[part 3 of 11: package /CANAnalyzer/CommunicationClusters]
AUTOSAR XML (schema 00051)
package /CANAnalyzer/CommunicationClusters  (continued)
  can cluster CAN_FD_IPB_41  (continued)
    can physical channel Channel  (continued)
      frame SeamlessBLEStatusFBD_HM: id 0x10F, frame-length=20, can-addressing-mode=STANDARD, can-frame-rx-behavior=CAN-FD, can-frame-tx-behavior=CAN-FD
        pdu SeamlessBLEStatusFBD_HM: length=20, unused-bit-pattern=0
          signal SeamlessBLEStatusFBD_HM_NumberActiveConnections: start 0, 8 bit, little-endian, data-type-policy=OVERRIDE, base-type=uint8, compu {phys=raw}, range phys 0..252
          signal SeamlessBLEStatusFBD_HM_ConnectionID1: start 8, 8 bit, little-endian, data-type-policy=OVERRIDE, base-type=uint8, compu {phys=raw}, range phys 0..252
          signal SeamlessBLEStatusFBD_HM_ConnectionRSSI1: start 16, 8 bit, little-endian, data-type-policy=OVERRIDE, base-type=uint8, compu {phys=raw*0.5-127; unit dB}, range phys -127..-1
          signal SeamlessBLEStatusFBD_HM_ConnectionID2: start 24, 8 bit, little-endian, data-type-policy=OVERRIDE, base-type=uint8, compu {phys=raw}, range phys 0..252
          signal SeamlessBLEStatusFBD_HM_ConnectionRSSI2: start 32, 8 bit, little-endian, data-type-policy=OVERRIDE, base-type=uint8, compu {phys=raw*0.5-127; unit dB}, range phys -127..-1
          signal SeamlessBLEStatusFBD_HM_ConnectionID3: start 40, 8 bit, little-endian, data-type-policy=OVERRIDE, base-type=uint8, compu {phys=raw}, range phys 0..252
          signal SeamlessBLEStatusFBD_HM_ConnectionRSSI3: start 48, 8 bit, little-endian, data-type-policy=OVERRIDE, base-type=uint8, compu {phys=raw*0.5-127; unit dB}, range phys -127..-1
          signal SeamlessBLEStatusFBD_HM_ConnectionID4: start 56, 8 bit, little-endian, data-type-policy=OVERRIDE, base-type=uint8, compu {phys=raw}, range phys 0..252
          signal SeamlessBLEStatusFBD_HM_ConnectionRSSI4: start 64, 8 bit, little-endian, data-type-policy=OVERRIDE, base-type=uint8, compu {phys=raw*0.5-127; unit dB}, range phys -127..-1
          signal SeamlessBLEStatusFBD_HM_ConnectionID5: start 72, 8 bit, little-endian, data-type-policy=OVERRIDE, base-type=uint8, compu {phys=raw}, range phys 0..252
          signal SeamlessBLEStatusFBD_HM_ConnectionRSSI5: start 80, 8 bit, little-endian, data-type-policy=OVERRIDE, base-type=uint8, compu {phys=raw*0.5-127; unit dB}, range phys -127..-1
          signal SeamlessBLEStatusFBD_HM_ConnectionID6: start 88, 8 bit, little-endian, data-type-policy=OVERRIDE, base-type=uint8, compu {phys=raw}, range phys 0..252
          signal SeamlessBLEStatusFBD_HM_ConnectionRSSI6: start 96, 8 bit, little-endian, data-type-policy=OVERRIDE, base-type=uint8, compu {phys=raw*0.5-127; unit dB}, range phys -127..-1
          signal SeamlessBLEStatusFBD_HM_ConnectionID7: start 104, 8 bit, little-endian, data-type-policy=OVERRIDE, base-type=uint8, compu {phys=raw}, range phys 0..252
          signal SeamlessBLEStatusFBD_HM_ConnectionRSSI7: start 112, 8 bit, little-endian, data-type-policy=OVERRIDE, base-type=uint8, compu {phys=raw*0.5-127; unit dB}, range phys -127..-1
          signal SeamlessBLEStatusFBD_HM_ConnectionID8: start 120, 8 bit, little-endian, data-type-policy=OVERRIDE, base-type=uint8, compu {phys=raw}, range phys 0..252
          signal SeamlessBLEStatusFBD_HM_ConnectionRSSI8: start 128, 8 bit, little-endian, data-type-policy=OVERRIDE, base-type=uint8, compu {phys=raw*0.5-127; unit dB}, range phys -127..-1
      frame SeamlessBLEStatusFBD_HR: id 0x115, frame-length=20, can-addressing-mode=STANDARD, can-frame-rx-behavior=CAN-FD, can-frame-tx-behavior=CAN-FD
        pdu SeamlessBLEStatusFBD_HR: length=20, unused-bit-pattern=0
          signal SeamlessBLEStatusFBD_HR_NumberActiveConnections: start 0, 8 bit, little-endian, data-type-policy=OVERRIDE, base-type=uint8, compu {phys=raw}, range phys 0..252
          signal SeamlessBLEStatusFBD_HR_ConnectionID1: start 8, 8 bit, little-endian, data-type-policy=OVERRIDE, base-type=uint8, compu {phys=raw}, range phys 0..252
          signal SeamlessBLEStatusFBD_HR_ConnectionRSSI1: start 16, 8 bit, little-endian, data-type-policy=OVERRIDE, base-type=uint8, compu {phys=raw*0.5-127; unit dB}, range phys -127..-1
          signal SeamlessBLEStatusFBD_HR_ConnectionID2: start 24, 8 bit, little-endian, data-type-policy=OVERRIDE, base-type=uint8, compu {phys=raw}, range phys 0..252
          signal SeamlessBLEStatusFBD_HR_ConnectionRSSI2: start 32, 8 bit, little-endian, data-type-policy=OVERRIDE, base-type=uint8, compu {phys=raw*0.5-127; unit dB}, range phys -127..-1
          signal SeamlessBLEStatusFBD_HR_ConnectionID3: start 40, 8 bit, little-endian, data-type-policy=OVERRIDE, base-type=uint8, compu {phys=raw}, range phys 0..252
          signal SeamlessBLEStatusFBD_HR_ConnectionRSSI3: start 48, 8 bit, little-endian, data-type-policy=OVERRIDE, base-type=uint8, compu {phys=raw*0.5-127; unit dB}, range phys -127..-1
          signal SeamlessBLEStatusFBD_HR_ConnectionID4: start 56, 8 bit, little-endian, data-type-policy=OVERRIDE, base-type=uint8, compu {phys=raw}, range phys 0..252
          signal SeamlessBLEStatusFBD_HR_ConnectionRSSI4: start 64, 8 bit, little-endian, data-type-policy=OVERRIDE, base-type=uint8, compu {phys=raw*0.5-127; unit dB}, range phys -127..-1
          signal SeamlessBLEStatusFBD_HR_ConnectionID5: start 72, 8 bit, little-endian, data-type-policy=OVERRIDE, base-type=uint8, compu {phys=raw}, range phys 0..252
          signal SeamlessBLEStatusFBD_HR_ConnectionRSSI5: start 80, 8 bit, little-endian, data-type-policy=OVERRIDE, base-type=uint8, compu {phys=raw*0.5-127; unit dB}, range phys -127..-1
          signal SeamlessBLEStatusFBD_HR_ConnectionID6: start 88, 8 bit, little-endian, data-type-policy=OVERRIDE, base-type=uint8, compu {phys=raw}, range phys 0..252
          signal SeamlessBLEStatusFBD_HR_ConnectionRSSI6: start 96, 8 bit, little-endian, data-type-policy=OVERRIDE, base-type=uint8, compu {phys=raw*0.5-127; unit dB}, range phys -127..-1
          signal SeamlessBLEStatusFBD_HR_ConnectionID7: start 104, 8 bit, little-endian, data-type-policy=OVERRIDE, base-type=uint8, compu {phys=raw}, range phys 0..252
          signal SeamlessBLEStatusFBD_HR_ConnectionRSSI7: start 112, 8 bit, little-endian, data-type-policy=OVERRIDE, base-type=uint8, compu {phys=raw*0.5-127; unit dB}, range phys -127..-1
          signal SeamlessBLEStatusFBD_HR_ConnectionID8: start 120, 8 bit, little-endian, data-type-policy=OVERRIDE, base-type=uint8, compu {phys=raw}, range phys 0..252
          signal SeamlessBLEStatusFBD_HR_ConnectionRSSI8: start 128, 8 bit, little-endian, data-type-policy=OVERRIDE, base-type=uint8, compu {phys=raw*0.5-127; unit dB}, range phys -127..-1
      frame SeamlessBLEStatusFBD_Miko: id 0x110, frame-length=20, can-addressing-mode=STANDARD, can-frame-rx-behavior=CAN-FD, can-frame-tx-behavior=CAN-FD
        pdu SeamlessBLEStatusFBD_Miko: length=20, unused-bit-pattern=0
          signal SeamlessBLEStatusFBD_Miko_NumberActiveConnections: start 0, 8 bit, little-endian, data-type-policy=OVERRIDE, base-type=uint8, compu {phys=raw}, range phys 0..252
          signal SeamlessBLEStatusFBD_Miko_ConnectionID1: start 8, 8 bit, little-endian, data-type-policy=OVERRIDE, base-type=uint8, compu {phys=raw}, range phys 0..252
          signal SeamlessBLEStatusFBD_Miko_ConnectionRSSI1: start 16, 8 bit, little-endian, data-type-policy=OVERRIDE, base-type=uint8, compu {phys=raw*0.5-127; unit dB}, range phys -127..-1
          signal SeamlessBLEStatusFBD_Miko_ConnectionID2: start 24, 8 bit, little-endian, data-type-policy=OVERRIDE, base-type=uint8, compu {phys=raw}, range phys 0..252
          signal SeamlessBLEStatusFBD_Miko_ConnectionRSSI2: start 32, 8 bit, little-endian, data-type-policy=OVERRIDE, base-type=uint8, compu {phys=raw*0.5-127; unit dB}, range phys -127..-1
          signal SeamlessBLEStatusFBD_Miko_ConnectionID3: start 40, 8 bit, little-endian, data-type-policy=OVERRIDE, base-type=uint8, compu {phys=raw}, range phys 0..252
          signal SeamlessBLEStatusFBD_Miko_ConnectionRSSI3: start 48, 8 bit, little-endian, data-type-policy=OVERRIDE, base-type=uint8, compu {phys=raw*0.5-127; unit dB}, range phys -127..-1
          signal SeamlessBLEStatusFBD_Miko_ConnectionID4: start 56, 8 bit, little-endian, data-type-policy=OVERRIDE, base-type=uint8, compu {phys=raw}, range phys 0..252
          signal SeamlessBLEStatusFBD_Miko_ConnectionRSSI4: start 64, 8 bit, little-endian, data-type-policy=OVERRIDE, base-type=uint8, compu {phys=raw*0.5-127; unit dB}, range phys -127..-1
          signal SeamlessBLEStatusFBD_Miko_ConnectionID5: start 72, 8 bit, little-endian, data-type-policy=OVERRIDE, base-type=uint8, compu {phys=raw}, range phys 0..252
          signal SeamlessBLEStatusFBD_Miko_ConnectionRSSI5: start 80, 8 bit, little-endian, data-type-policy=OVERRIDE, base-type=uint8, compu {phys=raw*0.5-127; unit dB}, range phys -127..-1
          signal SeamlessBLEStatusFBD_Miko_ConnectionID6: start 88, 8 bit, little-endian, data-type-policy=OVERRIDE, base-type=uint8, compu {phys=raw}, range phys 0..252
          signal SeamlessBLEStatusFBD_Miko_ConnectionRSSI6: start 96, 8 bit, little-endian, data-type-policy=OVERRIDE, base-type=uint8, compu {phys=raw*0.5-127; unit dB}, range phys -127..-1
          signal SeamlessBLEStatusFBD_Miko_ConnectionID7: start 104, 8 bit, little-endian, data-type-policy=OVERRIDE, base-type=uint8, compu {phys=raw}, range phys 0..252
          signal SeamlessBLEStatusFBD_Miko_ConnectionRSSI7: start 112, 8 bit, little-endian, data-type-policy=OVERRIDE, base-type=uint8, compu {phys=raw*0.5-127; unit dB}, range phys -127..-1
          signal SeamlessBLEStatusFBD_Miko_ConnectionID8: start 120, 8 bit, little-endian, data-type-policy=OVERRIDE, base-type=uint8, compu {phys=raw}, range phys 0..252
          signal SeamlessBLEStatusFBD_Miko_ConnectionRSSI8: start 128, 8 bit, little-endian, data-type-policy=OVERRIDE, base-type=uint8, compu {phys=raw*0.5-127; unit dB}, range phys -127..-1
      frame SeamlessBLEStatusFBD_MM: id 0x336, frame-length=20, can-addressing-mode=STANDARD, can-frame-rx-behavior=CAN-FD, can-frame-tx-behavior=CAN-FD
        pdu SeamlessBLEStatusFBD_MM: length=20, unused-bit-pattern=0
          signal SeamlessBLEStatusFBD_MM_NumberActiveConnections: start 0, 8 bit, little-endian, data-type-policy=OVERRIDE, base-type=uint8, compu {phys=raw}, range phys 0..252
          signal SeamlessBLEStatusFBD_MM_ConnectionID1: start 8, 8 bit, little-endian, data-type-policy=OVERRIDE, base-type=uint8, compu {phys=raw}, range phys 0..252
          signal SeamlessBLEStatusFBD_MM_ConnectionRSSI1: start 16, 8 bit, little-endian, data-type-policy=OVERRIDE, base-type=uint8, compu {phys=raw*0.5-127; unit dB}, range phys -127..-1
          signal SeamlessBLEStatusFBD_MM_ConnectionID2: start 24, 8 bit, little-endian, data-type-policy=OVERRIDE, base-type=uint8, compu {phys=raw}, range phys 0..252
          signal SeamlessBLEStatusFBD_MM_ConnectionRSSI2: start 32, 8 bit, little-endian, data-type-policy=OVERRIDE, base-type=uint8, compu {phys=raw*0.5-127; unit dB}, range phys -127..-1
          signal SeamlessBLEStatusFBD_MM_ConnectionID3: start 40, 8 bit, little-endian, data-type-policy=OVERRIDE, base-type=uint8, compu {phys=raw}, range phys 0..252
          signal SeamlessBLEStatusFBD_MM_ConnectionRSSI3: start 48, 8 bit, little-endian, data-type-policy=OVERRIDE, base-type=uint8, compu {phys=raw*0.5-127; unit dB}, range phys -127..-1
          signal SeamlessBLEStatusFBD_MM_ConnectionID4: start 56, 8 bit, little-endian, data-type-policy=OVERRIDE, base-type=uint8, compu {phys=raw}, range phys 0..252
          signal SeamlessBLEStatusFBD_MM_ConnectionRSSI4: start 64, 8 bit, little-endian, data-type-policy=OVERRIDE, base-type=uint8, compu {phys=raw*0.5-127; unit dB}, range phys -127..-1
          signal SeamlessBLEStatusFBD_MM_ConnectionID5: start 72, 8 bit, little-endian, data-type-policy=OVERRIDE, base-type=uint8, compu {phys=raw}, range phys 0..252
          signal SeamlessBLEStatusFBD_MM_ConnectionRSSI5: start 80, 8 bit, little-endian, data-type-policy=OVERRIDE, base-type=uint8, compu {phys=raw*0.5-127; unit dB}, range phys -127..-1
          signal SeamlessBLEStatusFBD_MM_ConnectionID6: start 88, 8 bit, little-endian, data-type-policy=OVERRIDE, base-type=uint8, compu {phys=raw}, range phys 0..252
          signal SeamlessBLEStatusFBD_MM_ConnectionRSSI6: start 96, 8 bit, little-endian, data-type-policy=OVERRIDE, base-type=uint8, compu {phys=raw*0.5-127; unit dB}, range phys -127..-1
          signal SeamlessBLEStatusFBD_MM_ConnectionID7: start 104, 8 bit, little-endian, data-type-policy=OVERRIDE, base-type=uint8, compu {phys=raw}, range phys 0..252
          signal SeamlessBLEStatusFBD_MM_ConnectionRSSI7: start 112, 8 bit, little-endian, data-type-policy=OVERRIDE, base-type=uint8, compu {phys=raw*0.5-127; unit dB}, range phys -127..-1
          signal SeamlessBLEStatusFBD_MM_ConnectionID8: start 120, 8 bit, little-endian, data-type-policy=OVERRIDE, base-type=uint8, compu {phys=raw}, range phys 0..252
          signal SeamlessBLEStatusFBD_MM_ConnectionRSSI8: start 128, 8 bit, little-endian, data-type-policy=OVERRIDE, base-type=uint8, compu {phys=raw*0.5-127; unit dB}, range phys -127..-1
      frame SeamlessBLEStatusFBD_Trunk: id 0x111, frame-length=20, can-addressing-mode=STANDARD, can-frame-rx-behavior=CAN-FD, can-frame-tx-behavior=CAN-FD
        pdu SeamlessBLEStatusFBD_Trunk: length=20, unused-bit-pattern=0
          signal SeamlessBLEStatusFBD_Trunk_NumberActiveConnections: start 0, 8 bit, little-endian, data-type-policy=OVERRIDE, base-type=uint8, compu {phys=raw}, range phys 0..252
          signal SeamlessBLEStatusFBD_Trunk_ConnectionID1: start 8, 8 bit, little-endian, data-type-policy=OVERRIDE, base-type=uint8, compu {phys=raw}, range phys 0..252
          signal SeamlessBLEStatusFBD_Trunk_ConnectionRSSI1: start 16, 8 bit, little-endian, data-type-policy=OVERRIDE, base-type=uint8, compu {phys=raw*0.5-127; unit dB}, range phys -127..-1
          signal SeamlessBLEStatusFBD_Trunk_ConnectionID2: start 24, 8 bit, little-endian, data-type-policy=OVERRIDE, base-type=uint8, compu {phys=raw}, range phys 0..252
          signal SeamlessBLEStatusFBD_Trunk_ConnectionRSSI2: start 32, 8 bit, little-endian, data-type-policy=OVERRIDE, base-type=uint8, compu {phys=raw*0.5-127; unit dB}, range phys -127..-1
          signal SeamlessBLEStatusFBD_Trunk_ConnectionID3: start 40, 8 bit, little-endian, data-type-policy=OVERRIDE, base-type=uint8, compu {phys=raw}, range phys 0..252
          signal SeamlessBLEStatusFBD_Trunk_ConnectionRSSI3: start 48, 8 bit, little-endian, data-type-policy=OVERRIDE, base-type=uint8, compu {phys=raw*0.5-127; unit dB}, range phys -127..-1
          signal SeamlessBLEStatusFBD_Trunk_ConnectionID4: start 56, 8 bit, little-endian, data-type-policy=OVERRIDE, base-type=uint8, compu {phys=raw}, range phys 0..252
          signal SeamlessBLEStatusFBD_Trunk_ConnectionRSSI4: start 64, 8 bit, little-endian, data-type-policy=OVERRIDE, base-type=uint8, compu {phys=raw*0.5-127; unit dB}, range phys -127..-1
          signal SeamlessBLEStatusFBD_Trunk_ConnectionID5: start 72, 8 bit, little-endian, data-type-policy=OVERRIDE, base-type=uint8, compu {phys=raw}, range phys 0..252
          signal SeamlessBLEStatusFBD_Trunk_ConnectionRSSI5: start 80, 8 bit, little-endian, data-type-policy=OVERRIDE, base-type=uint8, compu {phys=raw*0.5-127; unit dB}, range phys -127..-1
          signal SeamlessBLEStatusFBD_Trunk_ConnectionID6: start 88, 8 bit, little-endian, data-type-policy=OVERRIDE, base-type=uint8, compu {phys=raw}, range phys 0..252
          signal SeamlessBLEStatusFBD_Trunk_ConnectionRSSI6: start 96, 8 bit, little-endian, data-type-policy=OVERRIDE, base-type=uint8, compu {phys=raw*0.5-127; unit dB}, range phys -127..-1
          signal SeamlessBLEStatusFBD_Trunk_ConnectionID7: start 104, 8 bit, little-endian, data-type-policy=OVERRIDE, base-type=uint8, compu {phys=raw}, range phys 0..252
          signal SeamlessBLEStatusFBD_Trunk_ConnectionRSSI7: start 112, 8 bit, little-endian, data-type-policy=OVERRIDE, base-type=uint8, compu {phys=raw*0.5-127; unit dB}, range phys -127..-1
          signal SeamlessBLEStatusFBD_Trunk_ConnectionID8: start 120, 8 bit, little-endian, data-type-policy=OVERRIDE, base-type=uint8, compu {phys=raw}, range phys 0..252
          signal SeamlessBLEStatusFBD_Trunk_ConnectionRSSI8: start 128, 8 bit, little-endian, data-type-policy=OVERRIDE, base-type=uint8, compu {phys=raw*0.5-127; unit dB}, range phys -127..-1
      frame SeamlessBLEStatusFBD_VL: id 0x112, frame-length=20, can-addressing-mode=STANDARD, can-frame-rx-behavior=CAN-FD, can-frame-tx-behavior=CAN-FD
        pdu SeamlessBLEStatusFBD_VL: length=20, unused-bit-pattern=0
          signal SeamlessBLEStatusFBD_VL_NumberActiveConnections: start 0, 8 bit, little-endian, data-type-policy=OVERRIDE, base-type=uint8, compu {phys=raw}, range phys 0..252
          signal SeamlessBLEStatusFBD_VL_ConnectionID1: start 8, 8 bit, little-endian, data-type-policy=OVERRIDE, base-type=uint8, compu {phys=raw}, range phys 0..252
          signal SeamlessBLEStatusFBD_VL_ConnectionRSSI1: start 16, 8 bit, little-endian, data-type-policy=OVERRIDE, base-type=uint8, compu {phys=raw*0.5-127; unit dB}, range phys -127..-1
          signal SeamlessBLEStatusFBD_VL_ConnectionID2: start 24, 8 bit, little-endian, data-type-policy=OVERRIDE, base-type=uint8, compu {phys=raw}, range phys 0..252
          signal SeamlessBLEStatusFBD_VL_ConnectionRSSI2: start 32, 8 bit, little-endian, data-type-policy=OVERRIDE, base-type=uint8, compu {phys=raw*0.5-127; unit dB}, range phys -127..-1
          signal SeamlessBLEStatusFBD_VL_ConnectionID3: start 40, 8 bit, little-endian, data-type-policy=OVERRIDE, base-type=uint8, compu {phys=raw}, range phys 0..252
          signal SeamlessBLEStatusFBD_VL_ConnectionRSSI3: start 48, 8 bit, little-endian, data-type-policy=OVERRIDE, base-type=uint8, compu {phys=raw*0.5-127; unit dB}, range phys -127..-1
          signal SeamlessBLEStatusFBD_VL_ConnectionID4: start 56, 8 bit, little-endian, data-type-policy=OVERRIDE, base-type=uint8, compu {phys=raw}, range phys 0..252
          signal SeamlessBLEStatusFBD_VL_ConnectionRSSI4: start 64, 8 bit, little-endian, data-type-policy=OVERRIDE, base-type=uint8, compu {phys=raw*0.5-127; unit dB}, range phys -127..-1
          signal SeamlessBLEStatusFBD_VL_ConnectionID5: start 72, 8 bit, little-endian, data-type-policy=OVERRIDE, base-type=uint8, compu {phys=raw}, range phys 0..252
          signal SeamlessBLEStatusFBD_VL_ConnectionRSSI5: start 80, 8 bit, little-endian, data-type-policy=OVERRIDE, base-type=uint8, compu {phys=raw*0.5-127; unit dB}, range phys -127..-1
          signal SeamlessBLEStatusFBD_VL_ConnectionID6: start 88, 8 bit, little-endian, data-type-policy=OVERRIDE, base-type=uint8, compu {phys=raw}, range phys 0..252
          signal SeamlessBLEStatusFBD_VL_ConnectionRSSI6: start 96, 8 bit, little-endian, data-type-policy=OVERRIDE, base-type=uint8, compu {phys=raw*0.5-127; unit dB}, range phys -127..-1
          signal SeamlessBLEStatusFBD_VL_ConnectionID7: start 104, 8 bit, little-endian, data-type-policy=OVERRIDE, base-type=uint8, compu {phys=raw}, range phys 0..252
          signal SeamlessBLEStatusFBD_VL_ConnectionRSSI7: start 112, 8 bit, little-endian, data-type-policy=OVERRIDE, base-type=uint8, compu {phys=raw*0.5-127; unit dB}, range phys -127..-1
          signal SeamlessBLEStatusFBD_VL_ConnectionID8: start 120, 8 bit, little-endian, data-type-policy=OVERRIDE, base-type=uint8, compu {phys=raw}, range phys 0..252
          signal SeamlessBLEStatusFBD_VL_ConnectionRSSI8: start 128, 8 bit, little-endian, data-type-policy=OVERRIDE, base-type=uint8, compu {phys=raw*0.5-127; unit dB}, range phys -127..-1
      frame SeamlessBLEStatusFBD_VM: id 0x10E, frame-length=20, can-addressing-mode=STANDARD, can-frame-rx-behavior=CAN-FD, can-frame-tx-behavior=CAN-FD
        pdu SeamlessBLEStatusFBD_VM: length=20, unused-bit-pattern=0
          signal SeamlessBLEStatusFBD_VM_NumberActiveConnections: start 0, 8 bit, little-endian, data-type-policy=OVERRIDE, base-type=uint8, compu {phys=raw}, range phys 0..252
          signal SeamlessBLEStatusFBD_VM_ConnectionID1: start 8, 8 bit, little-endian, data-type-policy=OVERRIDE, base-type=uint8, compu {phys=raw}, range phys 0..252
          signal SeamlessBLEStatusFBD_VM_ConnectionRSSI1: start 16, 8 bit, little-endian, data-type-policy=OVERRIDE, base-type=uint8, compu {phys=raw*0.5-127; unit dB}, range phys -127..-1
          signal SeamlessBLEStatusFBD_VM_ConnectionID2: start 24, 8 bit, little-endian, data-type-policy=OVERRIDE, base-type=uint8, compu {phys=raw}, range phys 0..252
          signal SeamlessBLEStatusFBD_VM_ConnectionRSSI2: start 32, 8 bit, little-endian, data-type-policy=OVERRIDE, base-type=uint8, compu {phys=raw*0.5-127; unit dB}, range phys -127..-1
          signal SeamlessBLEStatusFBD_VM_ConnectionID3: start 40, 8 bit, little-endian, data-type-policy=OVERRIDE, base-type=uint8, compu {phys=raw}, range phys 0..252
          signal SeamlessBLEStatusFBD_VM_ConnectionRSSI3: start 48, 8 bit, little-endian, data-type-policy=OVERRIDE, base-type=uint8, compu {phys=raw*0.5-127; unit dB}, range phys -127..-1
          signal SeamlessBLEStatusFBD_VM_ConnectionID4: start 56, 8 bit, little-endian, data-type-policy=OVERRIDE, base-type=uint8, compu {phys=raw}, range phys 0..252
          signal SeamlessBLEStatusFBD_VM_ConnectionRSSI4: start 64, 8 bit, little-endian, data-type-policy=OVERRIDE, base-type=uint8, compu {phys=raw*0.5-127; unit dB}, range phys -127..-1
          signal SeamlessBLEStatusFBD_VM_ConnectionID5: start 72, 8 bit, little-endian, data-type-policy=OVERRIDE, base-type=uint8, compu {phys=raw}, range phys 0..252
          signal SeamlessBLEStatusFBD_VM_ConnectionRSSI5: start 80, 8 bit, little-endian, data-type-policy=OVERRIDE, base-type=uint8, compu {phys=raw*0.5-127; unit dB}, range phys -127..-1
          signal SeamlessBLEStatusFBD_VM_ConnectionID6: start 88, 8 bit, little-endian, data-type-policy=OVERRIDE, base-type=uint8, compu {phys=raw}, range phys 0..252
          signal SeamlessBLEStatusFBD_VM_ConnectionRSSI6: start 96, 8 bit, little-endian, data-type-policy=OVERRIDE, base-type=uint8, compu {phys=raw*0.5-127; unit dB}, range phys -127..-1
          signal SeamlessBLEStatusFBD_VM_ConnectionID7: start 104, 8 bit, little-endian, data-type-policy=OVERRIDE, base-type=uint8, compu {phys=raw}, range phys 0..252
          signal SeamlessBLEStatusFBD_VM_ConnectionRSSI7: start 112, 8 bit, little-endian, data-type-policy=OVERRIDE, base-type=uint8, compu {phys=raw*0.5-127; unit dB}, range phys -127..-1
          signal SeamlessBLEStatusFBD_VM_ConnectionID8: start 120, 8 bit, little-endian, data-type-policy=OVERRIDE, base-type=uint8, compu {phys=raw}, range phys 0..252
          signal SeamlessBLEStatusFBD_VM_ConnectionRSSI8: start 128, 8 bit, little-endian, data-type-policy=OVERRIDE, base-type=uint8, compu {phys=raw*0.5-127; unit dB}, range phys -127..-1
      frame SeamlessBLEStatusFBD_VR: id 0x113, frame-length=20, can-addressing-mode=STANDARD, can-frame-rx-behavior=CAN-FD, can-frame-tx-behavior=CAN-FD
        pdu SeamlessBLEStatusFBD_VR: length=20, unused-bit-pattern=0
          signal SeamlessBLEStatusFBD_VR_NumberActiveConnections: start 0, 8 bit, little-endian, data-type-policy=OVERRIDE, base-type=uint8, compu {phys=raw}, range phys 0..252
          signal SeamlessBLEStatusFBD_VR_ConnectionID1: start 8, 8 bit, little-endian, data-type-policy=OVERRIDE, base-type=uint8, compu {phys=raw}, range phys 0..252
          signal SeamlessBLEStatusFBD_VR_ConnectionRSSI1: start 16, 8 bit, little-endian, data-type-policy=OVERRIDE, base-type=uint8, compu {phys=raw*0.5-127; unit dB}, range phys -127..-1
          signal SeamlessBLEStatusFBD_VR_ConnectionID2: start 24, 8 bit, little-endian, data-type-policy=OVERRIDE, base-type=uint8, compu {phys=raw}, range phys 0..252
          signal SeamlessBLEStatusFBD_VR_ConnectionRSSI2: start 32, 8 bit, little-endian, data-type-policy=OVERRIDE, base-type=uint8, compu {phys=raw*0.5-127; unit dB}, range phys -127..-1
          signal SeamlessBLEStatusFBD_VR_ConnectionID3: start 40, 8 bit, little-endian, data-type-policy=OVERRIDE, base-type=uint8, compu {phys=raw}, range phys 0..252
          signal SeamlessBLEStatusFBD_VR_ConnectionRSSI3: start 48, 8 bit, little-endian, data-type-policy=OVERRIDE, base-type=uint8, compu {phys=raw*0.5-127; unit dB}, range phys -127..-1
          signal SeamlessBLEStatusFBD_VR_ConnectionID4: start 56, 8 bit, little-endian, data-type-policy=OVERRIDE, base-type=uint8, compu {phys=raw}, range phys 0..252
          signal SeamlessBLEStatusFBD_VR_ConnectionRSSI4: start 64, 8 bit, little-endian, data-type-policy=OVERRIDE, base-type=uint8, compu {phys=raw*0.5-127; unit dB}, range phys -127..-1
          signal SeamlessBLEStatusFBD_VR_ConnectionID5: start 72, 8 bit, little-endian, data-type-policy=OVERRIDE, base-type=uint8, compu {phys=raw}, range phys 0..252
          signal SeamlessBLEStatusFBD_VR_ConnectionRSSI5: start 80, 8 bit, little-endian, data-type-policy=OVERRIDE, base-type=uint8, compu {phys=raw*0.5-127; unit dB}, range phys -127..-1
          signal SeamlessBLEStatusFBD_VR_ConnectionID6: start 88, 8 bit, little-endian, data-type-policy=OVERRIDE, base-type=uint8, compu {phys=raw}, range phys 0..252
          signal SeamlessBLEStatusFBD_VR_ConnectionRSSI6: start 96, 8 bit, little-endian, data-type-policy=OVERRIDE, base-type=uint8, compu {phys=raw*0.5-127; unit dB}, range phys -127..-1
          signal SeamlessBLEStatusFBD_VR_ConnectionID7: start 104, 8 bit, little-endian, data-type-policy=OVERRIDE, base-type=uint8, compu {phys=raw}, range phys 0..252
          signal SeamlessBLEStatusFBD_VR_ConnectionRSSI7: start 112, 8 bit, little-endian, data-type-policy=OVERRIDE, base-type=uint8, compu {phys=raw*0.5-127; unit dB}, range phys -127..-1
          signal SeamlessBLEStatusFBD_VR_ConnectionID8: start 120, 8 bit, little-endian, data-type-policy=OVERRIDE, base-type=uint8, compu {phys=raw}, range phys 0..252
          signal SeamlessBLEStatusFBD_VR_ConnectionRSSI8: start 128, 8 bit, little-endian, data-type-policy=OVERRIDE, base-type=uint8, compu {phys=raw*0.5-127; unit dB}, range phys -127..-1
      frame StatusBindingFBD_HL: id 0x272, frame-length=64, can-addressing-mode=STANDARD, can-frame-rx-behavior=CAN-FD, can-frame-tx-behavior=CAN-FD
        pdu StatusBindingFBD_HL: length=64, unused-bit-pattern=0
          signal StatusBindingFBD_HL_BindingStatus: start 0, 8 bit, little-endian, data-type-policy=OVERRIDE, base-type=uint8, compu {phys=raw}, range phys 0..252
          signal StatusBindingFBD_HL_BindingCounter: start 8, 8 bit, little-endian, data-type-policy=OVERRIDE, base-type=uint8, compu {phys=raw}, range phys 0..252
          signal StatusBindingFBD_HL_BindingSequence: start 16, 8 bit, little-endian, data-type-policy=OVERRIDE, base-type=uint8, compu {phys=raw}, range phys 0..252
          signal StatusBindingFBD_HL_Data00: start 24, 8 bit, little-endian, data-type-policy=OVERRIDE, base-type=uint8, compu {phys=raw}, range phys 0..255
          signal StatusBindingFBD_HL_Data01: start 32, 8 bit, little-endian, data-type-policy=OVERRIDE, base-type=uint8, compu {phys=raw}, range phys 0..255
          signal StatusBindingFBD_HL_Data02: start 40, 8 bit, little-endian, data-type-policy=OVERRIDE, base-type=uint8, compu {phys=raw}, range phys 0..255
          signal StatusBindingFBD_HL_Data03: start 48, 8 bit, little-endian, data-type-policy=OVERRIDE, base-type=uint8, compu {phys=raw}, range phys 0..255
          signal StatusBindingFBD_HL_Data04: start 56, 8 bit, little-endian, data-type-policy=OVERRIDE, base-type=uint8, compu {phys=raw}, range phys 0..255
          signal StatusBindingFBD_HL_Data05: start 64, 8 bit, little-endian, data-type-policy=OVERRIDE, base-type=uint8, compu {phys=raw}, range phys 0..255
          signal StatusBindingFBD_HL_Data06: start 72, 8 bit, little-endian, data-type-policy=OVERRIDE, base-type=uint8, compu {phys=raw}, range phys 0..255
          signal StatusBindingFBD_HL_Data07: start 80, 8 bit, little-endian, data-type-policy=OVERRIDE, base-type=uint8, compu {phys=raw}, range phys 0..255
          signal StatusBindingFBD_HL_Data08: start 88, 8 bit, little-endian, data-type-policy=OVERRIDE, base-type=uint8, compu {phys=raw}, range phys 0..255
          signal StatusBindingFBD_HL_Data09: start 96, 8 bit, little-endian, data-type-policy=OVERRIDE, base-type=uint8, compu {phys=raw}, range phys 0..255
          signal StatusBindingFBD_HL_Data10: start 104, 8 bit, little-endian, data-type-policy=OVERRIDE, base-type=uint8, compu {phys=raw}, range phys 0..255
          signal StatusBindingFBD_HL_Data11: start 112, 8 bit, little-endian, data-type-policy=OVERRIDE, base-type=uint8, compu {phys=raw}, range phys 0..255
          signal StatusBindingFBD_HL_Data12: start 120, 8 bit, little-endian, data-type-policy=OVERRIDE, base-type=uint8, compu {phys=raw}, range phys 0..255
          signal StatusBindingFBD_HL_Data13: start 128, 8 bit, little-endian, data-type-policy=OVERRIDE, base-type=uint8, compu {phys=raw}, range phys 0..255
          signal StatusBindingFBD_HL_Data14: start 136, 8 bit, little-endian, data-type-policy=OVERRIDE, base-type=uint8, compu {phys=raw}, range phys 0..255
          signal StatusBindingFBD_HL_Data15: start 144, 8 bit, little-endian, data-type-policy=OVERRIDE, base-type=uint8, compu {phys=raw}, range phys 0..255
          signal StatusBindingFBD_HL_Data16: start 152, 8 bit, little-endian, data-type-policy=OVERRIDE, base-type=uint8, compu {phys=raw}, range phys 0..255
          signal StatusBindingFBD_HL_Data17: start 160, 8 bit, little-endian, data-type-policy=OVERRIDE, base-type=uint8, compu {phys=raw}, range phys 0..255
          signal StatusBindingFBD_HL_Data18: start 168, 8 bit, little-endian, data-type-policy=OVERRIDE, base-type=uint8, compu {phys=raw}, range phys 0..255
          signal StatusBindingFBD_HL_Data19: start 176, 8 bit, little-endian, data-type-policy=OVERRIDE, base-type=uint8, compu {phys=raw}, range phys 0..255
          signal StatusBindingFBD_HL_Data20: start 184, 8 bit, little-endian, data-type-policy=OVERRIDE, base-type=uint8, compu {phys=raw}, range phys 0..255
          signal StatusBindingFBD_HL_Data21: start 192, 8 bit, little-endian, data-type-policy=OVERRIDE, base-type=uint8, compu {phys=raw}, range phys 0..255
          signal StatusBindingFBD_HL_Data22: start 200, 8 bit, little-endian, data-type-policy=OVERRIDE, base-type=uint8, compu {phys=raw}, range phys 0..255
          signal StatusBindingFBD_HL_Data23: start 208, 8 bit, little-endian, data-type-policy=OVERRIDE, base-type=uint8, compu {phys=raw}, range phys 0..255
          signal StatusBindingFBD_HL_Data24: start 216, 8 bit, little-endian, data-type-policy=OVERRIDE, base-type=uint8, compu {phys=raw}, range phys 0..255
          signal StatusBindingFBD_HL_Data25: start 224, 8 bit, little-endian, data-type-policy=OVERRIDE, base-type=uint8, compu {phys=raw}, range phys 0..255
          signal StatusBindingFBD_HL_Data26: start 232, 8 bit, little-endian, data-type-policy=OVERRIDE, base-type=uint8, compu {phys=raw}, range phys 0..255
          signal StatusBindingFBD_HL_Data27: start 240, 8 bit, little-endian, data-type-policy=OVERRIDE, base-type=uint8, compu {phys=raw}, range phys 0..255
          signal StatusBindingFBD_HL_Data28: start 248, 8 bit, little-endian, data-type-policy=OVERRIDE, base-type=uint8, compu {phys=raw}, range phys 0..255
          signal StatusBindingFBD_HL_Data29: start 256, 8 bit, little-endian, data-type-policy=OVERRIDE, base-type=uint8, compu {phys=raw}, range phys 0..255
          signal StatusBindingFBD_HL_Data30: start 264, 8 bit, little-endian, data-type-policy=OVERRIDE, base-type=uint8, compu {phys=raw}, range phys 0..255
          signal StatusBindingFBD_HL_Data31: start 272, 8 bit, little-endian, data-type-policy=OVERRIDE, base-type=uint8, compu {phys=raw}, range phys 0..255
          signal StatusBindingFBD_HL_Data32: start 280, 8 bit, little-endian, data-type-policy=OVERRIDE, base-type=uint8, compu {phys=raw}, range phys 0..255
          signal StatusBindingFBD_HL_Data33: start 288, 8 bit, little-endian, data-type-policy=OVERRIDE, base-type=uint8, compu {phys=raw}, range phys 0..255
          signal StatusBindingFBD_HL_Data34: start 296, 8 bit, little-endian, data-type-policy=OVERRIDE, base-type=uint8, compu {phys=raw}, range phys 0..255
          signal StatusBindingFBD_HL_Data35: start 304, 8 bit, little-endian, data-type-policy=OVERRIDE, base-type=uint8, compu {phys=raw}, range phys 0..255
          signal StatusBindingFBD_HL_Data36: start 312, 8 bit, little-endian, data-type-policy=OVERRIDE, base-type=uint8, compu {phys=raw}, range phys 0..255
          signal StatusBindingFBD_HL_Data37: start 320, 8 bit, little-endian, data-type-policy=OVERRIDE, base-type=uint8, compu {phys=raw}, range phys 0..255
          signal StatusBindingFBD_HL_Data38: start 328, 8 bit, little-endian, data-type-policy=OVERRIDE, base-type=uint8, compu {phys=raw}, range phys 0..255
          signal StatusBindingFBD_HL_Data39: start 336, 8 bit, little-endian, data-type-policy=OVERRIDE, base-type=uint8, compu {phys=raw}, range phys 0..255
          signal StatusBindingFBD_HL_Data40: start 344, 8 bit, little-endian, data-type-policy=OVERRIDE, base-type=uint8, compu {phys=raw}, range phys 0..255
          signal StatusBindingFBD_HL_Data41: start 352, 8 bit, little-endian, data-type-policy=OVERRIDE, base-type=uint8, compu {phys=raw}, range phys 0..255
          signal StatusBindingFBD_HL_Data42: start 360, 8 bit, little-endian, data-type-policy=OVERRIDE, base-type=uint8, compu {phys=raw}, range phys 0..255
          signal StatusBindingFBD_HL_Data43: start 368, 8 bit, little-endian, data-type-policy=OVERRIDE, base-type=uint8, compu {phys=raw}, range phys 0..255
          signal StatusBindingFBD_HL_Data44: start 376, 8 bit, little-endian, data-type-policy=OVERRIDE, base-type=uint8, compu {phys=raw}, range phys 0..255
          signal StatusBindingFBD_HL_Data45: start 384, 8 bit, little-endian, data-type-policy=OVERRIDE, base-type=uint8, compu {phys=raw}, range phys 0..255
          signal StatusBindingFBD_HL_Data46: start 392, 8 bit, little-endian, data-type-policy=OVERRIDE, base-type=uint8, compu {phys=raw}, range phys 0..255
          signal StatusBindingFBD_HL_Data47: start 400, 8 bit, little-endian, data-type-policy=OVERRIDE, base-type=uint8, compu {phys=raw}, range phys 0..255
          signal StatusBindingFBD_HL_Data48: start 408, 8 bit, little-endian, data-type-policy=OVERRIDE, base-type=uint8, compu {phys=raw}, range phys 0..255
          signal StatusBindingFBD_HL_Data49: start 416, 8 bit, little-endian, data-type-policy=OVERRIDE, base-type=uint8, compu {phys=raw}, range phys 0..255
          signal StatusBindingFBD_HL_Data50: start 424, 8 bit, little-endian, data-type-policy=OVERRIDE, base-type=uint8, compu {phys=raw}, range phys 0..255
          signal StatusBindingFBD_HL_Data51: start 432, 8 bit, little-endian, data-type-policy=OVERRIDE, base-type=uint8, compu {phys=raw}, range phys 0..255
          signal StatusBindingFBD_HL_Data52: start 440, 8 bit, little-endian, data-type-policy=OVERRIDE, base-type=uint8, compu {phys=raw}, range phys 0..255
          signal StatusBindingFBD_HL_Data53: start 448, 8 bit, little-endian, data-type-policy=OVERRIDE, base-type=uint8, compu {phys=raw}, range phys 0..255
          signal StatusBindingFBD_HL_Data54: start 456, 8 bit, little-endian, data-type-policy=OVERRIDE, base-type=uint8, compu {phys=raw}, range phys 0..255
          signal StatusBindingFBD_HL_Data55: start 464, 8 bit, little-endian, data-type-policy=OVERRIDE, base-type=uint8, compu {phys=raw}, range phys 0..255
          signal StatusBindingFBD_HL_Data56: start 472, 8 bit, little-endian, data-type-policy=OVERRIDE, base-type=uint8, compu {phys=raw}, range phys 0..255
          signal StatusBindingFBD_HL_Data57: start 480, 8 bit, little-endian, data-type-policy=OVERRIDE, base-type=uint8, compu {phys=raw}, range phys 0..255
          signal StatusBindingFBD_HL_Data58: start 488, 8 bit, little-endian, data-type-policy=OVERRIDE, base-type=uint8, compu {phys=raw}, range phys 0..255
          signal StatusBindingFBD_HL_Data59: start 496, 8 bit, little-endian, data-type-policy=OVERRIDE, base-type=uint8, compu {phys=raw}, range phys 0..255
          signal StatusBindingFBD_HL_Data60: start 504, 8 bit, little-endian, data-type-policy=OVERRIDE, base-type=uint8, compu {phys=raw}, range phys 0..255
      frame StatusBindingFBD_HM: id 0x26D, frame-length=64, can-addressing-mode=STANDARD, can-frame-rx-behavior=CAN-FD, can-frame-tx-behavior=CAN-FD
        pdu StatusBindingFBD_HM: length=64, unused-bit-pattern=0
          signal StatusBindingFBD_HM_BindingStatus: start 0, 8 bit, little-endian, data-type-policy=OVERRIDE, base-type=uint8, compu {phys=raw}, range phys 0..252
          signal StatusBindingFBD_HM_BindingCounter: start 8, 8 bit, little-endian, data-type-policy=OVERRIDE, base-type=uint8, compu {phys=raw}, range phys 0..252
          signal StatusBindingFBD_HM_BindingSequence: start 16, 8 bit, little-endian, data-type-policy=OVERRIDE, base-type=uint8, compu {phys=raw}, range phys 0..252
          signal StatusBindingFBD_HM_Data00: start 24, 8 bit, little-endian, data-type-policy=OVERRIDE, base-type=uint8, compu {phys=raw}, range phys 0..255
          signal StatusBindingFBD_HM_Data01: start 32, 8 bit, little-endian, data-type-policy=OVERRIDE, base-type=uint8, compu {phys=raw}, range phys 0..255
          signal StatusBindingFBD_HM_Data02: start 40, 8 bit, little-endian, data-type-policy=OVERRIDE, base-type=uint8, compu {phys=raw}, range phys 0..255
          signal StatusBindingFBD_HM_Data03: start 48, 8 bit, little-endian, data-type-policy=OVERRIDE, base-type=uint8, compu {phys=raw}, range phys 0..255
          signal StatusBindingFBD_HM_Data04: start 56, 8 bit, little-endian, data-type-policy=OVERRIDE, base-type=uint8, compu {phys=raw}, range phys 0..255
          signal StatusBindingFBD_HM_Data05: start 64, 8 bit, little-endian, data-type-policy=OVERRIDE, base-type=uint8, compu {phys=raw}, range phys 0..255
          signal StatusBindingFBD_HM_Data06: start 72, 8 bit, little-endian, data-type-policy=OVERRIDE, base-type=uint8, compu {phys=raw}, range phys 0..255
          signal StatusBindingFBD_HM_Data07: start 80, 8 bit, little-endian, data-type-policy=OVERRIDE, base-type=uint8, compu {phys=raw}, range phys 0..255
          signal StatusBindingFBD_HM_Data08: start 88, 8 bit, little-endian, data-type-policy=OVERRIDE, base-type=uint8, compu {phys=raw}, range phys 0..255
          signal StatusBindingFBD_HM_Data09: start 96, 8 bit, little-endian, data-type-policy=OVERRIDE, base-type=uint8, compu {phys=raw}, range phys 0..255
          signal StatusBindingFBD_HM_Data10: start 104, 8 bit, little-endian, data-type-policy=OVERRIDE, base-type=uint8, compu {phys=raw}, range phys 0..255
          signal StatusBindingFBD_HM_Data11: start 112, 8 bit, little-endian, data-type-policy=OVERRIDE, base-type=uint8, compu {phys=raw}, range phys 0..255
          signal StatusBindingFBD_HM_Data12: start 120, 8 bit, little-endian, data-type-policy=OVERRIDE, base-type=uint8, compu {phys=raw}, range phys 0..255
          signal StatusBindingFBD_HM_Data13: start 128, 8 bit, little-endian, data-type-policy=OVERRIDE, base-type=uint8, compu {phys=raw}, range phys 0..255
          signal StatusBindingFBD_HM_Data14: start 136, 8 bit, little-endian, data-type-policy=OVERRIDE, base-type=uint8, compu {phys=raw}, range phys 0..255
          signal StatusBindingFBD_HM_Data15: start 144, 8 bit, little-endian, data-type-policy=OVERRIDE, base-type=uint8, compu {phys=raw}, range phys 0..255
          signal StatusBindingFBD_HM_Data16: start 152, 8 bit, little-endian, data-type-policy=OVERRIDE, base-type=uint8, compu {phys=raw}, range phys 0..255
          signal StatusBindingFBD_HM_Data17: start 160, 8 bit, little-endian, data-type-policy=OVERRIDE, base-type=uint8, compu {phys=raw}, range phys 0..255
          signal StatusBindingFBD_HM_Data18: start 168, 8 bit, little-endian, data-type-policy=OVERRIDE, base-type=uint8, compu {phys=raw}, range phys 0..255
          signal StatusBindingFBD_HM_Data19: start 176, 8 bit, little-endian, data-type-policy=OVERRIDE, base-type=uint8, compu {phys=raw}, range phys 0..255
          signal StatusBindingFBD_HM_Data20: start 184, 8 bit, little-endian, data-type-policy=OVERRIDE, base-type=uint8, compu {phys=raw}, range phys 0..255
          signal StatusBindingFBD_HM_Data21: start 192, 8 bit, little-endian, data-type-policy=OVERRIDE, base-type=uint8, compu {phys=raw}, range phys 0..255
          signal StatusBindingFBD_HM_Data22: start 200, 8 bit, little-endian, data-type-policy=OVERRIDE, base-type=uint8, compu {phys=raw}, range phys 0..255
          signal StatusBindingFBD_HM_Data23: start 208, 8 bit, little-endian, data-type-policy=OVERRIDE, base-type=uint8, compu {phys=raw}, range phys 0..255
          signal StatusBindingFBD_HM_Data24: start 216, 8 bit, little-endian, data-type-policy=OVERRIDE, base-type=uint8, compu {phys=raw}, range phys 0..255
          signal StatusBindingFBD_HM_Data25: start 224, 8 bit, little-endian, data-type-policy=OVERRIDE, base-type=uint8, compu {phys=raw}, range phys 0..255
          signal StatusBindingFBD_HM_Data26: start 232, 8 bit, little-endian, data-type-policy=OVERRIDE, base-type=uint8, compu {phys=raw}, range phys 0..255
          signal StatusBindingFBD_HM_Data27: start 240, 8 bit, little-endian, data-type-policy=OVERRIDE, base-type=uint8, compu {phys=raw}, range phys 0..255
          signal StatusBindingFBD_HM_Data28: start 248, 8 bit, little-endian, data-type-policy=OVERRIDE, base-type=uint8, compu {phys=raw}, range phys 0..255
          signal StatusBindingFBD_HM_Data29: start 256, 8 bit, little-endian, data-type-policy=OVERRIDE, base-type=uint8, compu {phys=raw}, range phys 0..255
          signal StatusBindingFBD_HM_Data30: start 264, 8 bit, little-endian, data-type-policy=OVERRIDE, base-type=uint8, compu {phys=raw}, range phys 0..255
          signal StatusBindingFBD_HM_Data31: start 272, 8 bit, little-endian, data-type-policy=OVERRIDE, base-type=uint8, compu {phys=raw}, range phys 0..255
          signal StatusBindingFBD_HM_Data32: start 280, 8 bit, little-endian, data-type-policy=OVERRIDE, base-type=uint8, compu {phys=raw}, range phys 0..255
          signal StatusBindingFBD_HM_Data33: start 288, 8 bit, little-endian, data-type-policy=OVERRIDE, base-type=uint8, compu {phys=raw}, range phys 0..255
          signal StatusBindingFBD_HM_Data34: start 296, 8 bit, little-endian, data-type-policy=OVERRIDE, base-type=uint8, compu {phys=raw}, range phys 0..255
          signal StatusBindingFBD_HM_Data35: start 304, 8 bit, little-endian, data-type-policy=OVERRIDE, base-type=uint8, compu {phys=raw}, range phys 0..255
          signal StatusBindingFBD_HM_Data36: start 312, 8 bit, little-endian, data-type-policy=OVERRIDE, base-type=uint8, compu {phys=raw}, range phys 0..255
          signal StatusBindingFBD_HM_Data37: start 320, 8 bit, little-endian, data-type-policy=OVERRIDE, base-type=uint8, compu {phys=raw}, range phys 0..255
          signal StatusBindingFBD_HM_Data38: start 328, 8 bit, little-endian, data-type-policy=OVERRIDE, base-type=uint8, compu {phys=raw}, range phys 0..255
          signal StatusBindingFBD_HM_Data39: start 336, 8 bit, little-endian, data-type-policy=OVERRIDE, base-type=uint8, compu {phys=raw}, range phys 0..255
          signal StatusBindingFBD_HM_Data40: start 344, 8 bit, little-endian, data-type-policy=OVERRIDE, base-type=uint8, compu {phys=raw}, range phys 0..255
          signal StatusBindingFBD_HM_Data41: start 352, 8 bit, little-endian, data-type-policy=OVERRIDE, base-type=uint8, compu {phys=raw}, range phys 0..255
          signal StatusBindingFBD_HM_Data42: start 360, 8 bit, little-endian, data-type-policy=OVERRIDE, base-type=uint8, compu {phys=raw}, range phys 0..255
          signal StatusBindingFBD_HM_Data43: start 368, 8 bit, little-endian, data-type-policy=OVERRIDE, base-type=uint8, compu {phys=raw}, range phys 0..255
          signal StatusBindingFBD_HM_Data44: start 376, 8 bit, little-endian, data-type-policy=OVERRIDE, base-type=uint8, compu {phys=raw}, range phys 0..255
          signal StatusBindingFBD_HM_Data45: start 384, 8 bit, little-endian, data-type-policy=OVERRIDE, base-type=uint8, compu {phys=raw}, range phys 0..255
          signal StatusBindingFBD_HM_Data46: start 392, 8 bit, little-endian, data-type-policy=OVERRIDE, base-type=uint8, compu {phys=raw}, range phys 0..255
          signal StatusBindingFBD_HM_Data47: start 400, 8 bit, little-endian, data-type-policy=OVERRIDE, base-type=uint8, compu {phys=raw}, range phys 0..255
          signal StatusBindingFBD_HM_Data48: start 408, 8 bit, little-endian, data-type-policy=OVERRIDE, base-type=uint8, compu {phys=raw}, range phys 0..255
          signal StatusBindingFBD_HM_Data49: start 416, 8 bit, little-endian, data-type-policy=OVERRIDE, base-type=uint8, compu {phys=raw}, range phys 0..255
          signal StatusBindingFBD_HM_Data50: start 424, 8 bit, little-endian, data-type-policy=OVERRIDE, base-type=uint8, compu {phys=raw}, range phys 0..255
          signal StatusBindingFBD_HM_Data51: start 432, 8 bit, little-endian, data-type-policy=OVERRIDE, base-type=uint8, compu {phys=raw}, range phys 0..255
          signal StatusBindingFBD_HM_Data52: start 440, 8 bit, little-endian, data-type-policy=OVERRIDE, base-type=uint8, compu {phys=raw}, range phys 0..255
          signal StatusBindingFBD_HM_Data53: start 448, 8 bit, little-endian, data-type-policy=OVERRIDE, base-type=uint8, compu {phys=raw}, range phys 0..255
          signal StatusBindingFBD_HM_Data54: start 456, 8 bit, little-endian, data-type-policy=OVERRIDE, base-type=uint8, compu {phys=raw}, range phys 0..255
          signal StatusBindingFBD_HM_Data55: start 464, 8 bit, little-endian, data-type-policy=OVERRIDE, base-type=uint8, compu {phys=raw}, range phys 0..255
          signal StatusBindingFBD_HM_Data56: start 472, 8 bit, little-endian, data-type-policy=OVERRIDE, base-type=uint8, compu {phys=raw}, range phys 0..255
          signal StatusBindingFBD_HM_Data57: start 480, 8 bit, little-endian, data-type-policy=OVERRIDE, base-type=uint8, compu {phys=raw}, range phys 0..255
          signal StatusBindingFBD_HM_Data58: start 488, 8 bit, little-endian, data-type-policy=OVERRIDE, base-type=uint8, compu {phys=raw}, range phys 0..255
          signal StatusBindingFBD_HM_Data59: start 496, 8 bit, little-endian, data-type-policy=OVERRIDE, base-type=uint8, compu {phys=raw}, range phys 0..255
          signal StatusBindingFBD_HM_Data60: start 504, 8 bit, little-endian, data-type-policy=OVERRIDE, base-type=uint8, compu {phys=raw}, range phys 0..255
      frame StatusBindingFBD_HR: id 0x273, frame-length=64, can-addressing-mode=STANDARD, can-frame-rx-behavior=CAN-FD, can-frame-tx-behavior=CAN-FD
        pdu StatusBindingFBD_HR: length=64, unused-bit-pattern=0
          signal StatusBindingFBD_HR_BindingStatus: start 0, 8 bit, little-endian, data-type-policy=OVERRIDE, base-type=uint8, compu {phys=raw}, range phys 0..252
          signal StatusBindingFBD_HR_BindingCounter: start 8, 8 bit, little-endian, data-type-policy=OVERRIDE, base-type=uint8, compu {phys=raw}, range phys 0..252
          signal StatusBindingFBD_HR_BindingSequence: start 16, 8 bit, little-endian, data-type-policy=OVERRIDE, base-type=uint8, compu {phys=raw}, range phys 0..252
          signal StatusBindingFBD_HR_Data00: start 24, 8 bit, little-endian, data-type-policy=OVERRIDE, base-type=uint8, compu {phys=raw}, range phys 0..255
          signal StatusBindingFBD_HR_Data01: start 32, 8 bit, little-endian, data-type-policy=OVERRIDE, base-type=uint8, compu {phys=raw}, range phys 0..255
          signal StatusBindingFBD_HR_Data02: start 40, 8 bit, little-endian, data-type-policy=OVERRIDE, base-type=uint8, compu {phys=raw}, range phys 0..255
          signal StatusBindingFBD_HR_Data03: start 48, 8 bit, little-endian, data-type-policy=OVERRIDE, base-type=uint8, compu {phys=raw}, range phys 0..255
          signal StatusBindingFBD_HR_Data04: start 56, 8 bit, little-endian, data-type-policy=OVERRIDE, base-type=uint8, compu {phys=raw}, range phys 0..255
          signal StatusBindingFBD_HR_Data05: start 64, 8 bit, little-endian, data-type-policy=OVERRIDE, base-type=uint8, compu {phys=raw}, range phys 0..255
          signal StatusBindingFBD_HR_Data06: start 72, 8 bit, little-endian, data-type-policy=OVERRIDE, base-type=uint8, compu {phys=raw}, range phys 0..255
          signal StatusBindingFBD_HR_Data07: start 80, 8 bit, little-endian, data-type-policy=OVERRIDE, base-type=uint8, compu {phys=raw}, range phys 0..255
          signal StatusBindingFBD_HR_Data08: start 88, 8 bit, little-endian, data-type-policy=OVERRIDE, base-type=uint8, compu {phys=raw}, range phys 0..255
          signal StatusBindingFBD_HR_Data09: start 96, 8 bit, little-endian, data-type-policy=OVERRIDE, base-type=uint8, compu {phys=raw}, range phys 0..255
          signal StatusBindingFBD_HR_Data10: start 104, 8 bit, little-endian, data-type-policy=OVERRIDE, base-type=uint8, compu {phys=raw}, range phys 0..255
          signal StatusBindingFBD_HR_Data11: start 112, 8 bit, little-endian, data-type-policy=OVERRIDE, base-type=uint8, compu {phys=raw}, range phys 0..255
          signal StatusBindingFBD_HR_Data12: start 120, 8 bit, little-endian, data-type-policy=OVERRIDE, base-type=uint8, compu {phys=raw}, range phys 0..255
          signal StatusBindingFBD_HR_Data13: start 128, 8 bit, little-endian, data-type-policy=OVERRIDE, base-type=uint8, compu {phys=raw}, range phys 0..255
          signal StatusBindingFBD_HR_Data14: start 136, 8 bit, little-endian, data-type-policy=OVERRIDE, base-type=uint8, compu {phys=raw}, range phys 0..255
          signal StatusBindingFBD_HR_Data15: start 144, 8 bit, little-endian, data-type-policy=OVERRIDE, base-type=uint8, compu {phys=raw}, range phys 0..255
          signal StatusBindingFBD_HR_Data16: start 152, 8 bit, little-endian, data-type-policy=OVERRIDE, base-type=uint8, compu {phys=raw}, range phys 0..255
          signal StatusBindingFBD_HR_Data17: start 160, 8 bit, little-endian, data-type-policy=OVERRIDE, base-type=uint8, compu {phys=raw}, range phys 0..255
          signal StatusBindingFBD_HR_Data18: start 168, 8 bit, little-endian, data-type-policy=OVERRIDE, base-type=uint8, compu {phys=raw}, range phys 0..255
          signal StatusBindingFBD_HR_Data19: start 176, 8 bit, little-endian, data-type-policy=OVERRIDE, base-type=uint8, compu {phys=raw}, range phys 0..255
          signal StatusBindingFBD_HR_Data20: start 184, 8 bit, little-endian, data-type-policy=OVERRIDE, base-type=uint8, compu {phys=raw}, range phys 0..255
          signal StatusBindingFBD_HR_Data21: start 192, 8 bit, little-endian, data-type-policy=OVERRIDE, base-type=uint8, compu {phys=raw}, range phys 0..255
          signal StatusBindingFBD_HR_Data22: start 200, 8 bit, little-endian, data-type-policy=OVERRIDE, base-type=uint8, compu {phys=raw}, range phys 0..255
          signal StatusBindingFBD_HR_Data23: start 208, 8 bit, little-endian, data-type-policy=OVERRIDE, base-type=uint8, compu {phys=raw}, range phys 0..255
          signal StatusBindingFBD_HR_Data24: start 216, 8 bit, little-endian, data-type-policy=OVERRIDE, base-type=uint8, compu {phys=raw}, range phys 0..255
          signal StatusBindingFBD_HR_Data25: start 224, 8 bit, little-endian, data-type-policy=OVERRIDE, base-type=uint8, compu {phys=raw}, range phys 0..255
          signal StatusBindingFBD_HR_Data26: start 232, 8 bit, little-endian, data-type-policy=OVERRIDE, base-type=uint8, compu {phys=raw}, range phys 0..255
          signal StatusBindingFBD_HR_Data27: start 240, 8 bit, little-endian, data-type-policy=OVERRIDE, base-type=uint8, compu {phys=raw}, range phys 0..255
          signal StatusBindingFBD_HR_Data28: start 248, 8 bit, little-endian, data-type-policy=OVERRIDE, base-type=uint8, compu {phys=raw}, range phys 0..255
          signal StatusBindingFBD_HR_Data29: start 256, 8 bit, little-endian, data-type-policy=OVERRIDE, base-type=uint8, compu {phys=raw}, range phys 0..255
          signal StatusBindingFBD_HR_Data30: start 264, 8 bit, little-endian, data-type-policy=OVERRIDE, base-type=uint8, compu {phys=raw}, range phys 0..255
          signal StatusBindingFBD_HR_Data31: start 272, 8 bit, little-endian, data-type-policy=OVERRIDE, base-type=uint8, compu {phys=raw}, range phys 0..255
          signal StatusBindingFBD_HR_Data32: start 280, 8 bit, little-endian, data-type-policy=OVERRIDE, base-type=uint8, compu {phys=raw}, range phys 0..255
          signal StatusBindingFBD_HR_Data33: start 288, 8 bit, little-endian, data-type-policy=OVERRIDE, base-type=uint8, compu {phys=raw}, range phys 0..255
          signal StatusBindingFBD_HR_Data34: start 296, 8 bit, little-endian, data-type-policy=OVERRIDE, base-type=uint8, compu {phys=raw}, range phys 0..255
          signal StatusBindingFBD_HR_Data35: start 304, 8 bit, little-endian, data-type-policy=OVERRIDE, base-type=uint8, compu {phys=raw}, range phys 0..255
          signal StatusBindingFBD_HR_Data36: start 312, 8 bit, little-endian, data-type-policy=OVERRIDE, base-type=uint8, compu {phys=raw}, range phys 0..255
          signal StatusBindingFBD_HR_Data37: start 320, 8 bit, little-endian, data-type-policy=OVERRIDE, base-type=uint8, compu {phys=raw}, range phys 0..255
          signal StatusBindingFBD_HR_Data38: start 328, 8 bit, little-endian, data-type-policy=OVERRIDE, base-type=uint8, compu {phys=raw}, range phys 0..255
          signal StatusBindingFBD_HR_Data39: start 336, 8 bit, little-endian, data-type-policy=OVERRIDE, base-type=uint8, compu {phys=raw}, range phys 0..255
          signal StatusBindingFBD_HR_Data40: start 344, 8 bit, little-endian, data-type-policy=OVERRIDE, base-type=uint8, compu {phys=raw}, range phys 0..255
          signal StatusBindingFBD_HR_Data41: start 352, 8 bit, little-endian, data-type-policy=OVERRIDE, base-type=uint8, compu {phys=raw}, range phys 0..255
          signal StatusBindingFBD_HR_Data42: start 360, 8 bit, little-endian, data-type-policy=OVERRIDE, base-type=uint8, compu {phys=raw}, range phys 0..255
          signal StatusBindingFBD_HR_Data43: start 368, 8 bit, little-endian, data-type-policy=OVERRIDE, base-type=uint8, compu {phys=raw}, range phys 0..255
          signal StatusBindingFBD_HR_Data44: start 376, 8 bit, little-endian, data-type-policy=OVERRIDE, base-type=uint8, compu {phys=raw}, range phys 0..255
          signal StatusBindingFBD_HR_Data45: start 384, 8 bit, little-endian, data-type-policy=OVERRIDE, base-type=uint8, compu {phys=raw}, range phys 0..255
          signal StatusBindingFBD_HR_Data46: start 392, 8 bit, little-endian, data-type-policy=OVERRIDE, base-type=uint8, compu {phys=raw}, range phys 0..255
          signal StatusBindingFBD_HR_Data47: start 400, 8 bit, little-endian, data-type-policy=OVERRIDE, base-type=uint8, compu {phys=raw}, range phys 0..255
          signal StatusBindingFBD_HR_Data48: start 408, 8 bit, little-endian, data-type-policy=OVERRIDE, base-type=uint8, compu {phys=raw}, range phys 0..255
          signal StatusBindingFBD_HR_Data49: start 416, 8 bit, little-endian, data-type-policy=OVERRIDE, base-type=uint8, compu {phys=raw}, range phys 0..255
          signal StatusBindingFBD_HR_Data50: start 424, 8 bit, little-endian, data-type-policy=OVERRIDE, base-type=uint8, compu {phys=raw}, range phys 0..255
          signal StatusBindingFBD_HR_Data51: start 432, 8 bit, little-endian, data-type-policy=OVERRIDE, base-type=uint8, compu {phys=raw}, range phys 0..255
          signal StatusBindingFBD_HR_Data52: start 440, 8 bit, little-endian, data-type-policy=OVERRIDE, base-type=uint8, compu {phys=raw}, range phys 0..255
          signal StatusBindingFBD_HR_Data53: start 448, 8 bit, little-endian, data-type-policy=OVERRIDE, base-type=uint8, compu {phys=raw}, range phys 0..255
          signal StatusBindingFBD_HR_Data54: start 456, 8 bit, little-endian, data-type-policy=OVERRIDE, base-type=uint8, compu {phys=raw}, range phys 0..255
          signal StatusBindingFBD_HR_Data55: start 464, 8 bit, little-endian, data-type-policy=OVERRIDE, base-type=uint8, compu {phys=raw}, range phys 0..255
          signal StatusBindingFBD_HR_Data56: start 472, 8 bit, little-endian, data-type-policy=OVERRIDE, base-type=uint8, compu {phys=raw}, range phys 0..255
          signal StatusBindingFBD_HR_Data57: start 480, 8 bit, little-endian, data-type-policy=OVERRIDE, base-type=uint8, compu {phys=raw}, range phys 0..255
          signal StatusBindingFBD_HR_Data58: start 488, 8 bit, little-endian, data-type-policy=OVERRIDE, base-type=uint8, compu {phys=raw}, range phys 0..255
          signal StatusBindingFBD_HR_Data59: start 496, 8 bit, little-endian, data-type-policy=OVERRIDE, base-type=uint8, compu {phys=raw}, range phys 0..255
          signal StatusBindingFBD_HR_Data60: start 504, 8 bit, little-endian, data-type-policy=OVERRIDE, base-type=uint8, compu {phys=raw}, range phys 0..255
      frame StatusBindingFBD_Miko: id 0x26E, frame-length=64, can-addressing-mode=STANDARD, can-frame-rx-behavior=CAN-FD, can-frame-tx-behavior=CAN-FD
        pdu StatusBindingFBD_Miko: length=64, unused-bit-pattern=0
          signal StatusBindingFBD_Miko_BindingStatus: start 0, 8 bit, little-endian, data-type-policy=OVERRIDE, base-type=uint8, compu {phys=raw}, range phys 0..252
          signal StatusBindingFBD_Miko_BindingCounter: start 8, 8 bit, little-endian, data-type-policy=OVERRIDE, base-type=uint8, compu {phys=raw}, range phys 0..252
          signal StatusBindingFBD_Miko_BindingSequence: start 16, 8 bit, little-endian, data-type-policy=OVERRIDE, base-type=uint8, compu {phys=raw}, range phys 0..252
          signal StatusBindingFBD_Miko_Data00: start 24, 8 bit, little-endian, data-type-policy=OVERRIDE, base-type=uint8, compu {phys=raw}, range phys 0..255
          signal StatusBindingFBD_Miko_Data01: start 32, 8 bit, little-endian, data-type-policy=OVERRIDE, base-type=uint8, compu {phys=raw}, range phys 0..255
          signal StatusBindingFBD_Miko_Data02: start 40, 8 bit, little-endian, data-type-policy=OVERRIDE, base-type=uint8, compu {phys=raw}, range phys 0..255
          signal StatusBindingFBD_Miko_Data03: start 48, 8 bit, little-endian, data-type-policy=OVERRIDE, base-type=uint8, compu {phys=raw}, range phys 0..255
          signal StatusBindingFBD_Miko_Data04: start 56, 8 bit, little-endian, data-type-policy=OVERRIDE, base-type=uint8, compu {phys=raw}, range phys 0..255
          signal StatusBindingFBD_Miko_Data05: start 64, 8 bit, little-endian, data-type-policy=OVERRIDE, base-type=uint8, compu {phys=raw}, range phys 0..255
          signal StatusBindingFBD_Miko_Data06: start 72, 8 bit, little-endian, data-type-policy=OVERRIDE, base-type=uint8, compu {phys=raw}, range phys 0..255
          signal StatusBindingFBD_Miko_Data07: start 80, 8 bit, little-endian, data-type-policy=OVERRIDE, base-type=uint8, compu {phys=raw}, range phys 0..255
          signal StatusBindingFBD_Miko_Data08: start 88, 8 bit, little-endian, data-type-policy=OVERRIDE, base-type=uint8, compu {phys=raw}, range phys 0..255
          signal StatusBindingFBD_Miko_Data09: start 96, 8 bit, little-endian, data-type-policy=OVERRIDE, base-type=uint8, compu {phys=raw}, range phys 0..255
          signal StatusBindingFBD_Miko_Data10: start 104, 8 bit, little-endian, data-type-policy=OVERRIDE, base-type=uint8, compu {phys=raw}, range phys 0..255
          signal StatusBindingFBD_Miko_Data11: start 112, 8 bit, little-endian, data-type-policy=OVERRIDE, base-type=uint8, compu {phys=raw}, range phys 0..255
          signal StatusBindingFBD_Miko_Data12: start 120, 8 bit, little-endian, data-type-policy=OVERRIDE, base-type=uint8, compu {phys=raw}, range phys 0..255
          signal StatusBindingFBD_Miko_Data13: start 128, 8 bit, little-endian, data-type-policy=OVERRIDE, base-type=uint8, compu {phys=raw}, range phys 0..255
          signal StatusBindingFBD_Miko_Data14: start 136, 8 bit, little-endian, data-type-policy=OVERRIDE, base-type=uint8, compu {phys=raw}, range phys 0..255
          signal StatusBindingFBD_Miko_Data15: start 144, 8 bit, little-endian, data-type-policy=OVERRIDE, base-type=uint8, compu {phys=raw}, range phys 0..255
          signal StatusBindingFBD_Miko_Data16: start 152, 8 bit, little-endian, data-type-policy=OVERRIDE, base-type=uint8, compu {phys=raw}, range phys 0..255
          signal StatusBindingFBD_Miko_Data17: start 160, 8 bit, little-endian, data-type-policy=OVERRIDE, base-type=uint8, compu {phys=raw}, range phys 0..255
          signal StatusBindingFBD_Miko_Data18: start 168, 8 bit, little-endian, data-type-policy=OVERRIDE, base-type=uint8, compu {phys=raw}, range phys 0..255
          signal StatusBindingFBD_Miko_Data19: start 176, 8 bit, little-endian, data-type-policy=OVERRIDE, base-type=uint8, compu {phys=raw}, range phys 0..255
          signal StatusBindingFBD_Miko_Data20: start 184, 8 bit, little-endian, data-type-policy=OVERRIDE, base-type=uint8, compu {phys=raw}, range phys 0..255
          signal StatusBindingFBD_Miko_Data21: start 192, 8 bit, little-endian, data-type-policy=OVERRIDE, base-type=uint8, compu {phys=raw}, range phys 0..255
          signal StatusBindingFBD_Miko_Data22: start 200, 8 bit, little-endian, data-type-policy=OVERRIDE, base-type=uint8, compu {phys=raw}, range phys 0..255
          signal StatusBindingFBD_Miko_Data23: start 208, 8 bit, little-endian, data-type-policy=OVERRIDE, base-type=uint8, compu {phys=raw}, range phys 0..255
          signal StatusBindingFBD_Miko_Data24: start 216, 8 bit, little-endian, data-type-policy=OVERRIDE, base-type=uint8, compu {phys=raw}, range phys 0..255
          signal StatusBindingFBD_Miko_Data25: start 224, 8 bit, little-endian, data-type-policy=OVERRIDE, base-type=uint8, compu {phys=raw}, range phys 0..255
          signal StatusBindingFBD_Miko_Data26: start 232, 8 bit, little-endian, data-type-policy=OVERRIDE, base-type=uint8, compu {phys=raw}, range phys 0..255
          signal StatusBindingFBD_Miko_Data27: start 240, 8 bit, little-endian, data-type-policy=OVERRIDE, base-type=uint8, compu {phys=raw}, range phys 0..255
          signal StatusBindingFBD_Miko_Data28: start 248, 8 bit, little-endian, data-type-policy=OVERRIDE, base-type=uint8, compu {phys=raw}, range phys 0..255
          signal StatusBindingFBD_Miko_Data29: start 256, 8 bit, little-endian, data-type-policy=OVERRIDE, base-type=uint8, compu {phys=raw}, range phys 0..255
          signal StatusBindingFBD_Miko_Data30: start 264, 8 bit, little-endian, data-type-policy=OVERRIDE, base-type=uint8, compu {phys=raw}, range phys 0..255
          signal StatusBindingFBD_Miko_Data31: start 272, 8 bit, little-endian, data-type-policy=OVERRIDE, base-type=uint8, compu {phys=raw}, range phys 0..255
          signal StatusBindingFBD_Miko_Data32: start 280, 8 bit, little-endian, data-type-policy=OVERRIDE, base-type=uint8, compu {phys=raw}, range phys 0..255
          signal StatusBindingFBD_Miko_Data33: start 288, 8 bit, little-endian, data-type-policy=OVERRIDE, base-type=uint8, compu {phys=raw}, range phys 0..255
          signal StatusBindingFBD_Miko_Data34: start 296, 8 bit, little-endian, data-type-policy=OVERRIDE, base-type=uint8, compu {phys=raw}, range phys 0..255
          signal StatusBindingFBD_Miko_Data35: start 304, 8 bit, little-endian, data-type-policy=OVERRIDE, base-type=uint8, compu {phys=raw}, range phys 0..255
          signal StatusBindingFBD_Miko_Data36: start 312, 8 bit, little-endian, data-type-policy=OVERRIDE, base-type=uint8, compu {phys=raw}, range phys 0..255
          signal StatusBindingFBD_Miko_Data37: start 320, 8 bit, little-endian, data-type-policy=OVERRIDE, base-type=uint8, compu {phys=raw}, range phys 0..255
          signal StatusBindingFBD_Miko_Data38: start 328, 8 bit, little-endian, data-type-policy=OVERRIDE, base-type=uint8, compu {phys=raw}, range phys 0..255
          signal StatusBindingFBD_Miko_Data39: start 336, 8 bit, little-endian, data-type-policy=OVERRIDE, base-type=uint8, compu {phys=raw}, range phys 0..255
          signal StatusBindingFBD_Miko_Data40: start 344, 8 bit, little-endian, data-type-policy=OVERRIDE, base-type=uint8, compu {phys=raw}, range phys 0..255
          signal StatusBindingFBD_Miko_Data41: start 352, 8 bit, little-endian, data-type-policy=OVERRIDE, base-type=uint8, compu {phys=raw}, range phys 0..255
          signal StatusBindingFBD_Miko_Data42: start 360, 8 bit, little-endian, data-type-policy=OVERRIDE, base-type=uint8, compu {phys=raw}, range phys 0..255
          signal StatusBindingFBD_Miko_Data43: start 368, 8 bit, little-endian, data-type-policy=OVERRIDE, base-type=uint8, compu {phys=raw}, range phys 0..255
          signal StatusBindingFBD_Miko_Data44: start 376, 8 bit, little-endian, data-type-policy=OVERRIDE, base-type=uint8, compu {phys=raw}, range phys 0..255
          signal StatusBindingFBD_Miko_Data45: start 384, 8 bit, little-endian, data-type-policy=OVERRIDE, base-type=uint8, compu {phys=raw}, range phys 0..255
          signal StatusBindingFBD_Miko_Data46: start 392, 8 bit, little-endian, data-type-policy=OVERRIDE, base-type=uint8, compu {phys=raw}, range phys 0..255
          signal StatusBindingFBD_Miko_Data47: start 400, 8 bit, little-endian, data-type-policy=OVERRIDE, base-type=uint8, compu {phys=raw}, range phys 0..255
          signal StatusBindingFBD_Miko_Data48: start 408, 8 bit, little-endian, data-type-policy=OVERRIDE, base-type=uint8, compu {phys=raw}, range phys 0..255
          signal StatusBindingFBD_Miko_Data49: start 416, 8 bit, little-endian, data-type-policy=OVERRIDE, base-type=uint8, compu {phys=raw}, range phys 0..255
          signal StatusBindingFBD_Miko_Data50: start 424, 8 bit, little-endian, data-type-policy=OVERRIDE, base-type=uint8, compu {phys=raw}, range phys 0..255
          signal StatusBindingFBD_Miko_Data51: start 432, 8 bit, little-endian, data-type-policy=OVERRIDE, base-type=uint8, compu {phys=raw}, range phys 0..255
          signal StatusBindingFBD_Miko_Data52: start 440, 8 bit, little-endian, data-type-policy=OVERRIDE, base-type=uint8, compu {phys=raw}, range phys 0..255
          signal StatusBindingFBD_Miko_Data53: start 448, 8 bit, little-endian, data-type-policy=OVERRIDE, base-type=uint8, compu {phys=raw}, range phys 0..255
          signal StatusBindingFBD_Miko_Data54: start 456, 8 bit, little-endian, data-type-policy=OVERRIDE, base-type=uint8, compu {phys=raw}, range phys 0..255
          signal StatusBindingFBD_Miko_Data55: start 464, 8 bit, little-endian, data-type-policy=OVERRIDE, base-type=uint8, compu {phys=raw}, range phys 0..255
          signal StatusBindingFBD_Miko_Data56: start 472, 8 bit, little-endian, data-type-policy=OVERRIDE, base-type=uint8, compu {phys=raw}, range phys 0..255
          signal StatusBindingFBD_Miko_Data57: start 480, 8 bit, little-endian, data-type-policy=OVERRIDE, base-type=uint8, compu {phys=raw}, range phys 0..255
          signal StatusBindingFBD_Miko_Data58: start 488, 8 bit, little-endian, data-type-policy=OVERRIDE, base-type=uint8, compu {phys=raw}, range phys 0..255
          signal StatusBindingFBD_Miko_Data59: start 496, 8 bit, little-endian, data-type-policy=OVERRIDE, base-type=uint8, compu {phys=raw}, range phys 0..255
          signal StatusBindingFBD_Miko_Data60: start 504, 8 bit, little-endian, data-type-policy=OVERRIDE, base-type=uint8, compu {phys=raw}, range phys 0..255
      frame StatusBindingFBD_MM: id 0x35E, frame-length=64, can-addressing-mode=STANDARD, can-frame-rx-behavior=CAN-FD, can-frame-tx-behavior=CAN-FD
        pdu StatusBindingFBD_MM: length=64, unused-bit-pattern=0
          signal StatusBindingFBD_MM_BindingStatus: start 0, 8 bit, little-endian, data-type-policy=OVERRIDE, base-type=uint8, compu {phys=raw}, range phys 0..252
          signal StatusBindingFBD_MM_BindingCounter: start 8, 8 bit, little-endian, data-type-policy=OVERRIDE, base-type=uint8, compu {phys=raw}, range phys 0..252
          signal StatusBindingFBD_MM_BindingSequence: start 16, 8 bit, little-endian, data-type-policy=OVERRIDE, base-type=uint8, compu {phys=raw}, range phys 0..252
          signal StatusBindingFBD_MM_Data00: start 24, 8 bit, little-endian, data-type-policy=OVERRIDE, base-type=uint8, compu {phys=raw}, range phys 0..255
          signal StatusBindingFBD_MM_Data01: start 32, 8 bit, little-endian, data-type-policy=OVERRIDE, base-type=uint8, compu {phys=raw}, range phys 0..255
          signal StatusBindingFBD_MM_Data02: start 40, 8 bit, little-endian, data-type-policy=OVERRIDE, base-type=uint8, compu {phys=raw}, range phys 0..255
          signal StatusBindingFBD_MM_Data03: start 48, 8 bit, little-endian, data-type-policy=OVERRIDE, base-type=uint8, compu {phys=raw}, range phys 0..255
          signal StatusBindingFBD_MM_Data04: start 56, 8 bit, little-endian, data-type-policy=OVERRIDE, base-type=uint8, compu {phys=raw}, range phys 0..255
          signal StatusBindingFBD_MM_Data05: start 64, 8 bit, little-endian, data-type-policy=OVERRIDE, base-type=uint8, compu {phys=raw}, range phys 0..255
          signal StatusBindingFBD_MM_Data06: start 72, 8 bit, little-endian, data-type-policy=OVERRIDE, base-type=uint8, compu {phys=raw}, range phys 0..255
          signal StatusBindingFBD_MM_Data07: start 80, 8 bit, little-endian, data-type-policy=OVERRIDE, base-type=uint8, compu {phys=raw}, range phys 0..255
          signal StatusBindingFBD_MM_Data08: start 88, 8 bit, little-endian, data-type-policy=OVERRIDE, base-type=uint8, compu {phys=raw}, range phys 0..255
          signal StatusBindingFBD_MM_Data09: start 96, 8 bit, little-endian, data-type-policy=OVERRIDE, base-type=uint8, compu {phys=raw}, range phys 0..255
          signal StatusBindingFBD_MM_Data10: start 104, 8 bit, little-endian, data-type-policy=OVERRIDE, base-type=uint8, compu {phys=raw}, range phys 0..255
          signal StatusBindingFBD_MM_Data11: start 112, 8 bit, little-endian, data-type-policy=OVERRIDE, base-type=uint8, compu {phys=raw}, range phys 0..255
          signal StatusBindingFBD_MM_Data12: start 120, 8 bit, little-endian, data-type-policy=OVERRIDE, base-type=uint8, compu {phys=raw}, range phys 0..255
          signal StatusBindingFBD_MM_Data13: start 128, 8 bit, little-endian, data-type-policy=OVERRIDE, base-type=uint8, compu {phys=raw}, range phys 0..255
          signal StatusBindingFBD_MM_Data14: start 136, 8 bit, little-endian, data-type-policy=OVERRIDE, base-type=uint8, compu {phys=raw}, range phys 0..255
          signal StatusBindingFBD_MM_Data15: start 144, 8 bit, little-endian, data-type-policy=OVERRIDE, base-type=uint8, compu {phys=raw}, range phys 0..255
          signal StatusBindingFBD_MM_Data16: start 152, 8 bit, little-endian, data-type-policy=OVERRIDE, base-type=uint8, compu {phys=raw}, range phys 0..255
          signal StatusBindingFBD_MM_Data17: start 160, 8 bit, little-endian, data-type-policy=OVERRIDE, base-type=uint8, compu {phys=raw}, range phys 0..255
          signal StatusBindingFBD_MM_Data18: start 168, 8 bit, little-endian, data-type-policy=OVERRIDE, base-type=uint8, compu {phys=raw}, range phys 0..255
          signal StatusBindingFBD_MM_Data19: start 176, 8 bit, little-endian, data-type-policy=OVERRIDE, base-type=uint8, compu {phys=raw}, range phys 0..255
          signal StatusBindingFBD_MM_Data20: start 184, 8 bit, little-endian, data-type-policy=OVERRIDE, base-type=uint8, compu {phys=raw}, range phys 0..255
          signal StatusBindingFBD_MM_Data21: start 192, 8 bit, little-endian, data-type-policy=OVERRIDE, base-type=uint8, compu {phys=raw}, range phys 0..255
          signal StatusBindingFBD_MM_Data22: start 200, 8 bit, little-endian, data-type-policy=OVERRIDE, base-type=uint8, compu {phys=raw}, range phys 0..255
          signal StatusBindingFBD_MM_Data23: start 208, 8 bit, little-endian, data-type-policy=OVERRIDE, base-type=uint8, compu {phys=raw}, range phys 0..255
          signal StatusBindingFBD_MM_Data24: start 216, 8 bit, little-endian, data-type-policy=OVERRIDE, base-type=uint8, compu {phys=raw}, range phys 0..255
          signal StatusBindingFBD_MM_Data25: start 224, 8 bit, little-endian, data-type-policy=OVERRIDE, base-type=uint8, compu {phys=raw}, range phys 0..255
          signal StatusBindingFBD_MM_Data26: start 232, 8 bit, little-endian, data-type-policy=OVERRIDE, base-type=uint8, compu {phys=raw}, range phys 0..255
          signal StatusBindingFBD_MM_Data27: start 240, 8 bit, little-endian, data-type-policy=OVERRIDE, base-type=uint8, compu {phys=raw}, range phys 0..255
          signal StatusBindingFBD_MM_Data28: start 248, 8 bit, little-endian, data-type-policy=OVERRIDE, base-type=uint8, compu {phys=raw}, range phys 0..255
          signal StatusBindingFBD_MM_Data29: start 256, 8 bit, little-endian, data-type-policy=OVERRIDE, base-type=uint8, compu {phys=raw}, range phys 0..255
          signal StatusBindingFBD_MM_Data30: start 264, 8 bit, little-endian, data-type-policy=OVERRIDE, base-type=uint8, compu {phys=raw}, range phys 0..255
          signal StatusBindingFBD_MM_Data31: start 272, 8 bit, little-endian, data-type-policy=OVERRIDE, base-type=uint8, compu {phys=raw}, range phys 0..255
          signal StatusBindingFBD_MM_Data32: start 280, 8 bit, little-endian, data-type-policy=OVERRIDE, base-type=uint8, compu {phys=raw}, range phys 0..255
          signal StatusBindingFBD_MM_Data33: start 288, 8 bit, little-endian, data-type-policy=OVERRIDE, base-type=uint8, compu {phys=raw}, range phys 0..255
          signal StatusBindingFBD_MM_Data34: start 296, 8 bit, little-endian, data-type-policy=OVERRIDE, base-type=uint8, compu {phys=raw}, range phys 0..255
          signal StatusBindingFBD_MM_Data35: start 304, 8 bit, little-endian, data-type-policy=OVERRIDE, base-type=uint8, compu {phys=raw}, range phys 0..255
          signal StatusBindingFBD_MM_Data36: start 312, 8 bit, little-endian, data-type-policy=OVERRIDE, base-type=uint8, compu {phys=raw}, range phys 0..255
          signal StatusBindingFBD_MM_Data37: start 320, 8 bit, little-endian, data-type-policy=OVERRIDE, base-type=uint8, compu {phys=raw}, range phys 0..255
          signal StatusBindingFBD_MM_Data38: start 328, 8 bit, little-endian, data-type-policy=OVERRIDE, base-type=uint8, compu {phys=raw}, range phys 0..255
          signal StatusBindingFBD_MM_Data39: start 336, 8 bit, little-endian, data-type-policy=OVERRIDE, base-type=uint8, compu {phys=raw}, range phys 0..255
          signal StatusBindingFBD_MM_Data40: start 344, 8 bit, little-endian, data-type-policy=OVERRIDE, base-type=uint8, compu {phys=raw}, range phys 0..255
          signal StatusBindingFBD_MM_Data41: start 352, 8 bit, little-endian, data-type-policy=OVERRIDE, base-type=uint8, compu {phys=raw}, range phys 0..255
          signal StatusBindingFBD_MM_Data42: start 360, 8 bit, little-endian, data-type-policy=OVERRIDE, base-type=uint8, compu {phys=raw}, range phys 0..255
          signal StatusBindingFBD_MM_Data43: start 368, 8 bit, little-endian, data-type-policy=OVERRIDE, base-type=uint8, compu {phys=raw}, range phys 0..255
          signal StatusBindingFBD_MM_Data44: start 376, 8 bit, little-endian, data-type-policy=OVERRIDE, base-type=uint8, compu {phys=raw}, range phys 0..255
          signal StatusBindingFBD_MM_Data45: start 384, 8 bit, little-endian, data-type-policy=OVERRIDE, base-type=uint8, compu {phys=raw}, range phys 0..255
          signal StatusBindingFBD_MM_Data46: start 392, 8 bit, little-endian, data-type-policy=OVERRIDE, base-type=uint8, compu {phys=raw}, range phys 0..255
          signal StatusBindingFBD_MM_Data47: start 400, 8 bit, little-endian, data-type-policy=OVERRIDE, base-type=uint8, compu {phys=raw}, range phys 0..255
          signal StatusBindingFBD_MM_Data48: start 408, 8 bit, little-endian, data-type-policy=OVERRIDE, base-type=uint8, compu {phys=raw}, range phys 0..255
          signal StatusBindingFBD_MM_Data49: start 416, 8 bit, little-endian, data-type-policy=OVERRIDE, base-type=uint8, compu {phys=raw}, range phys 0..255
          signal StatusBindingFBD_MM_Data50: start 424, 8 bit, little-endian, data-type-policy=OVERRIDE, base-type=uint8, compu {phys=raw}, range phys 0..255
          signal StatusBindingFBD_MM_Data51: start 432, 8 bit, little-endian, data-type-policy=OVERRIDE, base-type=uint8, compu {phys=raw}, range phys 0..255
          signal StatusBindingFBD_MM_Data52: start 440, 8 bit, little-endian, data-type-policy=OVERRIDE, base-type=uint8, compu {phys=raw}, range phys 0..255
          signal StatusBindingFBD_MM_Data53: start 448, 8 bit, little-endian, data-type-policy=OVERRIDE, base-type=uint8, compu {phys=raw}, range phys 0..255
          signal StatusBindingFBD_MM_Data54: start 456, 8 bit, little-endian, data-type-policy=OVERRIDE, base-type=uint8, compu {phys=raw}, range phys 0..255
          signal StatusBindingFBD_MM_Data55: start 464, 8 bit, little-endian, data-type-policy=OVERRIDE, base-type=uint8, compu {phys=raw}, range phys 0..255
          signal StatusBindingFBD_MM_Data56: start 472, 8 bit, little-endian, data-type-policy=OVERRIDE, base-type=uint8, compu {phys=raw}, range phys 0..255
          signal StatusBindingFBD_MM_Data57: start 480, 8 bit, little-endian, data-type-policy=OVERRIDE, base-type=uint8, compu {phys=raw}, range phys 0..255
          signal StatusBindingFBD_MM_Data58: start 488, 8 bit, little-endian, data-type-policy=OVERRIDE, base-type=uint8, compu {phys=raw}, range phys 0..255
          signal StatusBindingFBD_MM_Data59: start 496, 8 bit, little-endian, data-type-policy=OVERRIDE, base-type=uint8, compu {phys=raw}, range phys 0..255
          signal StatusBindingFBD_MM_Data60: start 504, 8 bit, little-endian, data-type-policy=OVERRIDE, base-type=uint8, compu {phys=raw}, range phys 0..255
      frame StatusBindingFBD_Trunk: id 0x26F, frame-length=64, can-addressing-mode=STANDARD, can-frame-rx-behavior=CAN-FD, can-frame-tx-behavior=CAN-FD
        pdu StatusBindingFBD_Trunk: length=64, unused-bit-pattern=0
          signal StatusBindingFBD_Trunk_BindingStatus: start 0, 8 bit, little-endian, data-type-policy=OVERRIDE, base-type=uint8, compu {phys=raw}, range phys 0..252
          signal StatusBindingFBD_Trunk_BindingCounter: start 8, 8 bit, little-endian, data-type-policy=OVERRIDE, base-type=uint8, compu {phys=raw}, range phys 0..252
          signal StatusBindingFBD_Trunk_BindingSequence: start 16, 8 bit, little-endian, data-type-policy=OVERRIDE, base-type=uint8, compu {phys=raw}, range phys 0..252
          signal StatusBindingFBD_Trunk_Data00: start 24, 8 bit, little-endian, data-type-policy=OVERRIDE, base-type=uint8, compu {phys=raw}, range phys 0..255
          signal StatusBindingFBD_Trunk_Data01: start 32, 8 bit, little-endian, data-type-policy=OVERRIDE, base-type=uint8, compu {phys=raw}, range phys 0..255
          signal StatusBindingFBD_Trunk_Data02: start 40, 8 bit, little-endian, data-type-policy=OVERRIDE, base-type=uint8, compu {phys=raw}, range phys 0..255
          signal StatusBindingFBD_Trunk_Data03: start 48, 8 bit, little-endian, data-type-policy=OVERRIDE, base-type=uint8, compu {phys=raw}, range phys 0..255
          signal StatusBindingFBD_Trunk_Data04: start 56, 8 bit, little-endian, data-type-policy=OVERRIDE, base-type=uint8, compu {phys=raw}, range phys 0..255
          signal StatusBindingFBD_Trunk_Data05: start 64, 8 bit, little-endian, data-type-policy=OVERRIDE, base-type=uint8, compu {phys=raw}, range phys 0..255
          signal StatusBindingFBD_Trunk_Data06: start 72, 8 bit, little-endian, data-type-policy=OVERRIDE, base-type=uint8, compu {phys=raw}, range phys 0..255
          signal StatusBindingFBD_Trunk_Data07: start 80, 8 bit, little-endian, data-type-policy=OVERRIDE, base-type=uint8, compu {phys=raw}, range phys 0..255
          signal StatusBindingFBD_Trunk_Data08: start 88, 8 bit, little-endian, data-type-policy=OVERRIDE, base-type=uint8, compu {phys=raw}, range phys 0..255
          signal StatusBindingFBD_Trunk_Data09: start 96, 8 bit, little-endian, data-type-policy=OVERRIDE, base-type=uint8, compu {phys=raw}, range phys 0..255
          signal StatusBindingFBD_Trunk_Data10: start 104, 8 bit, little-endian, data-type-policy=OVERRIDE, base-type=uint8, compu {phys=raw}, range phys 0..255
          signal StatusBindingFBD_Trunk_Data11: start 112, 8 bit, little-endian, data-type-policy=OVERRIDE, base-type=uint8, compu {phys=raw}, range phys 0..255
          signal StatusBindingFBD_Trunk_Data12: start 120, 8 bit, little-endian, data-type-policy=OVERRIDE, base-type=uint8, compu {phys=raw}, range phys 0..255
          signal StatusBindingFBD_Trunk_Data13: start 128, 8 bit, little-endian, data-type-policy=OVERRIDE, base-type=uint8, compu {phys=raw}, range phys 0..255
          signal StatusBindingFBD_Trunk_Data14: start 136, 8 bit, little-endian, data-type-policy=OVERRIDE, base-type=uint8, compu {phys=raw}, range phys 0..255
          signal StatusBindingFBD_Trunk_Data15: start 144, 8 bit, little-endian, data-type-policy=OVERRIDE, base-type=uint8, compu {phys=raw}, range phys 0..255
          signal StatusBindingFBD_Trunk_Data16: start 152, 8 bit, little-endian, data-type-policy=OVERRIDE, base-type=uint8, compu {phys=raw}, range phys 0..255
          signal StatusBindingFBD_Trunk_Data17: start 160, 8 bit, little-endian, data-type-policy=OVERRIDE, base-type=uint8, compu {phys=raw}, range phys 0..255
          signal StatusBindingFBD_Trunk_Data18: start 168, 8 bit, little-endian, data-type-policy=OVERRIDE, base-type=uint8, compu {phys=raw}, range phys 0..255
          signal StatusBindingFBD_Trunk_Data19: start 176, 8 bit, little-endian, data-type-policy=OVERRIDE, base-type=uint8, compu {phys=raw}, range phys 0..255
          signal StatusBindingFBD_Trunk_Data20: start 184, 8 bit, little-endian, data-type-policy=OVERRIDE, base-type=uint8, compu {phys=raw}, range phys 0..255
          signal StatusBindingFBD_Trunk_Data21: start 192, 8 bit, little-endian, data-type-policy=OVERRIDE, base-type=uint8, compu {phys=raw}, range phys 0..255
          signal StatusBindingFBD_Trunk_Data22: start 200, 8 bit, little-endian, data-type-policy=OVERRIDE, base-type=uint8, compu {phys=raw}, range phys 0..255
          signal StatusBindingFBD_Trunk_Data23: start 208, 8 bit, little-endian, data-type-policy=OVERRIDE, base-type=uint8, compu {phys=raw}, range phys 0..255
          signal StatusBindingFBD_Trunk_Data24: start 216, 8 bit, little-endian, data-type-policy=OVERRIDE, base-type=uint8, compu {phys=raw}, range phys 0..255
          signal StatusBindingFBD_Trunk_Data25: start 224, 8 bit, little-endian, data-type-policy=OVERRIDE, base-type=uint8, compu {phys=raw}, range phys 0..255
          signal StatusBindingFBD_Trunk_Data26: start 232, 8 bit, little-endian, data-type-policy=OVERRIDE, base-type=uint8, compu {phys=raw}, range phys 0..255
          signal StatusBindingFBD_Trunk_Data27: start 240, 8 bit, little-endian, data-type-policy=OVERRIDE, base-type=uint8, compu {phys=raw}, range phys 0..255
          signal StatusBindingFBD_Trunk_Data28: start 248, 8 bit, little-endian, data-type-policy=OVERRIDE, base-type=uint8, compu {phys=raw}, range phys 0..255
          signal StatusBindingFBD_Trunk_Data29: start 256, 8 bit, little-endian, data-type-policy=OVERRIDE, base-type=uint8, compu {phys=raw}, range phys 0..255
          signal StatusBindingFBD_Trunk_Data30: start 264, 8 bit, little-endian, data-type-policy=OVERRIDE, base-type=uint8, compu {phys=raw}, range phys 0..255
          signal StatusBindingFBD_Trunk_Data31: start 272, 8 bit, little-endian, data-type-policy=OVERRIDE, base-type=uint8, compu {phys=raw}, range phys 0..255
          signal StatusBindingFBD_Trunk_Data32: start 280, 8 bit, little-endian, data-type-policy=OVERRIDE, base-type=uint8, compu {phys=raw}, range phys 0..255
          signal StatusBindingFBD_Trunk_Data33: start 288, 8 bit, little-endian, data-type-policy=OVERRIDE, base-type=uint8, compu {phys=raw}, range phys 0..255
          signal StatusBindingFBD_Trunk_Data34: start 296, 8 bit, little-endian, data-type-policy=OVERRIDE, base-type=uint8, compu {phys=raw}, range phys 0..255
          signal StatusBindingFBD_Trunk_Data35: start 304, 8 bit, little-endian, data-type-policy=OVERRIDE, base-type=uint8, compu {phys=raw}, range phys 0..255
          signal StatusBindingFBD_Trunk_Data36: start 312, 8 bit, little-endian, data-type-policy=OVERRIDE, base-type=uint8, compu {phys=raw}, range phys 0..255
          signal StatusBindingFBD_Trunk_Data37: start 320, 8 bit, little-endian, data-type-policy=OVERRIDE, base-type=uint8, compu {phys=raw}, range phys 0..255
          signal StatusBindingFBD_Trunk_Data38: start 328, 8 bit, little-endian, data-type-policy=OVERRIDE, base-type=uint8, compu {phys=raw}, range phys 0..255
          signal StatusBindingFBD_Trunk_Data39: start 336, 8 bit, little-endian, data-type-policy=OVERRIDE, base-type=uint8, compu {phys=raw}, range phys 0..255
          signal StatusBindingFBD_Trunk_Data40: start 344, 8 bit, little-endian, data-type-policy=OVERRIDE, base-type=uint8, compu {phys=raw}, range phys 0..255
          signal StatusBindingFBD_Trunk_Data41: start 352, 8 bit, little-endian, data-type-policy=OVERRIDE, base-type=uint8, compu {phys=raw}, range phys 0..255
          signal StatusBindingFBD_Trunk_Data42: start 360, 8 bit, little-endian, data-type-policy=OVERRIDE, base-type=uint8, compu {phys=raw}, range phys 0..255
          signal StatusBindingFBD_Trunk_Data43: start 368, 8 bit, little-endian, data-type-policy=OVERRIDE, base-type=uint8, compu {phys=raw}, range phys 0..255
          signal StatusBindingFBD_Trunk_Data44: start 376, 8 bit, little-endian, data-type-policy=OVERRIDE, base-type=uint8, compu {phys=raw}, range phys 0..255
          signal StatusBindingFBD_Trunk_Data45: start 384, 8 bit, little-endian, data-type-policy=OVERRIDE, base-type=uint8, compu {phys=raw}, range phys 0..255
          signal StatusBindingFBD_Trunk_Data46: start 392, 8 bit, little-endian, data-type-policy=OVERRIDE, base-type=uint8, compu {phys=raw}, range phys 0..255
          signal StatusBindingFBD_Trunk_Data47: start 400, 8 bit, little-endian, data-type-policy=OVERRIDE, base-type=uint8, compu {phys=raw}, range phys 0..255
          signal StatusBindingFBD_Trunk_Data48: start 408, 8 bit, little-endian, data-type-policy=OVERRIDE, base-type=uint8, compu {phys=raw}, range phys 0..255
          signal StatusBindingFBD_Trunk_Data49: start 416, 8 bit, little-endian, data-type-policy=OVERRIDE, base-type=uint8, compu {phys=raw}, range phys 0..255
          signal StatusBindingFBD_Trunk_Data50: start 424, 8 bit, little-endian, data-type-policy=OVERRIDE, base-type=uint8, compu {phys=raw}, range phys 0..255
          signal StatusBindingFBD_Trunk_Data51: start 432, 8 bit, little-endian, data-type-policy=OVERRIDE, base-type=uint8, compu {phys=raw}, range phys 0..255
          signal StatusBindingFBD_Trunk_Data52: start 440, 8 bit, little-endian, data-type-policy=OVERRIDE, base-type=uint8, compu {phys=raw}, range phys 0..255
          signal StatusBindingFBD_Trunk_Data53: start 448, 8 bit, little-endian, data-type-policy=OVERRIDE, base-type=uint8, compu {phys=raw}, range phys 0..255
          signal StatusBindingFBD_Trunk_Data54: start 456, 8 bit, little-endian, data-type-policy=OVERRIDE, base-type=uint8, compu {phys=raw}, range phys 0..255
          signal StatusBindingFBD_Trunk_Data55: start 464, 8 bit, little-endian, data-type-policy=OVERRIDE, base-type=uint8, compu {phys=raw}, range phys 0..255
          signal StatusBindingFBD_Trunk_Data56: start 472, 8 bit, little-endian, data-type-policy=OVERRIDE, base-type=uint8, compu {phys=raw}, range phys 0..255
          signal StatusBindingFBD_Trunk_Data57: start 480, 8 bit, little-endian, data-type-policy=OVERRIDE, base-type=uint8, compu {phys=raw}, range phys 0..255
          signal StatusBindingFBD_Trunk_Data58: start 488, 8 bit, little-endian, data-type-policy=OVERRIDE, base-type=uint8, compu {phys=raw}, range phys 0..255
          signal StatusBindingFBD_Trunk_Data59: start 496, 8 bit, little-endian, data-type-policy=OVERRIDE, base-type=uint8, compu {phys=raw}, range phys 0..255
          signal StatusBindingFBD_Trunk_Data60: start 504, 8 bit, little-endian, data-type-policy=OVERRIDE, base-type=uint8, compu {phys=raw}, range phys 0..255
      frame StatusBindingFBD_VL: id 0x270, frame-length=64, can-addressing-mode=STANDARD, can-frame-rx-behavior=CAN-FD, can-frame-tx-behavior=CAN-FD
        pdu StatusBindingFBD_VL: length=64, unused-bit-pattern=0
          signal StatusBindingFBD_VL_BindingStatus: start 0, 8 bit, little-endian, data-type-policy=OVERRIDE, base-type=uint8, compu {phys=raw}, range phys 0..252
          signal StatusBindingFBD_VL_BindingCounter: start 8, 8 bit, little-endian, data-type-policy=OVERRIDE, base-type=uint8, compu {phys=raw}, range phys 0..252
          signal StatusBindingFBD_VL_BindingSequence: start 16, 8 bit, little-endian, data-type-policy=OVERRIDE, base-type=uint8, compu {phys=raw}, range phys 0..252
          signal StatusBindingFBD_VL_Data00: start 24, 8 bit, little-endian, data-type-policy=OVERRIDE, base-type=uint8, compu {phys=raw}, range phys 0..255
          signal StatusBindingFBD_VL_Data01: start 32, 8 bit, little-endian, data-type-policy=OVERRIDE, base-type=uint8, compu {phys=raw}, range phys 0..255
          signal StatusBindingFBD_VL_Data02: start 40, 8 bit, little-endian, data-type-policy=OVERRIDE, base-type=uint8, compu {phys=raw}, range phys 0..255
          signal StatusBindingFBD_VL_Data03: start 48, 8 bit, little-endian, data-type-policy=OVERRIDE, base-type=uint8, compu {phys=raw}, range phys 0..255
          signal StatusBindingFBD_VL_Data04: start 56, 8 bit, little-endian, data-type-policy=OVERRIDE, base-type=uint8, compu {phys=raw}, range phys 0..255
          signal StatusBindingFBD_VL_Data05: start 64, 8 bit, little-endian, data-type-policy=OVERRIDE, base-type=uint8, compu {phys=raw}, range phys 0..255
          signal StatusBindingFBD_VL_Data06: start 72, 8 bit, little-endian, data-type-policy=OVERRIDE, base-type=uint8, compu {phys=raw}, range phys 0..255
          signal StatusBindingFBD_VL_Data07: start 80, 8 bit, little-endian, data-type-policy=OVERRIDE, base-type=uint8, compu {phys=raw}, range phys 0..255
          signal StatusBindingFBD_VL_Data08: start 88, 8 bit, little-endian, data-type-policy=OVERRIDE, base-type=uint8, compu {phys=raw}, range phys 0..255
          signal StatusBindingFBD_VL_Data09: start 96, 8 bit, little-endian, data-type-policy=OVERRIDE, base-type=uint8, compu {phys=raw}, range phys 0..255
          signal StatusBindingFBD_VL_Data10: start 104, 8 bit, little-endian, data-type-policy=OVERRIDE, base-type=uint8, compu {phys=raw}, range phys 0..255
          signal StatusBindingFBD_VL_Data11: start 112, 8 bit, little-endian, data-type-policy=OVERRIDE, base-type=uint8, compu {phys=raw}, range phys 0..255
          signal StatusBindingFBD_VL_Data12: start 120, 8 bit, little-endian, data-type-policy=OVERRIDE, base-type=uint8, compu {phys=raw}, range phys 0..255
          signal StatusBindingFBD_VL_Data13: start 128, 8 bit, little-endian, data-type-policy=OVERRIDE, base-type=uint8, compu {phys=raw}, range phys 0..255
          signal StatusBindingFBD_VL_Data14: start 136, 8 bit, little-endian, data-type-policy=OVERRIDE, base-type=uint8, compu {phys=raw}, range phys 0..255
          signal StatusBindingFBD_VL_Data15: start 144, 8 bit, little-endian, data-type-policy=OVERRIDE, base-type=uint8, compu {phys=raw}, range phys 0..255
          signal StatusBindingFBD_VL_Data16: start 152, 8 bit, little-endian, data-type-policy=OVERRIDE, base-type=uint8, compu {phys=raw}, range phys 0..255
          signal StatusBindingFBD_VL_Data17: start 160, 8 bit, little-endian, data-type-policy=OVERRIDE, base-type=uint8, compu {phys=raw}, range phys 0..255
          signal StatusBindingFBD_VL_Data18: start 168, 8 bit, little-endian, data-type-policy=OVERRIDE, base-type=uint8, compu {phys=raw}, range phys 0..255
          signal StatusBindingFBD_VL_Data19: start 176, 8 bit, little-endian, data-type-policy=OVERRIDE, base-type=uint8, compu {phys=raw}, range phys 0..255
          signal StatusBindingFBD_VL_Data20: start 184, 8 bit, little-endian, data-type-policy=OVERRIDE, base-type=uint8, compu {phys=raw}, range phys 0..255
          signal StatusBindingFBD_VL_Data21: start 192, 8 bit, little-endian, data-type-policy=OVERRIDE, base-type=uint8, compu {phys=raw}, range phys 0..255
          signal StatusBindingFBD_VL_Data22: start 200, 8 bit, little-endian, data-type-policy=OVERRIDE, base-type=uint8, compu {phys=raw}, range phys 0..255
          signal StatusBindingFBD_VL_Data23: start 208, 8 bit, little-endian, data-type-policy=OVERRIDE, base-type=uint8, compu {phys=raw}, range phys 0..255
          signal StatusBindingFBD_VL_Data24: start 216, 8 bit, little-endian, data-type-policy=OVERRIDE, base-type=uint8, compu {phys=raw}, range phys 0..255
          signal StatusBindingFBD_VL_Data25: start 224, 8 bit, little-endian, data-type-policy=OVERRIDE, base-type=uint8, compu {phys=raw}, range phys 0..255
          signal StatusBindingFBD_VL_Data26: start 232, 8 bit, little-endian, data-type-policy=OVERRIDE, base-type=uint8, compu {phys=raw}, range phys 0..255
          signal StatusBindingFBD_VL_Data27: start 240, 8 bit, little-endian, data-type-policy=OVERRIDE, base-type=uint8, compu {phys=raw}, range phys 0..255
          signal StatusBindingFBD_VL_Data28: start 248, 8 bit, little-endian, data-type-policy=OVERRIDE, base-type=uint8, compu {phys=raw}, range phys 0..255
          signal StatusBindingFBD_VL_Data29: start 256, 8 bit, little-endian, data-type-policy=OVERRIDE, base-type=uint8, compu {phys=raw}, range phys 0..255
          signal StatusBindingFBD_VL_Data30: start 264, 8 bit, little-endian, data-type-policy=OVERRIDE, base-type=uint8, compu {phys=raw}, range phys 0..255
          signal StatusBindingFBD_VL_Data31: start 272, 8 bit, little-endian, data-type-policy=OVERRIDE, base-type=uint8, compu {phys=raw}, range phys 0..255
          signal StatusBindingFBD_VL_Data32: start 280, 8 bit, little-endian, data-type-policy=OVERRIDE, base-type=uint8, compu {phys=raw}, range phys 0..255
          signal StatusBindingFBD_VL_Data33: start 288, 8 bit, little-endian, data-type-policy=OVERRIDE, base-type=uint8, compu {phys=raw}, range phys 0..255
          signal StatusBindingFBD_VL_Data34: start 296, 8 bit, little-endian, data-type-policy=OVERRIDE, base-type=uint8, compu {phys=raw}, range phys 0..255
          signal StatusBindingFBD_VL_Data35: start 304, 8 bit, little-endian, data-type-policy=OVERRIDE, base-type=uint8, compu {phys=raw}, range phys 0..255
          signal StatusBindingFBD_VL_Data36: start 312, 8 bit, little-endian, data-type-policy=OVERRIDE, base-type=uint8, compu {phys=raw}, range phys 0..255
          signal StatusBindingFBD_VL_Data37: start 320, 8 bit, little-endian, data-type-policy=OVERRIDE, base-type=uint8, compu {phys=raw}, range phys 0..255
          signal StatusBindingFBD_VL_Data38: start 328, 8 bit, little-endian, data-type-policy=OVERRIDE, base-type=uint8, compu {phys=raw}, range phys 0..255
          signal StatusBindingFBD_VL_Data39: start 336, 8 bit, little-endian, data-type-policy=OVERRIDE, base-type=uint8, compu {phys=raw}, range phys 0..255
          signal StatusBindingFBD_VL_Data40: start 344, 8 bit, little-endian, data-type-policy=OVERRIDE, base-type=uint8, compu {phys=raw}, range phys 0..255
          signal StatusBindingFBD_VL_Data41: start 352, 8 bit, little-endian, data-type-policy=OVERRIDE, base-type=uint8, compu {phys=raw}, range phys 0..255
          signal StatusBindingFBD_VL_Data42: start 360, 8 bit, little-endian, data-type-policy=OVERRIDE, base-type=uint8, compu {phys=raw}, range phys 0..255
          signal StatusBindingFBD_VL_Data43: start 368, 8 bit, little-endian, data-type-policy=OVERRIDE, base-type=uint8, compu {phys=raw}, range phys 0..255
          signal StatusBindingFBD_VL_Data44: start 376, 8 bit, little-endian, data-type-policy=OVERRIDE, base-type=uint8, compu {phys=raw}, range phys 0..255
          signal StatusBindingFBD_VL_Data45: start 384, 8 bit, little-endian, data-type-policy=OVERRIDE, base-type=uint8, compu {phys=raw}, range phys 0..255
          signal StatusBindingFBD_VL_Data46: start 392, 8 bit, little-endian, data-type-policy=OVERRIDE, base-type=uint8, compu {phys=raw}, range phys 0..255
          signal StatusBindingFBD_VL_Data47: start 400, 8 bit, little-endian, data-type-policy=OVERRIDE, base-type=uint8, compu {phys=raw}, range phys 0..255
          signal StatusBindingFBD_VL_Data48: start 408, 8 bit, little-endian, data-type-policy=OVERRIDE, base-type=uint8, compu {phys=raw}, range phys 0..255
          signal StatusBindingFBD_VL_Data49: start 416, 8 bit, little-endian, data-type-policy=OVERRIDE, base-type=uint8, compu {phys=raw}, range phys 0..255
          signal StatusBindingFBD_VL_Data50: start 424, 8 bit, little-endian, data-type-policy=OVERRIDE, base-type=uint8, compu {phys=raw}, range phys 0..255
          signal StatusBindingFBD_VL_Data51: start 432, 8 bit, little-endian, data-type-policy=OVERRIDE, base-type=uint8, compu {phys=raw}, range phys 0..255
          signal StatusBindingFBD_VL_Data52: start 440, 8 bit, little-endian, data-type-policy=OVERRIDE, base-type=uint8, compu {phys=raw}, range phys 0..255
          signal StatusBindingFBD_VL_Data53: start 448, 8 bit, little-endian, data-type-policy=OVERRIDE, base-type=uint8, compu {phys=raw}, range phys 0..255
          signal StatusBindingFBD_VL_Data54: start 456, 8 bit, little-endian, data-type-policy=OVERRIDE, base-type=uint8, compu {phys=raw}, range phys 0..255
          signal StatusBindingFBD_VL_Data55: start 464, 8 bit, little-endian, data-type-policy=OVERRIDE, base-type=uint8, compu {phys=raw}, range phys 0..255
          signal StatusBindingFBD_VL_Data56: start 472, 8 bit, little-endian, data-type-policy=OVERRIDE, base-type=uint8, compu {phys=raw}, range phys 0..255
          signal StatusBindingFBD_VL_Data57: start 480, 8 bit, little-endian, data-type-policy=OVERRIDE, base-type=uint8, compu {phys=raw}, range phys 0..255
          signal StatusBindingFBD_VL_Data58: start 488, 8 bit, little-endian, data-type-policy=OVERRIDE, base-type=uint8, compu {phys=raw}, range phys 0..255
          signal StatusBindingFBD_VL_Data59: start 496, 8 bit, little-endian, data-type-policy=OVERRIDE, base-type=uint8, compu {phys=raw}, range phys 0..255
          signal StatusBindingFBD_VL_Data60: start 504, 8 bit, little-endian, data-type-policy=OVERRIDE, base-type=uint8, compu {phys=raw}, range phys 0..255
      frame StatusBindingFBD_VM: id 0x26C, frame-length=64, can-addressing-mode=STANDARD, can-frame-rx-behavior=CAN-FD, can-frame-tx-behavior=CAN-FD
        pdu StatusBindingFBD_VM: length=64, unused-bit-pattern=0
          signal StatusBindingFBD_VM_BindingStatus: start 0, 8 bit, little-endian, data-type-policy=OVERRIDE, base-type=uint8, compu {phys=raw}, range phys 0..252
          signal StatusBindingFBD_VM_BindingCounter: start 8, 8 bit, little-endian, data-type-policy=OVERRIDE, base-type=uint8, compu {phys=raw}, range phys 0..252
          signal StatusBindingFBD_VM_BindingSequence: start 16, 8 bit, little-endian, data-type-policy=OVERRIDE, base-type=uint8, compu {phys=raw}, range phys 0..252
          signal StatusBindingFBD_VM_Data00: start 24, 8 bit, little-endian, data-type-policy=OVERRIDE, base-type=uint8, compu {phys=raw}, range phys 0..255
          signal StatusBindingFBD_VM_Data01: start 32, 8 bit, little-endian, data-type-policy=OVERRIDE, base-type=uint8, compu {phys=raw}, range phys 0..255
          signal StatusBindingFBD_VM_Data02: start 40, 8 bit, little-endian, data-type-policy=OVERRIDE, base-type=uint8, compu {phys=raw}, range phys 0..255
          signal StatusBindingFBD_VM_Data03: start 48, 8 bit, little-endian, data-type-policy=OVERRIDE, base-type=uint8, compu {phys=raw}, range phys 0..255
          signal StatusBindingFBD_VM_Data04: start 56, 8 bit, little-endian, data-type-policy=OVERRIDE, base-type=uint8, compu {phys=raw}, range phys 0..255
          signal StatusBindingFBD_VM_Data05: start 64, 8 bit, little-endian, data-type-policy=OVERRIDE, base-type=uint8, compu {phys=raw}, range phys 0..255
          signal StatusBindingFBD_VM_Data06: start 72, 8 bit, little-endian, data-type-policy=OVERRIDE, base-type=uint8, compu {phys=raw}, range phys 0..255
          signal StatusBindingFBD_VM_Data07: start 80, 8 bit, little-endian, data-type-policy=OVERRIDE, base-type=uint8, compu {phys=raw}, range phys 0..255
          signal StatusBindingFBD_VM_Data08: start 88, 8 bit, little-endian, data-type-policy=OVERRIDE, base-type=uint8, compu {phys=raw}, range phys 0..255
          signal StatusBindingFBD_VM_Data09: start 96, 8 bit, little-endian, data-type-policy=OVERRIDE, base-type=uint8, compu {phys=raw}, range phys 0..255
          signal StatusBindingFBD_VM_Data10: start 104, 8 bit, little-endian, data-type-policy=OVERRIDE, base-type=uint8, compu {phys=raw}, range phys 0..255
          signal StatusBindingFBD_VM_Data11: start 112, 8 bit, little-endian, data-type-policy=OVERRIDE, base-type=uint8, compu {phys=raw}, range phys 0..255
          signal StatusBindingFBD_VM_Data12: start 120, 8 bit, little-endian, data-type-policy=OVERRIDE, base-type=uint8, compu {phys=raw}, range phys 0..255
          signal StatusBindingFBD_VM_Data13: start 128, 8 bit, little-endian, data-type-policy=OVERRIDE, base-type=uint8, compu {phys=raw}, range phys 0..255
          signal StatusBindingFBD_VM_Data14: start 136, 8 bit, little-endian, data-type-policy=OVERRIDE, base-type=uint8, compu {phys=raw}, range phys 0..255
          signal StatusBindingFBD_VM_Data15: start 144, 8 bit, little-endian, data-type-policy=OVERRIDE, base-type=uint8, compu {phys=raw}, range phys 0..255
          signal StatusBindingFBD_VM_Data16: start 152, 8 bit, little-endian, data-type-policy=OVERRIDE, base-type=uint8, compu {phys=raw}, range phys 0..255
          signal StatusBindingFBD_VM_Data17: start 160, 8 bit, little-endian, data-type-policy=OVERRIDE, base-type=uint8, compu {phys=raw}, range phys 0..255
          signal StatusBindingFBD_VM_Data18: start 168, 8 bit, little-endian, data-type-policy=OVERRIDE, base-type=uint8, compu {phys=raw}, range phys 0..255
          signal StatusBindingFBD_VM_Data19: start 176, 8 bit, little-endian, data-type-policy=OVERRIDE, base-type=uint8, compu {phys=raw}, range phys 0..255
          signal StatusBindingFBD_VM_Data20: start 184, 8 bit, little-endian, data-type-policy=OVERRIDE, base-type=uint8, compu {phys=raw}, range phys 0..255
          signal StatusBindingFBD_VM_Data21: start 192, 8 bit, little-endian, data-type-policy=OVERRIDE, base-type=uint8, compu {phys=raw}, range phys 0..255
          signal StatusBindingFBD_VM_Data22: start 200, 8 bit, little-endian, data-type-policy=OVERRIDE, base-type=uint8, compu {phys=raw}, range phys 0..255
          signal StatusBindingFBD_VM_Data23: start 208, 8 bit, little-endian, data-type-policy=OVERRIDE, base-type=uint8, compu {phys=raw}, range phys 0..255
          signal StatusBindingFBD_VM_Data24: start 216, 8 bit, little-endian, data-type-policy=OVERRIDE, base-type=uint8, compu {phys=raw}, range phys 0..255
          signal StatusBindingFBD_VM_Data25: start 224, 8 bit, little-endian, data-type-policy=OVERRIDE, base-type=uint8, compu {phys=raw}, range phys 0..255
          signal StatusBindingFBD_VM_Data26: start 232, 8 bit, little-endian, data-type-policy=OVERRIDE, base-type=uint8, compu {phys=raw}, range phys 0..255
          signal StatusBindingFBD_VM_Data27: start 240, 8 bit, little-endian, data-type-policy=OVERRIDE, base-type=uint8, compu {phys=raw}, range phys 0..255
          signal StatusBindingFBD_VM_Data28: start 248, 8 bit, little-endian, data-type-policy=OVERRIDE, base-type=uint8, compu {phys=raw}, range phys 0..255
          signal StatusBindingFBD_VM_Data29: start 256, 8 bit, little-endian, data-type-policy=OVERRIDE, base-type=uint8, compu {phys=raw}, range phys 0..255
          signal StatusBindingFBD_VM_Data30: start 264, 8 bit, little-endian, data-type-policy=OVERRIDE, base-type=uint8, compu {phys=raw}, range phys 0..255
          signal StatusBindingFBD_VM_Data31: start 272, 8 bit, little-endian, data-type-policy=OVERRIDE, base-type=uint8, compu {phys=raw}, range phys 0..255
          signal StatusBindingFBD_VM_Data32: start 280, 8 bit, little-endian, data-type-policy=OVERRIDE, base-type=uint8, compu {phys=raw}, range phys 0..255
          signal StatusBindingFBD_VM_Data33: start 288, 8 bit, little-endian, data-type-policy=OVERRIDE, base-type=uint8, compu {phys=raw}, range phys 0..255
          signal StatusBindingFBD_VM_Data34: start 296, 8 bit, little-endian, data-type-policy=OVERRIDE, base-type=uint8, compu {phys=raw}, range phys 0..255
          signal StatusBindingFBD_VM_Data35: start 304, 8 bit, little-endian, data-type-policy=OVERRIDE, base-type=uint8, compu {phys=raw}, range phys 0..255
          signal StatusBindingFBD_VM_Data36: start 312, 8 bit, little-endian, data-type-policy=OVERRIDE, base-type=uint8, compu {phys=raw}, range phys 0..255
          signal StatusBindingFBD_VM_Data37: start 320, 8 bit, little-endian, data-type-policy=OVERRIDE, base-type=uint8, compu {phys=raw}, range phys 0..255
          signal StatusBindingFBD_VM_Data38: start 328, 8 bit, little-endian, data-type-policy=OVERRIDE, base-type=uint8, compu {phys=raw}, range phys 0..255
          signal StatusBindingFBD_VM_Data39: start 336, 8 bit, little-endian, data-type-policy=OVERRIDE, base-type=uint8, compu {phys=raw}, range phys 0..255
          signal StatusBindingFBD_VM_Data40: start 344, 8 bit, little-endian, data-type-policy=OVERRIDE, base-type=uint8, compu {phys=raw}, range phys 0..255
          signal StatusBindingFBD_VM_Data41: start 352, 8 bit, little-endian, data-type-policy=OVERRIDE, base-type=uint8, compu {phys=raw}, range phys 0..255
          signal StatusBindingFBD_VM_Data42: start 360, 8 bit, little-endian, data-type-policy=OVERRIDE, base-type=uint8, compu {phys=raw}, range phys 0..255
          signal StatusBindingFBD_VM_Data43: start 368, 8 bit, little-endian, data-type-policy=OVERRIDE, base-type=uint8, compu {phys=raw}, range phys 0..255
          signal StatusBindingFBD_VM_Data44: start 376, 8 bit, little-endian, data-type-policy=OVERRIDE, base-type=uint8, compu {phys=raw}, range phys 0..255
          signal StatusBindingFBD_VM_Data45: start 384, 8 bit, little-endian, data-type-policy=OVERRIDE, base-type=uint8, compu {phys=raw}, range phys 0..255
          signal StatusBindingFBD_VM_Data46: start 392, 8 bit, little-endian, data-type-policy=OVERRIDE, base-type=uint8, compu {phys=raw}, range phys 0..255
          signal StatusBindingFBD_VM_Data47: start 400, 8 bit, little-endian, data-type-policy=OVERRIDE, base-type=uint8, compu {phys=raw}, range phys 0..255
          signal StatusBindingFBD_VM_Data48: start 408, 8 bit, little-endian, data-type-policy=OVERRIDE, base-type=uint8, compu {phys=raw}, range phys 0..255
          signal StatusBindingFBD_VM_Data49: start 416, 8 bit, little-endian, data-type-policy=OVERRIDE, base-type=uint8, compu {phys=raw}, range phys 0..255
          signal StatusBindingFBD_VM_Data50: start 424, 8 bit, little-endian, data-type-policy=OVERRIDE, base-type=uint8, compu {phys=raw}, range phys 0..255
          signal StatusBindingFBD_VM_Data51: start 432, 8 bit, little-endian, data-type-policy=OVERRIDE, base-type=uint8, compu {phys=raw}, range phys 0..255
          signal StatusBindingFBD_VM_Data52: start 440, 8 bit, little-endian, data-type-policy=OVERRIDE, base-type=uint8, compu {phys=raw}, range phys 0..255
          signal StatusBindingFBD_VM_Data53: start 448, 8 bit, little-endian, data-type-policy=OVERRIDE, base-type=uint8, compu {phys=raw}, range phys 0..255
          signal StatusBindingFBD_VM_Data54: start 456, 8 bit, little-endian, data-type-policy=OVERRIDE, base-type=uint8, compu {phys=raw}, range phys 0..255
          signal StatusBindingFBD_VM_Data55: start 464, 8 bit, little-endian, data-type-policy=OVERRIDE, base-type=uint8, compu {phys=raw}, range phys 0..255
          signal StatusBindingFBD_VM_Data56: start 472, 8 bit, little-endian, data-type-policy=OVERRIDE, base-type=uint8, compu {phys=raw}, range phys 0..255
          signal StatusBindingFBD_VM_Data57: start 480, 8 bit, little-endian, data-type-policy=OVERRIDE, base-type=uint8, compu {phys=raw}, range phys 0..255
          signal StatusBindingFBD_VM_Data58: start 488, 8 bit, little-endian, data-type-policy=OVERRIDE, base-type=uint8, compu {phys=raw}, range phys 0..255
          signal StatusBindingFBD_VM_Data59: start 496, 8 bit, little-endian, data-type-policy=OVERRIDE, base-type=uint8, compu {phys=raw}, range phys 0..255
          signal StatusBindingFBD_VM_Data60: start 504, 8 bit, little-endian, data-type-policy=OVERRIDE, base-type=uint8, compu {phys=raw}, range phys 0..255
      frame StatusBindingFBD_VR: id 0x271, frame-length=64, can-addressing-mode=STANDARD, can-frame-rx-behavior=CAN-FD, can-frame-tx-behavior=CAN-FD
        pdu StatusBindingFBD_VR: length=64, unused-bit-pattern=0
          signal StatusBindingFBD_VR_BindingStatus: start 0, 8 bit, little-endian, data-type-policy=OVERRIDE, base-type=uint8, compu {phys=raw}, range phys 0..252
          signal StatusBindingFBD_VR_BindingCounter: start 8, 8 bit, little-endian, data-type-policy=OVERRIDE, base-type=uint8, compu {phys=raw}, range phys 0..252
          signal StatusBindingFBD_VR_BindingSequence: start 16, 8 bit, little-endian, data-type-policy=OVERRIDE, base-type=uint8, compu {phys=raw}, range phys 0..252
          signal StatusBindingFBD_VR_Data00: start 24, 8 bit, little-endian, data-type-policy=OVERRIDE, base-type=uint8, compu {phys=raw}, range phys 0..255
          signal StatusBindingFBD_VR_Data01: start 32, 8 bit, little-endian, data-type-policy=OVERRIDE, base-type=uint8, compu {phys=raw}, range phys 0..255
          signal StatusBindingFBD_VR_Data02: start 40, 8 bit, little-endian, data-type-policy=OVERRIDE, base-type=uint8, compu {phys=raw}, range phys 0..255
          signal StatusBindingFBD_VR_Data03: start 48, 8 bit, little-endian, data-type-policy=OVERRIDE, base-type=uint8, compu {phys=raw}, range phys 0..255
          signal StatusBindingFBD_VR_Data04: start 56, 8 bit, little-endian, data-type-policy=OVERRIDE, base-type=uint8, compu {phys=raw}, range phys 0..255
          signal StatusBindingFBD_VR_Data05: start 64, 8 bit, little-endian, data-type-policy=OVERRIDE, base-type=uint8, compu {phys=raw}, range phys 0..255
          signal StatusBindingFBD_VR_Data06: start 72, 8 bit, little-endian, data-type-policy=OVERRIDE, base-type=uint8, compu {phys=raw}, range phys 0..255
          signal StatusBindingFBD_VR_Data07: start 80, 8 bit, little-endian, data-type-policy=OVERRIDE, base-type=uint8, compu {phys=raw}, range phys 0..255
          signal StatusBindingFBD_VR_Data08: start 88, 8 bit, little-endian, data-type-policy=OVERRIDE, base-type=uint8, compu {phys=raw}, range phys 0..255
          signal StatusBindingFBD_VR_Data09: start 96, 8 bit, little-endian, data-type-policy=OVERRIDE, base-type=uint8, compu {phys=raw}, range phys 0..255
          signal StatusBindingFBD_VR_Data10: start 104, 8 bit, little-endian, data-type-policy=OVERRIDE, base-type=uint8, compu {phys=raw}, range phys 0..255
          signal StatusBindingFBD_VR_Data11: start 112, 8 bit, little-endian, data-type-policy=OVERRIDE, base-type=uint8, compu {phys=raw}, range phys 0..255
          signal StatusBindingFBD_VR_Data12: start 120, 8 bit, little-endian, data-type-policy=OVERRIDE, base-type=uint8, compu {phys=raw}, range phys 0..255
          signal StatusBindingFBD_VR_Data13: start 128, 8 bit, little-endian, data-type-policy=OVERRIDE, base-type=uint8, compu {phys=raw}, range phys 0..255
          signal StatusBindingFBD_VR_Data14: start 136, 8 bit, little-endian, data-type-policy=OVERRIDE, base-type=uint8, compu {phys=raw}, range phys 0..255
          signal StatusBindingFBD_VR_Data15: start 144, 8 bit, little-endian, data-type-policy=OVERRIDE, base-type=uint8, compu {phys=raw}, range phys 0..255
          signal StatusBindingFBD_VR_Data16: start 152, 8 bit, little-endian, data-type-policy=OVERRIDE, base-type=uint8, compu {phys=raw}, range phys 0..255
          signal StatusBindingFBD_VR_Data17: start 160, 8 bit, little-endian, data-type-policy=OVERRIDE, base-type=uint8, compu {phys=raw}, range phys 0..255
          signal StatusBindingFBD_VR_Data18: start 168, 8 bit, little-endian, data-type-policy=OVERRIDE, base-type=uint8, compu {phys=raw}, range phys 0..255
          signal StatusBindingFBD_VR_Data19: start 176, 8 bit, little-endian, data-type-policy=OVERRIDE, base-type=uint8, compu {phys=raw}, range phys 0..255
          signal StatusBindingFBD_VR_Data20: start 184, 8 bit, little-endian, data-type-policy=OVERRIDE, base-type=uint8, compu {phys=raw}, range phys 0..255
          signal StatusBindingFBD_VR_Data21: start 192, 8 bit, little-endian, data-type-policy=OVERRIDE, base-type=uint8, compu {phys=raw}, range phys 0..255
          signal StatusBindingFBD_VR_Data22: start 200, 8 bit, little-endian, data-type-policy=OVERRIDE, base-type=uint8, compu {phys=raw}, range phys 0..255
          signal StatusBindingFBD_VR_Data23: start 208, 8 bit, little-endian, data-type-policy=OVERRIDE, base-type=uint8, compu {phys=raw}, range phys 0..255
          signal StatusBindingFBD_VR_Data24: start 216, 8 bit, little-endian, data-type-policy=OVERRIDE, base-type=uint8, compu {phys=raw}, range phys 0..255
          signal StatusBindingFBD_VR_Data25: start 224, 8 bit, little-endian, data-type-policy=OVERRIDE, base-type=uint8, compu {phys=raw}, range phys 0..255
          signal StatusBindingFBD_VR_Data26: start 232, 8 bit, little-endian, data-type-policy=OVERRIDE, base-type=uint8, compu {phys=raw}, range phys 0..255
          signal StatusBindingFBD_VR_Data27: start 240, 8 bit, little-endian, data-type-policy=OVERRIDE, base-type=uint8, compu {phys=raw}, range phys 0..255
          signal StatusBindingFBD_VR_Data28: start 248, 8 bit, little-endian, data-type-policy=OVERRIDE, base-type=uint8, compu {phys=raw}, range phys 0..255
          signal StatusBindingFBD_VR_Data29: start 256, 8 bit, little-endian, data-type-policy=OVERRIDE, base-type=uint8, compu {phys=raw}, range phys 0..255
          signal StatusBindingFBD_VR_Data30: start 264, 8 bit, little-endian, data-type-policy=OVERRIDE, base-type=uint8, compu {phys=raw}, range phys 0..255
          signal StatusBindingFBD_VR_Data31: start 272, 8 bit, little-endian, data-type-policy=OVERRIDE, base-type=uint8, compu {phys=raw}, range phys 0..255
          signal StatusBindingFBD_VR_Data32: start 280, 8 bit, little-endian, data-type-policy=OVERRIDE, base-type=uint8, compu {phys=raw}, range phys 0..255
          signal StatusBindingFBD_VR_Data33: start 288, 8 bit, little-endian, data-type-policy=OVERRIDE, base-type=uint8, compu {phys=raw}, range phys 0..255
          signal StatusBindingFBD_VR_Data34: start 296, 8 bit, little-endian, data-type-policy=OVERRIDE, base-type=uint8, compu {phys=raw}, range phys 0..255
          signal StatusBindingFBD_VR_Data35: start 304, 8 bit, little-endian, data-type-policy=OVERRIDE, base-type=uint8, compu {phys=raw}, range phys 0..255
          signal StatusBindingFBD_VR_Data36: start 312, 8 bit, little-endian, data-type-policy=OVERRIDE, base-type=uint8, compu {phys=raw}, range phys 0..255
          signal StatusBindingFBD_VR_Data37: start 320, 8 bit, little-endian, data-type-policy=OVERRIDE, base-type=uint8, compu {phys=raw}, range phys 0..255
          signal StatusBindingFBD_VR_Data38: start 328, 8 bit, little-endian, data-type-policy=OVERRIDE, base-type=uint8, compu {phys=raw}, range phys 0..255
          signal StatusBindingFBD_VR_Data39: start 336, 8 bit, little-endian, data-type-policy=OVERRIDE, base-type=uint8, compu {phys=raw}, range phys 0..255
          signal StatusBindingFBD_VR_Data40: start 344, 8 bit, little-endian, data-type-policy=OVERRIDE, base-type=uint8, compu {phys=raw}, range phys 0..255
          signal StatusBindingFBD_VR_Data41: start 352, 8 bit, little-endian, data-type-policy=OVERRIDE, base-type=uint8, compu {phys=raw}, range phys 0..255
          signal StatusBindingFBD_VR_Data42: start 360, 8 bit, little-endian, data-type-policy=OVERRIDE, base-type=uint8, compu {phys=raw}, range phys 0..255
          signal StatusBindingFBD_VR_Data43: start 368, 8 bit, little-endian, data-type-policy=OVERRIDE, base-type=uint8, compu {phys=raw}, range phys 0..255
          signal StatusBindingFBD_VR_Data44: start 376, 8 bit, little-endian, data-type-policy=OVERRIDE, base-type=uint8, compu {phys=raw}, range phys 0..255
          signal StatusBindingFBD_VR_Data45: start 384, 8 bit, little-endian, data-type-policy=OVERRIDE, base-type=uint8, compu {phys=raw}, range phys 0..255
          signal StatusBindingFBD_VR_Data46: start 392, 8 bit, little-endian, data-type-policy=OVERRIDE, base-type=uint8, compu {phys=raw}, range phys 0..255
          signal StatusBindingFBD_VR_Data47: start 400, 8 bit, little-endian, data-type-policy=OVERRIDE, base-type=uint8, compu {phys=raw}, range phys 0..255
          signal StatusBindingFBD_VR_Data48: start 408, 8 bit, little-endian, data-type-policy=OVERRIDE, base-type=uint8, compu {phys=raw}, range phys 0..255
          signal StatusBindingFBD_VR_Data49: start 416, 8 bit, little-endian, data-type-policy=OVERRIDE, base-type=uint8, compu {phys=raw}, range phys 0..255
          signal StatusBindingFBD_VR_Data50: start 424, 8 bit, little-endian, data-type-policy=OVERRIDE, base-type=uint8, compu {phys=raw}, range phys 0..255
          signal StatusBindingFBD_VR_Data51: start 432, 8 bit, little-endian, data-type-policy=OVERRIDE, base-type=uint8, compu {phys=raw}, range phys 0..255
          signal StatusBindingFBD_VR_Data52: start 440, 8 bit, little-endian, data-type-policy=OVERRIDE, base-type=uint8, compu {phys=raw}, range phys 0..255
          signal StatusBindingFBD_VR_Data53: start 448, 8 bit, little-endian, data-type-policy=OVERRIDE, base-type=uint8, compu {phys=raw}, range phys 0..255
          signal StatusBindingFBD_VR_Data54: start 456, 8 bit, little-endian, data-type-policy=OVERRIDE, base-type=uint8, compu {phys=raw}, range phys 0..255
          signal StatusBindingFBD_VR_Data55: start 464, 8 bit, little-endian, data-type-policy=OVERRIDE, base-type=uint8, compu {phys=raw}, range phys 0..255
          signal StatusBindingFBD_VR_Data56: start 472, 8 bit, little-endian, data-type-policy=OVERRIDE, base-type=uint8, compu {phys=raw}, range phys 0..255
          signal StatusBindingFBD_VR_Data57: start 480, 8 bit, little-endian, data-type-policy=OVERRIDE, base-type=uint8, compu {phys=raw}, range phys 0..255
          signal StatusBindingFBD_VR_Data58: start 488, 8 bit, little-endian, data-type-policy=OVERRIDE, base-type=uint8, compu {phys=raw}, range phys 0..255
          signal StatusBindingFBD_VR_Data59: start 496, 8 bit, little-endian, data-type-policy=OVERRIDE, base-type=uint8, compu {phys=raw}, range phys 0..255
          signal StatusBindingFBD_VR_Data60: start 504, 8 bit, little-endian, data-type-policy=OVERRIDE, base-type=uint8, compu {phys=raw}, range phys 0..255
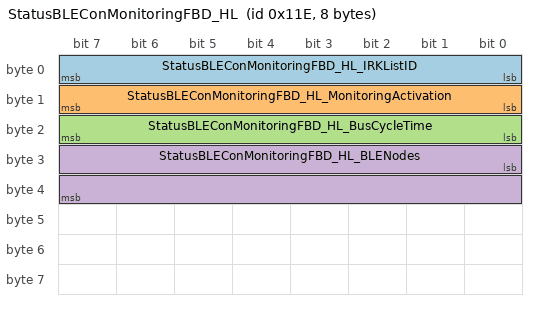
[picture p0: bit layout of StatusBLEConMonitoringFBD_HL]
      frame StatusBLEConMonitoringFBD_HL: id 0x11E, frame-length=8, can-addressing-mode=STANDARD, can-frame-rx-behavior=CAN-20, can-frame-tx-behavior=CAN-20
        pdu StatusBLEConMonitoringFBD_HL: length=8, unused-bit-pattern=0
          signal StatusBLEConMonitoringFBD_HL_IRKListID: start 0, 8 bit, little-endian, data-type-policy=OVERRIDE, base-type=uint8, compu {phys=raw}, range phys 0..252
          signal StatusBLEConMonitoringFBD_HL_MonitoringActivation: start 8, 8 bit, little-endian, data-type-policy=OVERRIDE, compu {phys=raw}
          signal StatusBLEConMonitoringFBD_HL_BusCycleTime: start 16, 8 bit, little-endian, data-type-policy=OVERRIDE, base-type=uint8, compu {phys=raw*10; unit ms}, range phys 0..252
          signal StatusBLEConMonitoringFBD_HL_BLENodes: start 24, 16 bit, little-endian, data-type-policy=OVERRIDE, compu {phys=raw}
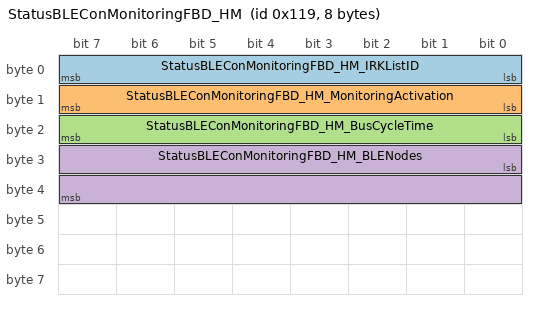
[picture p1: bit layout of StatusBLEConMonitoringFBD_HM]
      frame StatusBLEConMonitoringFBD_HM: id 0x119, frame-length=8, can-addressing-mode=STANDARD, can-frame-rx-behavior=CAN-20, can-frame-tx-behavior=CAN-20
        pdu StatusBLEConMonitoringFBD_HM: length=8, unused-bit-pattern=0
          signal StatusBLEConMonitoringFBD_HM_IRKListID: start 0, 8 bit, little-endian, data-type-policy=OVERRIDE, base-type=uint8, compu {phys=raw}, range phys 0..252
          signal StatusBLEConMonitoringFBD_HM_MonitoringActivation: start 8, 8 bit, little-endian, data-type-policy=OVERRIDE, compu {phys=raw}
          signal StatusBLEConMonitoringFBD_HM_BusCycleTime: start 16, 8 bit, little-endian, data-type-policy=OVERRIDE, base-type=uint8, compu {phys=raw*10; unit ms}, range phys 0..252
          signal StatusBLEConMonitoringFBD_HM_BLENodes: start 24, 16 bit, little-endian, data-type-policy=OVERRIDE, compu {phys=raw}
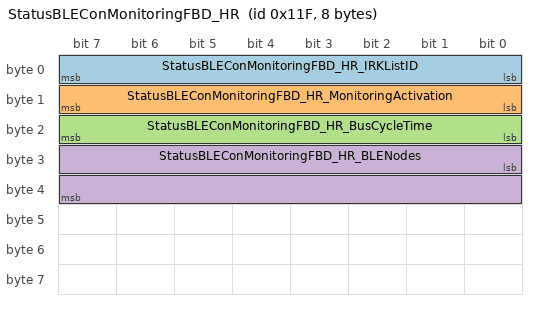
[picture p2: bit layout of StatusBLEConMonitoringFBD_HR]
      frame StatusBLEConMonitoringFBD_HR: id 0x11F, frame-length=8, can-addressing-mode=STANDARD, can-frame-rx-behavior=CAN-20, can-frame-tx-behavior=CAN-20
        pdu StatusBLEConMonitoringFBD_HR: length=8, unused-bit-pattern=0
          signal StatusBLEConMonitoringFBD_HR_IRKListID: start 0, 8 bit, little-endian, data-type-policy=OVERRIDE, base-type=uint8, compu {phys=raw}, range phys 0..252
          signal StatusBLEConMonitoringFBD_HR_MonitoringActivation: start 8, 8 bit, little-endian, data-type-policy=OVERRIDE, compu {phys=raw}
          signal StatusBLEConMonitoringFBD_HR_BusCycleTime: start 16, 8 bit, little-endian, data-type-policy=OVERRIDE, base-type=uint8, compu {phys=raw*10; unit ms}, range phys 0..252
          signal StatusBLEConMonitoringFBD_HR_BLENodes: start 24, 16 bit, little-endian, data-type-policy=OVERRIDE, compu {phys=raw}
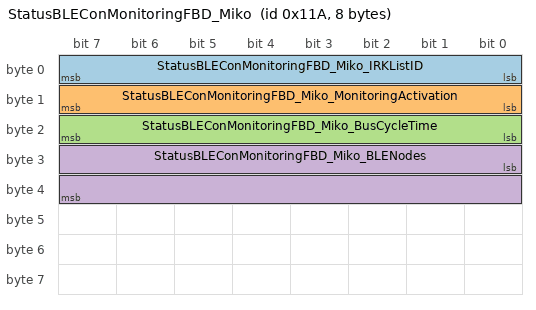
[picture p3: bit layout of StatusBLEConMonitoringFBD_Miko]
      frame StatusBLEConMonitoringFBD_Miko: id 0x11A, frame-length=8, can-addressing-mode=STANDARD, can-frame-rx-behavior=CAN-20, can-frame-tx-behavior=CAN-20
        pdu StatusBLEConMonitoringFBD_Miko: length=8, unused-bit-pattern=0
          signal StatusBLEConMonitoringFBD_Miko_IRKListID: start 0, 8 bit, little-endian, data-type-policy=OVERRIDE, base-type=uint8, compu {phys=raw}, range phys 0..252
          signal StatusBLEConMonitoringFBD_Miko_MonitoringActivation: start 8, 8 bit, little-endian, data-type-policy=OVERRIDE, compu {phys=raw}
          signal StatusBLEConMonitoringFBD_Miko_BusCycleTime: start 16, 8 bit, little-endian, data-type-policy=OVERRIDE, base-type=uint8, compu {phys=raw*10; unit ms}, range phys 0..252
          signal StatusBLEConMonitoringFBD_Miko_BLENodes: start 24, 16 bit, little-endian, data-type-policy=OVERRIDE, compu {phys=raw}
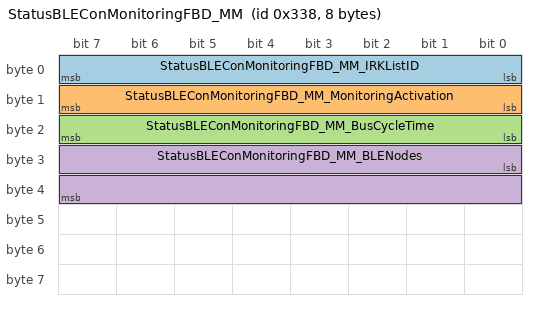
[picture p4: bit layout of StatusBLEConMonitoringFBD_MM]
      frame StatusBLEConMonitoringFBD_MM: id 0x338, frame-length=8, can-addressing-mode=STANDARD, can-frame-rx-behavior=CAN-20, can-frame-tx-behavior=CAN-20
        pdu StatusBLEConMonitoringFBD_MM: length=8, unused-bit-pattern=0
          signal StatusBLEConMonitoringFBD_MM_IRKListID: start 0, 8 bit, little-endian, data-type-policy=OVERRIDE, base-type=uint8, compu {phys=raw}, range phys 0..252
          signal StatusBLEConMonitoringFBD_MM_MonitoringActivation: start 8, 8 bit, little-endian, data-type-policy=OVERRIDE, compu {phys=raw}
          signal StatusBLEConMonitoringFBD_MM_BusCycleTime: start 16, 8 bit, little-endian, data-type-policy=OVERRIDE, base-type=uint8, compu {phys=raw*10; unit ms}, range phys 0..252
          signal StatusBLEConMonitoringFBD_MM_BLENodes: start 24, 16 bit, little-endian, data-type-policy=OVERRIDE, compu {phys=raw}
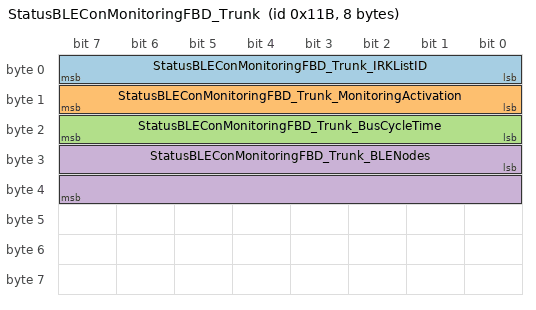
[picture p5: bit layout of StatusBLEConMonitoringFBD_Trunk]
      frame StatusBLEConMonitoringFBD_Trunk: id 0x11B, frame-length=8, can-addressing-mode=STANDARD, can-frame-rx-behavior=CAN-20, can-frame-tx-behavior=CAN-20
        pdu StatusBLEConMonitoringFBD_Trunk: length=8, unused-bit-pattern=0
          signal StatusBLEConMonitoringFBD_Trunk_IRKListID: start 0, 8 bit, little-endian, data-type-policy=OVERRIDE, base-type=uint8, compu {phys=raw}, range phys 0..252
          signal StatusBLEConMonitoringFBD_Trunk_MonitoringActivation: start 8, 8 bit, little-endian, data-type-policy=OVERRIDE, compu {phys=raw}
          signal StatusBLEConMonitoringFBD_Trunk_BusCycleTime: start 16, 8 bit, little-endian, data-type-policy=OVERRIDE, base-type=uint8, compu {phys=raw*10; unit ms}, range phys 0..252
          signal StatusBLEConMonitoringFBD_Trunk_BLENodes: start 24, 16 bit, little-endian, data-type-policy=OVERRIDE, compu {phys=raw}
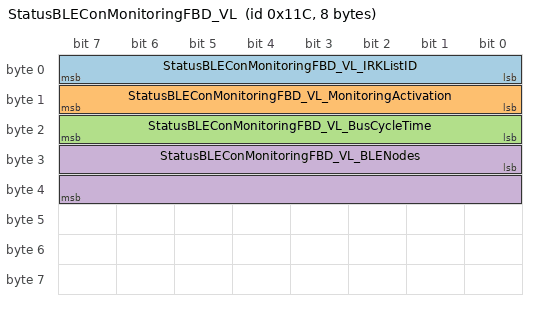
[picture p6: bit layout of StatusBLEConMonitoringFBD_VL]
      frame StatusBLEConMonitoringFBD_VL: id 0x11C, frame-length=8, can-addressing-mode=STANDARD, can-frame-rx-behavior=CAN-20, can-frame-tx-behavior=CAN-20
        pdu StatusBLEConMonitoringFBD_VL: length=8, unused-bit-pattern=0
          signal StatusBLEConMonitoringFBD_VL_IRKListID: start 0, 8 bit, little-endian, data-type-policy=OVERRIDE, base-type=uint8, compu {phys=raw}, range phys 0..252
          signal StatusBLEConMonitoringFBD_VL_MonitoringActivation: start 8, 8 bit, little-endian, data-type-policy=OVERRIDE, compu {phys=raw}
          signal StatusBLEConMonitoringFBD_VL_BusCycleTime: start 16, 8 bit, little-endian, data-type-policy=OVERRIDE, base-type=uint8, compu {phys=raw*10; unit ms}, range phys 0..252
          signal StatusBLEConMonitoringFBD_VL_BLENodes: start 24, 16 bit, little-endian, data-type-policy=OVERRIDE, compu {phys=raw}
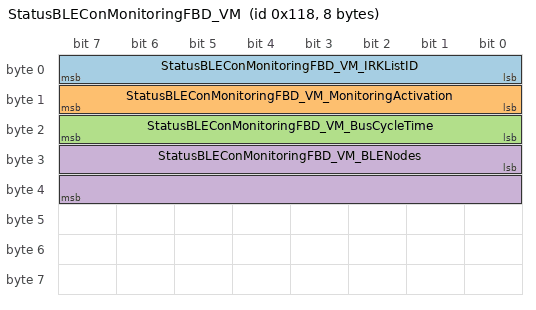
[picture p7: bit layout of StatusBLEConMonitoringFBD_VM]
      frame StatusBLEConMonitoringFBD_VM: id 0x118, frame-length=8, can-addressing-mode=STANDARD, can-frame-rx-behavior=CAN-20, can-frame-tx-behavior=CAN-20
        pdu StatusBLEConMonitoringFBD_VM: length=8, unused-bit-pattern=0
          signal StatusBLEConMonitoringFBD_VM_IRKListID: start 0, 8 bit, little-endian, data-type-policy=OVERRIDE, base-type=uint8, compu {phys=raw}, range phys 0..252
          signal StatusBLEConMonitoringFBD_VM_MonitoringActivation: start 8, 8 bit, little-endian, data-type-policy=OVERRIDE, compu {phys=raw}
          signal StatusBLEConMonitoringFBD_VM_BusCycleTime: start 16, 8 bit, little-endian, data-type-policy=OVERRIDE, base-type=uint8, compu {phys=raw*10; unit ms}, range phys 0..252
          signal StatusBLEConMonitoringFBD_VM_BLENodes: start 24, 16 bit, little-endian, data-type-policy=OVERRIDE, compu {phys=raw}
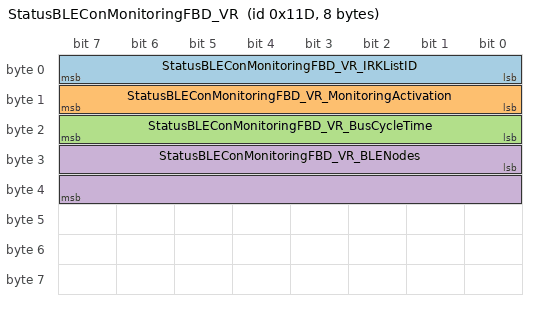
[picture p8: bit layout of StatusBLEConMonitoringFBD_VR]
      frame StatusBLEConMonitoringFBD_VR: id 0x11D, frame-length=8, can-addressing-mode=STANDARD, can-frame-rx-behavior=CAN-20, can-frame-tx-behavior=CAN-20
        pdu StatusBLEConMonitoringFBD_VR: length=8, unused-bit-pattern=0
          signal StatusBLEConMonitoringFBD_VR_IRKListID: start 0, 8 bit, little-endian, data-type-policy=OVERRIDE, base-type=uint8, compu {phys=raw}, range phys 0..252
          signal StatusBLEConMonitoringFBD_VR_MonitoringActivation: start 8, 8 bit, little-endian, data-type-policy=OVERRIDE, compu {phys=raw}
          signal StatusBLEConMonitoringFBD_VR_BusCycleTime: start 16, 8 bit, little-endian, data-type-policy=OVERRIDE, base-type=uint8, compu {phys=raw*10; unit ms}, range phys 0..252
          signal StatusBLEConMonitoringFBD_VR_BLENodes: start 24, 16 bit, little-endian, data-type-policy=OVERRIDE, compu {phys=raw}
      frame StatusBLECSFBD_HL: id 0x178, frame-length=16, can-addressing-mode=STANDARD, can-frame-rx-behavior=CAN-FD, can-frame-tx-behavior=CAN-FD
        pdu StatusBLECSFBD_HL: length=16, unused-bit-pattern=0
          signal StatusBLECSFBD_HL_SessionID: start 0, 8 bit, little-endian, data-type-policy=OVERRIDE, base-type=uint8, compu {phys=raw}, range phys 0..252
          signal StatusBLECSFBD_HL_IRKListID: start 8, 8 bit, little-endian, data-type-policy=OVERRIDE, base-type=uint8, compu {phys=raw}, range phys 0..252
          signal StatusBLECSFBD_HL_DeviceGroup: start 16, 8 bit, little-endian, data-type-policy=OVERRIDE, base-type=uint8, compu {phys=raw}, range phys 0..252
          signal StatusBLECSFBD_HL_Algorithm: start 24, 8 bit, little-endian, data-type-policy=OVERRIDE, compu {phys=raw}
          signal StatusBLECSFBD_HL_DistanceOffset: start 32, 16 bit, little-endian, data-type-policy=OVERRIDE, base-type=uint16, compu {phys=raw}, range phys 0..65532
          signal StatusBLECSFBD_HL_AntennaConfig: start 48, 8 bit, little-endian, data-type-policy=OVERRIDE, compu {phys=raw}
          signal StatusBLECSFBD_HL_TxPower: start 56, 8 bit, little-endian, data-type-policy=OVERRIDE, base-type=uint8, compu {phys=raw}, range phys 0..252
          signal StatusBLECSFBD_HL_Role: start 64, 8 bit, little-endian, data-type-policy=OVERRIDE, compu {phys=raw}
          signal StatusBLECSFBD_HL_ProcedureResultsTransfer: start 72, 8 bit, little-endian, data-type-policy=OVERRIDE, compu {phys=raw}
          signal StatusBLECSFBD_HL_AntennaPathProcedureResults: start 80, 8 bit, little-endian, data-type-policy=OVERRIDE, compu {phys=raw}
          signal StatusBLECSFBD_HL_FBDonlyThreshold: start 88, 8 bit, little-endian, data-type-policy=OVERRIDE, base-type=uint8, compu {phys=raw}, range phys 0..252
          signal StatusBLECSFBD_HL_InlinePCT: start 96, 8 bit, little-endian, data-type-policy=OVERRIDE, compu {phys=raw}
      frame StatusBLECSFBD_HM: id 0x173, frame-length=16, can-addressing-mode=STANDARD, can-frame-rx-behavior=CAN-FD, can-frame-tx-behavior=CAN-FD
        pdu StatusBLECSFBD_HM: length=16, unused-bit-pattern=0
          signal StatusBLECSFBD_HM_SessionID: start 0, 8 bit, little-endian, data-type-policy=OVERRIDE, base-type=uint8, compu {phys=raw}, range phys 0..252
          signal StatusBLECSFBD_HM_IRKListID: start 8, 8 bit, little-endian, data-type-policy=OVERRIDE, base-type=uint8, compu {phys=raw}, range phys 0..252
          signal StatusBLECSFBD_HM_DeviceGroup: start 16, 8 bit, little-endian, data-type-policy=OVERRIDE, base-type=uint8, compu {phys=raw}, range phys 0..252
          signal StatusBLECSFBD_HM_Algorithm: start 24, 8 bit, little-endian, data-type-policy=OVERRIDE, compu {phys=raw}
          signal StatusBLECSFBD_HM_DistanceOffset: start 32, 16 bit, little-endian, data-type-policy=OVERRIDE, base-type=uint16, compu {phys=raw}, range phys 0..65532
          signal StatusBLECSFBD_HM_AntennaConfig: start 48, 8 bit, little-endian, data-type-policy=OVERRIDE, compu {phys=raw}
          signal StatusBLECSFBD_HM_TxPower: start 56, 8 bit, little-endian, data-type-policy=OVERRIDE, base-type=uint8, compu {phys=raw}, range phys 0..252
          signal StatusBLECSFBD_HM_Role: start 64, 8 bit, little-endian, data-type-policy=OVERRIDE, compu {phys=raw}
          signal StatusBLECSFBD_HM_ProcedureResultsTransfer: start 72, 8 bit, little-endian, data-type-policy=OVERRIDE, compu {phys=raw}
          signal StatusBLECSFBD_HM_AntennaPathProcedureResults: start 80, 8 bit, little-endian, data-type-policy=OVERRIDE, compu {phys=raw}
          signal StatusBLECSFBD_HM_FBDonlyThreshold: start 88, 8 bit, little-endian, data-type-policy=OVERRIDE, base-type=uint8, compu {phys=raw}, range phys 0..252
          signal StatusBLECSFBD_HM_InlinePCT: start 96, 8 bit, little-endian, data-type-policy=OVERRIDE, compu {phys=raw}
      frame StatusBLECSFBD_HR: id 0x179, frame-length=16, can-addressing-mode=STANDARD, can-frame-rx-behavior=CAN-FD, can-frame-tx-behavior=CAN-FD
        pdu StatusBLECSFBD_HR: length=16, unused-bit-pattern=0
          signal StatusBLECSFBD_HR_SessionID: start 0, 8 bit, little-endian, data-type-policy=OVERRIDE, base-type=uint8, compu {phys=raw}, range phys 0..252
          signal StatusBLECSFBD_HR_IRKListID: start 8, 8 bit, little-endian, data-type-policy=OVERRIDE, base-type=uint8, compu {phys=raw}, range phys 0..252
          signal StatusBLECSFBD_HR_DeviceGroup: start 16, 8 bit, little-endian, data-type-policy=OVERRIDE, base-type=uint8, compu {phys=raw}, range phys 0..252
          signal StatusBLECSFBD_HR_Algorithm: start 24, 8 bit, little-endian, data-type-policy=OVERRIDE, compu {phys=raw}
          signal StatusBLECSFBD_HR_DistanceOffset: start 32, 16 bit, little-endian, data-type-policy=OVERRIDE, base-type=uint16, compu {phys=raw}, range phys 0..65532
          signal StatusBLECSFBD_HR_AntennaConfig: start 48, 8 bit, little-endian, data-type-policy=OVERRIDE, compu {phys=raw}
          signal StatusBLECSFBD_HR_TxPower: start 56, 8 bit, little-endian, data-type-policy=OVERRIDE, base-type=uint8, compu {phys=raw}, range phys 0..252
          signal StatusBLECSFBD_HR_Role: start 64, 8 bit, little-endian, data-type-policy=OVERRIDE, compu {phys=raw}
          signal StatusBLECSFBD_HR_ProcedureResultsTransfer: start 72, 8 bit, little-endian, data-type-policy=OVERRIDE, compu {phys=raw}
          signal StatusBLECSFBD_HR_AntennaPathProcedureResults: start 80, 8 bit, little-endian, data-type-policy=OVERRIDE, compu {phys=raw}
          signal StatusBLECSFBD_HR_FBDonlyThreshold: start 88, 8 bit, little-endian, data-type-policy=OVERRIDE, base-type=uint8, compu {phys=raw}, range phys 0..252
          signal StatusBLECSFBD_HR_InlinePCT: start 96, 8 bit, little-endian, data-type-policy=OVERRIDE, compu {phys=raw}
      frame StatusBLECSFBD_Miko: id 0x174, frame-length=16, can-addressing-mode=STANDARD, can-frame-rx-behavior=CAN-FD, can-frame-tx-behavior=CAN-FD
        pdu StatusBLECSFBD_Miko: length=16, unused-bit-pattern=0
          signal StatusBLECSFBD_Miko_SessionID: start 0, 8 bit, little-endian, data-type-policy=OVERRIDE, base-type=uint8, compu {phys=raw}, range phys 0..252
          signal StatusBLECSFBD_Miko_IRKListID: start 8, 8 bit, little-endian, data-type-policy=OVERRIDE, base-type=uint8, compu {phys=raw}, range phys 0..252
          signal StatusBLECSFBD_Miko_DeviceGroup: start 16, 8 bit, little-endian, data-type-policy=OVERRIDE, base-type=uint8, compu {phys=raw}, range phys 0..252
          signal StatusBLECSFBD_Miko_Algorithm: start 24, 8 bit, little-endian, data-type-policy=OVERRIDE, compu {phys=raw}
          signal StatusBLECSFBD_Miko_DistanceOffset: start 32, 16 bit, little-endian, data-type-policy=OVERRIDE, base-type=uint16, compu {phys=raw}, range phys 0..65532
          signal StatusBLECSFBD_Miko_AntennaConfig: start 48, 8 bit, little-endian, data-type-policy=OVERRIDE, compu {phys=raw}
          signal StatusBLECSFBD_Miko_TxPower: start 56, 8 bit, little-endian, data-type-policy=OVERRIDE, base-type=uint8, compu {phys=raw}, range phys 0..252
          signal StatusBLECSFBD_Miko_Role: start 64, 8 bit, little-endian, data-type-policy=OVERRIDE, compu {phys=raw}
          signal StatusBLECSFBD_Miko_ProcedureResultsTransfer: start 72, 8 bit, little-endian, data-type-policy=OVERRIDE, compu {phys=raw}
          signal StatusBLECSFBD_Miko_AntennaPathProcedureResults: start 80, 8 bit, little-endian, data-type-policy=OVERRIDE, compu {phys=raw}
          signal StatusBLECSFBD_Miko_FBDonlyThreshold: start 88, 8 bit, little-endian, data-type-policy=OVERRIDE, base-type=uint8, compu {phys=raw}, range phys 0..252
          signal StatusBLECSFBD_Miko_InlinePCT: start 96, 8 bit, little-endian, data-type-policy=OVERRIDE, compu {phys=raw}
      frame StatusBLECSFBD_MM: id 0x17C, frame-length=16, can-addressing-mode=STANDARD, can-frame-rx-behavior=CAN-FD, can-frame-tx-behavior=CAN-FD
        pdu StatusBLECSFBD_MM: length=16, unused-bit-pattern=0
          signal StatusBLECSFBD_MM_SessionID: start 0, 8 bit, little-endian, data-type-policy=OVERRIDE, base-type=uint8, compu {phys=raw}, range phys 0..252
          signal StatusBLECSFBD_MM_IRKListID: start 8, 8 bit, little-endian, data-type-policy=OVERRIDE, base-type=uint8, compu {phys=raw}, range phys 0..252
          signal StatusBLECSFBD_MM_DeviceGroup: start 16, 8 bit, little-endian, data-type-policy=OVERRIDE, base-type=uint8, compu {phys=raw}, range phys 0..252
          signal StatusBLECSFBD_MM_Algorithm: start 24, 8 bit, little-endian, data-type-policy=OVERRIDE, compu {phys=raw}
          signal StatusBLECSFBD_MM_DistanceOffset: start 32, 16 bit, little-endian, data-type-policy=OVERRIDE, base-type=uint16, compu {phys=raw}, range phys 0..65532
          signal StatusBLECSFBD_MM_AntennaConfig: start 48, 8 bit, little-endian, data-type-policy=OVERRIDE, compu {phys=raw}
          signal StatusBLECSFBD_MM_TxPower: start 56, 8 bit, little-endian, data-type-policy=OVERRIDE, base-type=uint8, compu {phys=raw}, range phys 0..252
          signal StatusBLECSFBD_MM_Role: start 64, 8 bit, little-endian, data-type-policy=OVERRIDE, compu {phys=raw}
          signal StatusBLECSFBD_MM_ProcedureResultsTransfer: start 72, 8 bit, little-endian, data-type-policy=OVERRIDE, compu {phys=raw}
          signal StatusBLECSFBD_MM_AntennaPathProcedureResults: start 80, 8 bit, little-endian, data-type-policy=OVERRIDE, compu {phys=raw}
          signal StatusBLECSFBD_MM_FBDonlyThreshold: start 88, 8 bit, little-endian, data-type-policy=OVERRIDE, base-type=uint8, compu {phys=raw}, range phys 0..252
          signal StatusBLECSFBD_MM_InlinePCT: start 96, 8 bit, little-endian, data-type-policy=OVERRIDE, compu {phys=raw}
      frame StatusBLECSFBD_Trunk: id 0x175, frame-length=16, can-addressing-mode=STANDARD, can-frame-rx-behavior=CAN-FD, can-frame-tx-behavior=CAN-FD
        pdu StatusBLECSFBD_Trunk: length=16, unused-bit-pattern=0
          signal StatusBLECSFBD_Trunk_SessionID: start 0, 8 bit, little-endian, data-type-policy=OVERRIDE, base-type=uint8, compu {phys=raw}, range phys 0..252
          signal StatusBLECSFBD_Trunk_IRKListID: start 8, 8 bit, little-endian, data-type-policy=OVERRIDE, base-type=uint8, compu {phys=raw}, range phys 0..252
          signal StatusBLECSFBD_Trunk_DeviceGroup: start 16, 8 bit, little-endian, data-type-policy=OVERRIDE, base-type=uint8, compu {phys=raw}, range phys 0..252
          signal StatusBLECSFBD_Trunk_Algorithm: start 24, 8 bit, little-endian, data-type-policy=OVERRIDE, compu {phys=raw}
          signal StatusBLECSFBD_Trunk_DistanceOffset: start 32, 16 bit, little-endian, data-type-policy=OVERRIDE, base-type=uint16, compu {phys=raw}, range phys 0..65532
          signal StatusBLECSFBD_Trunk_AntennaConfig: start 48, 8 bit, little-endian, data-type-policy=OVERRIDE, compu {phys=raw}
          signal StatusBLECSFBD_Trunk_TxPower: start 56, 8 bit, little-endian, data-type-policy=OVERRIDE, base-type=uint8, compu {phys=raw}, range phys 0..252
          signal StatusBLECSFBD_Trunk_Role: start 64, 8 bit, little-endian, data-type-policy=OVERRIDE, compu {phys=raw}
          signal StatusBLECSFBD_Trunk_ProcedureResultsTransfer: start 72, 8 bit, little-endian, data-type-policy=OVERRIDE, compu {phys=raw}
          signal StatusBLECSFBD_Trunk_AntennaPathProcedureResults: start 80, 8 bit, little-endian, data-type-policy=OVERRIDE, compu {phys=raw}
          signal StatusBLECSFBD_Trunk_FBDonlyThreshold: start 88, 8 bit, little-endian, data-type-policy=OVERRIDE, base-type=uint8, compu {phys=raw}, range phys 0..252
          signal StatusBLECSFBD_Trunk_InlinePCT: start 96, 8 bit, little-endian, data-type-policy=OVERRIDE, compu {phys=raw}
      frame StatusBLECSFBD_VL: id 0x176, frame-length=16, can-addressing-mode=STANDARD, can-frame-rx-behavior=CAN-FD, can-frame-tx-behavior=CAN-FD
        pdu StatusBLECSFBD_VL: length=16, unused-bit-pattern=0
          signal StatusBLECSFBD_VL_SessionID: start 0, 8 bit, little-endian, data-type-policy=OVERRIDE, base-type=uint8, compu {phys=raw}, range phys 0..252
          signal StatusBLECSFBD_VL_IRKListID: start 8, 8 bit, little-endian, data-type-policy=OVERRIDE, base-type=uint8, compu {phys=raw}, range phys 0..252
          signal StatusBLECSFBD_VL_DeviceGroup: start 16, 8 bit, little-endian, data-type-policy=OVERRIDE, base-type=uint8, compu {phys=raw}, range phys 0..252
          signal StatusBLECSFBD_VL_Algorithm: start 24, 8 bit, little-endian, data-type-policy=OVERRIDE, compu {phys=raw}
          signal StatusBLECSFBD_VL_DistanceOffset: start 32, 16 bit, little-endian, data-type-policy=OVERRIDE, base-type=uint16, compu {phys=raw}, range phys 0..65532
          signal StatusBLECSFBD_VL_AntennaConfig: start 48, 8 bit, little-endian, data-type-policy=OVERRIDE, compu {phys=raw}
          signal StatusBLECSFBD_VL_TxPower: start 56, 8 bit, little-endian, data-type-policy=OVERRIDE, base-type=uint8, compu {phys=raw}, range phys 0..252
          signal StatusBLECSFBD_VL_Role: start 64, 8 bit, little-endian, data-type-policy=OVERRIDE, compu {phys=raw}
          signal StatusBLECSFBD_VL_ProcedureResultsTransfer: start 72, 8 bit, little-endian, data-type-policy=OVERRIDE, compu {phys=raw}
          signal StatusBLECSFBD_VL_AntennaPathProcedureResults: start 80, 8 bit, little-endian, data-type-policy=OVERRIDE, compu {phys=raw}
          signal StatusBLECSFBD_VL_FBDonlyThreshold: start 88, 8 bit, little-endian, data-type-policy=OVERRIDE, base-type=uint8, compu {phys=raw}, range phys 0..252
          signal StatusBLECSFBD_VL_InlinePCT: start 96, 8 bit, little-endian, data-type-policy=OVERRIDE, compu {phys=raw}
      frame StatusBLECSFBD_VM: id 0x172, frame-length=16, can-addressing-mode=STANDARD, can-frame-rx-behavior=CAN-FD, can-frame-tx-behavior=CAN-FD
        pdu StatusBLECSFBD_VM: length=16, unused-bit-pattern=0
          signal StatusBLECSFBD_VM_SessionID: start 0, 8 bit, little-endian, data-type-policy=OVERRIDE, base-type=uint8, compu {phys=raw}, range phys 0..252
          signal StatusBLECSFBD_VM_IRKListID: start 8, 8 bit, little-endian, data-type-policy=OVERRIDE, base-type=uint8, compu {phys=raw}, range phys 0..252
          signal StatusBLECSFBD_VM_DeviceGroup: start 16, 8 bit, little-endian, data-type-policy=OVERRIDE, base-type=uint8, compu {phys=raw}, range phys 0..252
          signal StatusBLECSFBD_VM_Algorithm: start 24, 8 bit, little-endian, data-type-policy=OVERRIDE, compu {phys=raw}
          signal StatusBLECSFBD_VM_DistanceOffset: start 32, 16 bit, little-endian, data-type-policy=OVERRIDE, base-type=uint16, compu {phys=raw}, range phys 0..65532
          signal StatusBLECSFBD_VM_AntennaConfig: start 48, 8 bit, little-endian, data-type-policy=OVERRIDE, compu {phys=raw}
          signal StatusBLECSFBD_VM_TxPower: start 56, 8 bit, little-endian, data-type-policy=OVERRIDE, base-type=uint8, compu {phys=raw}, range phys 0..252
          signal StatusBLECSFBD_VM_Role: start 64, 8 bit, little-endian, data-type-policy=OVERRIDE, compu {phys=raw}
          signal StatusBLECSFBD_VM_ProcedureResultsTransfer: start 72, 8 bit, little-endian, data-type-policy=OVERRIDE, compu {phys=raw}
          signal StatusBLECSFBD_VM_AntennaPathProcedureResults: start 80, 8 bit, little-endian, data-type-policy=OVERRIDE, compu {phys=raw}
          signal StatusBLECSFBD_VM_FBDonlyThreshold: start 88, 8 bit, little-endian, data-type-policy=OVERRIDE, base-type=uint8, compu {phys=raw}, range phys 0..252
          signal StatusBLECSFBD_VM_InlinePCT: start 96, 8 bit, little-endian, data-type-policy=OVERRIDE, compu {phys=raw}
      frame StatusBLECSFBD_VR: id 0x177, frame-length=16, can-addressing-mode=STANDARD, can-frame-rx-behavior=CAN-FD, can-frame-tx-behavior=CAN-FD
        pdu StatusBLECSFBD_VR: length=16, unused-bit-pattern=0
          signal StatusBLECSFBD_VR_SessionID: start 0, 8 bit, little-endian, data-type-policy=OVERRIDE, base-type=uint8, compu {phys=raw}, range phys 0..252
          signal StatusBLECSFBD_VR_IRKListID: start 8, 8 bit, little-endian, data-type-policy=OVERRIDE, base-type=uint8, compu {phys=raw}, range phys 0..252
          signal StatusBLECSFBD_VR_DeviceGroup: start 16, 8 bit, little-endian, data-type-policy=OVERRIDE, base-type=uint8, compu {phys=raw}, range phys 0..252
          signal StatusBLECSFBD_VR_Algorithm: start 24, 8 bit, little-endian, data-type-policy=OVERRIDE, compu {phys=raw}
          signal StatusBLECSFBD_VR_DistanceOffset: start 32, 16 bit, little-endian, data-type-policy=OVERRIDE, base-type=uint16, compu {phys=raw}, range phys 0..65532
          signal StatusBLECSFBD_VR_AntennaConfig: start 48, 8 bit, little-endian, data-type-policy=OVERRIDE, compu {phys=raw}
          signal StatusBLECSFBD_VR_TxPower: start 56, 8 bit, little-endian, data-type-policy=OVERRIDE, base-type=uint8, compu {phys=raw}, range phys 0..252
          signal StatusBLECSFBD_VR_Role: start 64, 8 bit, little-endian, data-type-policy=OVERRIDE, compu {phys=raw}
          signal StatusBLECSFBD_VR_ProcedureResultsTransfer: start 72, 8 bit, little-endian, data-type-policy=OVERRIDE, compu {phys=raw}
          signal StatusBLECSFBD_VR_AntennaPathProcedureResults: start 80, 8 bit, little-endian, data-type-policy=OVERRIDE, compu {phys=raw}
          signal StatusBLECSFBD_VR_FBDonlyThreshold: start 88, 8 bit, little-endian, data-type-policy=OVERRIDE, base-type=uint8, compu {phys=raw}, range phys 0..252
          signal StatusBLECSFBD_VR_InlinePCT: start 96, 8 bit, little-endian, data-type-policy=OVERRIDE, compu {phys=raw}
      frame StatusBLEDeviceNameFBD_HL: id 0x290, frame-length=32, can-addressing-mode=STANDARD, can-frame-rx-behavior=CAN-FD, can-frame-tx-behavior=CAN-FD
        pdu StatusBLEDeviceNameFBD_HL: length=32, unused-bit-pattern=0
          signal StatusBLEDeviceNameFBD_HL_Character00: start 0, 8 bit, little-endian, data-type-policy=OVERRIDE, base-type=uint8, compu {phys=raw}, range phys 0..252
          signal StatusBLEDeviceNameFBD_HL_Character01: start 8, 8 bit, little-endian, data-type-policy=OVERRIDE, base-type=uint8, compu {phys=raw}, range phys 0..252
          signal StatusBLEDeviceNameFBD_HL_Character02: start 16, 8 bit, little-endian, data-type-policy=OVERRIDE, base-type=uint8, compu {phys=raw}, range phys 0..252
          signal StatusBLEDeviceNameFBD_HL_Character03: start 24, 8 bit, little-endian, data-type-policy=OVERRIDE, base-type=uint8, compu {phys=raw}, range phys 0..252
          signal StatusBLEDeviceNameFBD_HL_Character04: start 32, 8 bit, little-endian, data-type-policy=OVERRIDE, base-type=uint8, compu {phys=raw}, range phys 0..252
          signal StatusBLEDeviceNameFBD_HL_Character05: start 40, 8 bit, little-endian, data-type-policy=OVERRIDE, base-type=uint8, compu {phys=raw}, range phys 0..252
          signal StatusBLEDeviceNameFBD_HL_Character06: start 48, 8 bit, little-endian, data-type-policy=OVERRIDE, base-type=uint8, compu {phys=raw}, range phys 0..252
          signal StatusBLEDeviceNameFBD_HL_Character07: start 56, 8 bit, little-endian, data-type-policy=OVERRIDE, base-type=uint8, compu {phys=raw}, range phys 0..252
          signal StatusBLEDeviceNameFBD_HL_Character08: start 64, 8 bit, little-endian, data-type-policy=OVERRIDE, base-type=uint8, compu {phys=raw}, range phys 0..252
          signal StatusBLEDeviceNameFBD_HL_Character09: start 72, 8 bit, little-endian, data-type-policy=OVERRIDE, base-type=uint8, compu {phys=raw}, range phys 0..252
          signal StatusBLEDeviceNameFBD_HL_Character10: start 80, 8 bit, little-endian, data-type-policy=OVERRIDE, base-type=uint8, compu {phys=raw}, range phys 0..252
          signal StatusBLEDeviceNameFBD_HL_Character11: start 88, 8 bit, little-endian, data-type-policy=OVERRIDE, base-type=uint8, compu {phys=raw}, range phys 0..252
          signal StatusBLEDeviceNameFBD_HL_Character12: start 96, 8 bit, little-endian, data-type-policy=OVERRIDE, base-type=uint8, compu {phys=raw}, range phys 0..252
          signal StatusBLEDeviceNameFBD_HL_Character13: start 104, 8 bit, little-endian, data-type-policy=OVERRIDE, base-type=uint8, compu {phys=raw}, range phys 0..252
          signal StatusBLEDeviceNameFBD_HL_Character14: start 112, 8 bit, little-endian, data-type-policy=OVERRIDE, base-type=uint8, compu {phys=raw}, range phys 0..252
          signal StatusBLEDeviceNameFBD_HL_Character15: start 120, 8 bit, little-endian, data-type-policy=OVERRIDE, base-type=uint8, compu {phys=raw}, range phys 0..252
          signal StatusBLEDeviceNameFBD_HL_Character16: start 128, 8 bit, little-endian, data-type-policy=OVERRIDE, base-type=uint8, compu {phys=raw}, range phys 0..252
          signal StatusBLEDeviceNameFBD_HL_Character17: start 136, 8 bit, little-endian, data-type-policy=OVERRIDE, base-type=uint8, compu {phys=raw}, range phys 0..252
          signal StatusBLEDeviceNameFBD_HL_Character18: start 144, 8 bit, little-endian, data-type-policy=OVERRIDE, base-type=uint8, compu {phys=raw}, range phys 0..252
          signal StatusBLEDeviceNameFBD_HL_Character19: start 152, 8 bit, little-endian, data-type-policy=OVERRIDE, base-type=uint8, compu {phys=raw}, range phys 0..252
          signal StatusBLEDeviceNameFBD_HL_Character20: start 160, 8 bit, little-endian, data-type-policy=OVERRIDE, base-type=uint8, compu {phys=raw}, range phys 0..252
          signal StatusBLEDeviceNameFBD_HL_Character21: start 168, 8 bit, little-endian, data-type-policy=OVERRIDE, base-type=uint8, compu {phys=raw}, range phys 0..252
          signal StatusBLEDeviceNameFBD_HL_Character22: start 176, 8 bit, little-endian, data-type-policy=OVERRIDE, base-type=uint8, compu {phys=raw}, range phys 0..252
          signal StatusBLEDeviceNameFBD_HL_Character23: start 184, 8 bit, little-endian, data-type-policy=OVERRIDE, base-type=uint8, compu {phys=raw}, range phys 0..252
          signal StatusBLEDeviceNameFBD_HL_Character24: start 192, 8 bit, little-endian, data-type-policy=OVERRIDE, base-type=uint8, compu {phys=raw}, range phys 0..252
          signal StatusBLEDeviceNameFBD_HL_Character25: start 200, 8 bit, little-endian, data-type-policy=OVERRIDE, base-type=uint8, compu {phys=raw}, range phys 0..252
          signal StatusBLEDeviceNameFBD_HL_Character26: start 208, 8 bit, little-endian, data-type-policy=OVERRIDE, base-type=uint8, compu {phys=raw}, range phys 0..252
          signal StatusBLEDeviceNameFBD_HL_Character27: start 216, 8 bit, little-endian, data-type-policy=OVERRIDE, base-type=uint8, compu {phys=raw}, range phys 0..252
          signal StatusBLEDeviceNameFBD_HL_Character28: start 224, 8 bit, little-endian, data-type-policy=OVERRIDE, base-type=uint8, compu {phys=raw}, range phys 0..252
          signal StatusBLEDeviceNameFBD_HL_Character29: start 232, 8 bit, little-endian, data-type-policy=OVERRIDE, base-type=uint8, compu {phys=raw}, range phys 0..252
      frame StatusBLEDeviceNameFBD_HM: id 0x28B, frame-length=32, can-addressing-mode=STANDARD, can-frame-rx-behavior=CAN-FD, can-frame-tx-behavior=CAN-FD
        pdu StatusBLEDeviceNameFBD_HM: length=32, unused-bit-pattern=0
          signal StatusBLEDeviceNameFBD_HM_Character00: start 0, 8 bit, little-endian, data-type-policy=OVERRIDE, base-type=uint8, compu {phys=raw}, range phys 0..252
          signal StatusBLEDeviceNameFBD_HM_Character01: start 8, 8 bit, little-endian, data-type-policy=OVERRIDE, base-type=uint8, compu {phys=raw}, range phys 0..252
          signal StatusBLEDeviceNameFBD_HM_Character02: start 16, 8 bit, little-endian, data-type-policy=OVERRIDE, base-type=uint8, compu {phys=raw}, range phys 0..252
          signal StatusBLEDeviceNameFBD_HM_Character03: start 24, 8 bit, little-endian, data-type-policy=OVERRIDE, base-type=uint8, compu {phys=raw}, range phys 0..252
          signal StatusBLEDeviceNameFBD_HM_Character04: start 32, 8 bit, little-endian, data-type-policy=OVERRIDE, base-type=uint8, compu {phys=raw}, range phys 0..252
          signal StatusBLEDeviceNameFBD_HM_Character05: start 40, 8 bit, little-endian, data-type-policy=OVERRIDE, base-type=uint8, compu {phys=raw}, range phys 0..252
          signal StatusBLEDeviceNameFBD_HM_Character06: start 48, 8 bit, little-endian, data-type-policy=OVERRIDE, base-type=uint8, compu {phys=raw}, range phys 0..252
          signal StatusBLEDeviceNameFBD_HM_Character07: start 56, 8 bit, little-endian, data-type-policy=OVERRIDE, base-type=uint8, compu {phys=raw}, range phys 0..252
          signal StatusBLEDeviceNameFBD_HM_Character08: start 64, 8 bit, little-endian, data-type-policy=OVERRIDE, base-type=uint8, compu {phys=raw}, range phys 0..252
          signal StatusBLEDeviceNameFBD_HM_Character09: start 72, 8 bit, little-endian, data-type-policy=OVERRIDE, base-type=uint8, compu {phys=raw}, range phys 0..252
          signal StatusBLEDeviceNameFBD_HM_Character10: start 80, 8 bit, little-endian, data-type-policy=OVERRIDE, base-type=uint8, compu {phys=raw}, range phys 0..252
          signal StatusBLEDeviceNameFBD_HM_Character11: start 88, 8 bit, little-endian, data-type-policy=OVERRIDE, base-type=uint8, compu {phys=raw}, range phys 0..252
          signal StatusBLEDeviceNameFBD_HM_Character12: start 96, 8 bit, little-endian, data-type-policy=OVERRIDE, base-type=uint8, compu {phys=raw}, range phys 0..252
          signal StatusBLEDeviceNameFBD_HM_Character13: start 104, 8 bit, little-endian, data-type-policy=OVERRIDE, base-type=uint8, compu {phys=raw}, range phys 0..252
          signal StatusBLEDeviceNameFBD_HM_Character14: start 112, 8 bit, little-endian, data-type-policy=OVERRIDE, base-type=uint8, compu {phys=raw}, range phys 0..252
          signal StatusBLEDeviceNameFBD_HM_Character15: start 120, 8 bit, little-endian, data-type-policy=OVERRIDE, base-type=uint8, compu {phys=raw}, range phys 0..252
          signal StatusBLEDeviceNameFBD_HM_Character16: start 128, 8 bit, little-endian, data-type-policy=OVERRIDE, base-type=uint8, compu {phys=raw}, range phys 0..252
          signal StatusBLEDeviceNameFBD_HM_Character17: start 136, 8 bit, little-endian, data-type-policy=OVERRIDE, base-type=uint8, compu {phys=raw}, range phys 0..252
          signal StatusBLEDeviceNameFBD_HM_Character18: start 144, 8 bit, little-endian, data-type-policy=OVERRIDE, base-type=uint8, compu {phys=raw}, range phys 0..252
          signal StatusBLEDeviceNameFBD_HM_Character19: start 152, 8 bit, little-endian, data-type-policy=OVERRIDE, base-type=uint8, compu {phys=raw}, range phys 0..252
          signal StatusBLEDeviceNameFBD_HM_Character20: start 160, 8 bit, little-endian, data-type-policy=OVERRIDE, base-type=uint8, compu {phys=raw}, range phys 0..252
          signal StatusBLEDeviceNameFBD_HM_Character21: start 168, 8 bit, little-endian, data-type-policy=OVERRIDE, base-type=uint8, compu {phys=raw}, range phys 0..252
          signal StatusBLEDeviceNameFBD_HM_Character22: start 176, 8 bit, little-endian, data-type-policy=OVERRIDE, base-type=uint8, compu {phys=raw}, range phys 0..252
          signal StatusBLEDeviceNameFBD_HM_Character23: start 184, 8 bit, little-endian, data-type-policy=OVERRIDE, base-type=uint8, compu {phys=raw}, range phys 0..252
          signal StatusBLEDeviceNameFBD_HM_Character24: start 192, 8 bit, little-endian, data-type-policy=OVERRIDE, base-type=uint8, compu {phys=raw}, range phys 0..252
          signal StatusBLEDeviceNameFBD_HM_Character25: start 200, 8 bit, little-endian, data-type-policy=OVERRIDE, base-type=uint8, compu {phys=raw}, range phys 0..252
          signal StatusBLEDeviceNameFBD_HM_Character26: start 208, 8 bit, little-endian, data-type-policy=OVERRIDE, base-type=uint8, compu {phys=raw}, range phys 0..252
          signal StatusBLEDeviceNameFBD_HM_Character27: start 216, 8 bit, little-endian, data-type-policy=OVERRIDE, base-type=uint8, compu {phys=raw}, range phys 0..252
          signal StatusBLEDeviceNameFBD_HM_Character28: start 224, 8 bit, little-endian, data-type-policy=OVERRIDE, base-type=uint8, compu {phys=raw}, range phys 0..252
          signal StatusBLEDeviceNameFBD_HM_Character29: start 232, 8 bit, little-endian, data-type-policy=OVERRIDE, base-type=uint8, compu {phys=raw}, range phys 0..252
      frame StatusBLEDeviceNameFBD_HR: id 0x291, frame-length=32, can-addressing-mode=STANDARD, can-frame-rx-behavior=CAN-FD, can-frame-tx-behavior=CAN-FD
        pdu StatusBLEDeviceNameFBD_HR: length=32, unused-bit-pattern=0
          signal StatusBLEDeviceNameFBD_HR_Character00: start 0, 8 bit, little-endian, data-type-policy=OVERRIDE, base-type=uint8, compu {phys=raw}, range phys 0..252
          signal StatusBLEDeviceNameFBD_HR_Character01: start 8, 8 bit, little-endian, data-type-policy=OVERRIDE, base-type=uint8, compu {phys=raw}, range phys 0..252
          signal StatusBLEDeviceNameFBD_HR_Character02: start 16, 8 bit, little-endian, data-type-policy=OVERRIDE, base-type=uint8, compu {phys=raw}, range phys 0..252
          signal StatusBLEDeviceNameFBD_HR_Character03: start 24, 8 bit, little-endian, data-type-policy=OVERRIDE, base-type=uint8, compu {phys=raw}, range phys 0..252
          signal StatusBLEDeviceNameFBD_HR_Character04: start 32, 8 bit, little-endian, data-type-policy=OVERRIDE, base-type=uint8, compu {phys=raw}, range phys 0..252
          signal StatusBLEDeviceNameFBD_HR_Character05: start 40, 8 bit, little-endian, data-type-policy=OVERRIDE, base-type=uint8, compu {phys=raw}, range phys 0..252
          signal StatusBLEDeviceNameFBD_HR_Character06: start 48, 8 bit, little-endian, data-type-policy=OVERRIDE, base-type=uint8, compu {phys=raw}, range phys 0..252
          signal StatusBLEDeviceNameFBD_HR_Character07: start 56, 8 bit, little-endian, data-type-policy=OVERRIDE, base-type=uint8, compu {phys=raw}, range phys 0..252
          signal StatusBLEDeviceNameFBD_HR_Character08: start 64, 8 bit, little-endian, data-type-policy=OVERRIDE, base-type=uint8, compu {phys=raw}, range phys 0..252
          signal StatusBLEDeviceNameFBD_HR_Character09: start 72, 8 bit, little-endian, data-type-policy=OVERRIDE, base-type=uint8, compu {phys=raw}, range phys 0..252
          signal StatusBLEDeviceNameFBD_HR_Character10: start 80, 8 bit, little-endian, data-type-policy=OVERRIDE, base-type=uint8, compu {phys=raw}, range phys 0..252
          signal StatusBLEDeviceNameFBD_HR_Character11: start 88, 8 bit, little-endian, data-type-policy=OVERRIDE, base-type=uint8, compu {phys=raw}, range phys 0..252
          signal StatusBLEDeviceNameFBD_HR_Character12: start 96, 8 bit, little-endian, data-type-policy=OVERRIDE, base-type=uint8, compu {phys=raw}, range phys 0..252
          signal StatusBLEDeviceNameFBD_HR_Character13: start 104, 8 bit, little-endian, data-type-policy=OVERRIDE, base-type=uint8, compu {phys=raw}, range phys 0..252
          signal StatusBLEDeviceNameFBD_HR_Character14: start 112, 8 bit, little-endian, data-type-policy=OVERRIDE, base-type=uint8, compu {phys=raw}, range phys 0..252
          signal StatusBLEDeviceNameFBD_HR_Character15: start 120, 8 bit, little-endian, data-type-policy=OVERRIDE, base-type=uint8, compu {phys=raw}, range phys 0..252
          signal StatusBLEDeviceNameFBD_HR_Character16: start 128, 8 bit, little-endian, data-type-policy=OVERRIDE, base-type=uint8, compu {phys=raw}, range phys 0..252
          signal StatusBLEDeviceNameFBD_HR_Character17: start 136, 8 bit, little-endian, data-type-policy=OVERRIDE, base-type=uint8, compu {phys=raw}, range phys 0..252
          signal StatusBLEDeviceNameFBD_HR_Character18: start 144, 8 bit, little-endian, data-type-policy=OVERRIDE, base-type=uint8, compu {phys=raw}, range phys 0..252
          signal StatusBLEDeviceNameFBD_HR_Character19: start 152, 8 bit, little-endian, data-type-policy=OVERRIDE, base-type=uint8, compu {phys=raw}, range phys 0..252
          signal StatusBLEDeviceNameFBD_HR_Character20: start 160, 8 bit, little-endian, data-type-policy=OVERRIDE, base-type=uint8, compu {phys=raw}, range phys 0..252
          signal StatusBLEDeviceNameFBD_HR_Character21: start 168, 8 bit, little-endian, data-type-policy=OVERRIDE, base-type=uint8, compu {phys=raw}, range phys 0..252
          signal StatusBLEDeviceNameFBD_HR_Character22: start 176, 8 bit, little-endian, data-type-policy=OVERRIDE, base-type=uint8, compu {phys=raw}, range phys 0..252
          signal StatusBLEDeviceNameFBD_HR_Character23: start 184, 8 bit, little-endian, data-type-policy=OVERRIDE, base-type=uint8, compu {phys=raw}, range phys 0..252
          signal StatusBLEDeviceNameFBD_HR_Character24: start 192, 8 bit, little-endian, data-type-policy=OVERRIDE, base-type=uint8, compu {phys=raw}, range phys 0..252
          signal StatusBLEDeviceNameFBD_HR_Character25: start 200, 8 bit, little-endian, data-type-policy=OVERRIDE, base-type=uint8, compu {phys=raw}, range phys 0..252
          signal StatusBLEDeviceNameFBD_HR_Character26: start 208, 8 bit, little-endian, data-type-policy=OVERRIDE, base-type=uint8, compu {phys=raw}, range phys 0..252
          signal StatusBLEDeviceNameFBD_HR_Character27: start 216, 8 bit, little-endian, data-type-policy=OVERRIDE, base-type=uint8, compu {phys=raw}, range phys 0..252
          signal StatusBLEDeviceNameFBD_HR_Character28: start 224, 8 bit, little-endian, data-type-policy=OVERRIDE, base-type=uint8, compu {phys=raw}, range phys 0..252
          signal StatusBLEDeviceNameFBD_HR_Character29: start 232, 8 bit, little-endian, data-type-policy=OVERRIDE, base-type=uint8, compu {phys=raw}, range phys 0..252
      frame StatusBLEDeviceNameFBD_Miko: id 0x28C, frame-length=32, can-addressing-mode=STANDARD, can-frame-rx-behavior=CAN-FD, can-frame-tx-behavior=CAN-FD
        pdu StatusBLEDeviceNameFBD_Miko: length=32, unused-bit-pattern=0
          signal StatusBLEDeviceNameFBD_Miko_Character00: start 0, 8 bit, little-endian, data-type-policy=OVERRIDE, base-type=uint8, compu {phys=raw}, range phys 0..252
          signal StatusBLEDeviceNameFBD_Miko_Character01: start 8, 8 bit, little-endian, data-type-policy=OVERRIDE, base-type=uint8, compu {phys=raw}, range phys 0..252
          signal StatusBLEDeviceNameFBD_Miko_Character02: start 16, 8 bit, little-endian, data-type-policy=OVERRIDE, base-type=uint8, compu {phys=raw}, range phys 0..252
          signal StatusBLEDeviceNameFBD_Miko_Character03: start 24, 8 bit, little-endian, data-type-policy=OVERRIDE, base-type=uint8, compu {phys=raw}, range phys 0..252
          signal StatusBLEDeviceNameFBD_Miko_Character04: start 32, 8 bit, little-endian, data-type-policy=OVERRIDE, base-type=uint8, compu {phys=raw}, range phys 0..252
          signal StatusBLEDeviceNameFBD_Miko_Character05: start 40, 8 bit, little-endian, data-type-policy=OVERRIDE, base-type=uint8, compu {phys=raw}, range phys 0..252
          signal StatusBLEDeviceNameFBD_Miko_Character06: start 48, 8 bit, little-endian, data-type-policy=OVERRIDE, base-type=uint8, compu {phys=raw}, range phys 0..252
          signal StatusBLEDeviceNameFBD_Miko_Character07: start 56, 8 bit, little-endian, data-type-policy=OVERRIDE, base-type=uint8, compu {phys=raw}, range phys 0..252
          signal StatusBLEDeviceNameFBD_Miko_Character08: start 64, 8 bit, little-endian, data-type-policy=OVERRIDE, base-type=uint8, compu {phys=raw}, range phys 0..252
          signal StatusBLEDeviceNameFBD_Miko_Character09: start 72, 8 bit, little-endian, data-type-policy=OVERRIDE, base-type=uint8, compu {phys=raw}, range phys 0..252
          signal StatusBLEDeviceNameFBD_Miko_Character10: start 80, 8 bit, little-endian, data-type-policy=OVERRIDE, base-type=uint8, compu {phys=raw}, range phys 0..252
          signal StatusBLEDeviceNameFBD_Miko_Character11: start 88, 8 bit, little-endian, data-type-policy=OVERRIDE, base-type=uint8, compu {phys=raw}, range phys 0..252
          signal StatusBLEDeviceNameFBD_Miko_Character12: start 96, 8 bit, little-endian, data-type-policy=OVERRIDE, base-type=uint8, compu {phys=raw}, range phys 0..252
          signal StatusBLEDeviceNameFBD_Miko_Character13: start 104, 8 bit, little-endian, data-type-policy=OVERRIDE, base-type=uint8, compu {phys=raw}, range phys 0..252
          signal StatusBLEDeviceNameFBD_Miko_Character14: start 112, 8 bit, little-endian, data-type-policy=OVERRIDE, base-type=uint8, compu {phys=raw}, range phys 0..252
          signal StatusBLEDeviceNameFBD_Miko_Character15: start 120, 8 bit, little-endian, data-type-policy=OVERRIDE, base-type=uint8, compu {phys=raw}, range phys 0..252
          signal StatusBLEDeviceNameFBD_Miko_Character16: start 128, 8 bit, little-endian, data-type-policy=OVERRIDE, base-type=uint8, compu {phys=raw}, range phys 0..252
          signal StatusBLEDeviceNameFBD_Miko_Character17: start 136, 8 bit, little-endian, data-type-policy=OVERRIDE, base-type=uint8, compu {phys=raw}, range phys 0..252
          signal StatusBLEDeviceNameFBD_Miko_Character18: start 144, 8 bit, little-endian, data-type-policy=OVERRIDE, base-type=uint8, compu {phys=raw}, range phys 0..252
          signal StatusBLEDeviceNameFBD_Miko_Character19: start 152, 8 bit, little-endian, data-type-policy=OVERRIDE, base-type=uint8, compu {phys=raw}, range phys 0..252
          signal StatusBLEDeviceNameFBD_Miko_Character20: start 160, 8 bit, little-endian, data-type-policy=OVERRIDE, base-type=uint8, compu {phys=raw}, range phys 0..252
          signal StatusBLEDeviceNameFBD_Miko_Character21: start 168, 8 bit, little-endian, data-type-policy=OVERRIDE, base-type=uint8, compu {phys=raw}, range phys 0..252
          signal StatusBLEDeviceNameFBD_Miko_Character22: start 176, 8 bit, little-endian, data-type-policy=OVERRIDE, base-type=uint8, compu {phys=raw}, range phys 0..252
          signal StatusBLEDeviceNameFBD_Miko_Character23: start 184, 8 bit, little-endian, data-type-policy=OVERRIDE, base-type=uint8, compu {phys=raw}, range phys 0..252
          signal StatusBLEDeviceNameFBD_Miko_Character24: start 192, 8 bit, little-endian, data-type-policy=OVERRIDE, base-type=uint8, compu {phys=raw}, range phys 0..252
          signal StatusBLEDeviceNameFBD_Miko_Character25: start 200, 8 bit, little-endian, data-type-policy=OVERRIDE, base-type=uint8, compu {phys=raw}, range phys 0..252
          signal StatusBLEDeviceNameFBD_Miko_Character26: start 208, 8 bit, little-endian, data-type-policy=OVERRIDE, base-type=uint8, compu {phys=raw}, range phys 0..252
          signal StatusBLEDeviceNameFBD_Miko_Character27: start 216, 8 bit, little-endian, data-type-policy=OVERRIDE, base-type=uint8, compu {phys=raw}, range phys 0..252
          signal StatusBLEDeviceNameFBD_Miko_Character28: start 224, 8 bit, little-endian, data-type-policy=OVERRIDE, base-type=uint8, compu {phys=raw}, range phys 0..252
          signal StatusBLEDeviceNameFBD_Miko_Character29: start 232, 8 bit, little-endian, data-type-policy=OVERRIDE, base-type=uint8, compu {phys=raw}, range phys 0..252
      frame StatusBLEDeviceNameFBD_MM: id 0x294, frame-length=32, can-addressing-mode=STANDARD, can-frame-rx-behavior=CAN-FD, can-frame-tx-behavior=CAN-FD
        pdu StatusBLEDeviceNameFBD_MM: length=32, unused-bit-pattern=0
          signal StatusBLEDeviceNameFBD_MM_Address: start 0, 16 bit, little-endian, data-type-policy=OVERRIDE, compu {phys=raw}
          signal StatusBLEDeviceNameFBD_MM_Character00: start 16, 8 bit, little-endian, data-type-policy=OVERRIDE, base-type=uint8, compu {phys=raw}, range phys 0..252
          signal StatusBLEDeviceNameFBD_MM_Character01: start 24, 8 bit, little-endian, data-type-policy=OVERRIDE, base-type=uint8, compu {phys=raw}, range phys 0..252
          signal StatusBLEDeviceNameFBD_MM_Character02: start 32, 8 bit, little-endian, data-type-policy=OVERRIDE, base-type=uint8, compu {phys=raw}, range phys 0..252
          signal StatusBLEDeviceNameFBD_MM_Character03: start 40, 8 bit, little-endian, data-type-policy=OVERRIDE, base-type=uint8, compu {phys=raw}, range phys 0..252
          signal StatusBLEDeviceNameFBD_MM_Character04: start 48, 8 bit, little-endian, data-type-policy=OVERRIDE, base-type=uint8, compu {phys=raw}, range phys 0..252
          signal StatusBLEDeviceNameFBD_MM_Character05: start 56, 8 bit, little-endian, data-type-policy=OVERRIDE, base-type=uint8, compu {phys=raw}, range phys 0..252
          signal StatusBLEDeviceNameFBD_MM_Character06: start 64, 8 bit, little-endian, data-type-policy=OVERRIDE, base-type=uint8, compu {phys=raw}, range phys 0..252
          signal StatusBLEDeviceNameFBD_MM_Character07: start 72, 8 bit, little-endian, data-type-policy=OVERRIDE, base-type=uint8, compu {phys=raw}, range phys 0..252
          signal StatusBLEDeviceNameFBD_MM_Character08: start 80, 8 bit, little-endian, data-type-policy=OVERRIDE, base-type=uint8, compu {phys=raw}, range phys 0..252
          signal StatusBLEDeviceNameFBD_MM_Character09: start 88, 8 bit, little-endian, data-type-policy=OVERRIDE, base-type=uint8, compu {phys=raw}, range phys 0..252
          signal StatusBLEDeviceNameFBD_MM_Character10: start 96, 8 bit, little-endian, data-type-policy=OVERRIDE, base-type=uint8, compu {phys=raw}, range phys 0..252
          signal StatusBLEDeviceNameFBD_MM_Character11: start 104, 8 bit, little-endian, data-type-policy=OVERRIDE, base-type=uint8, compu {phys=raw}, range phys 0..252
          signal StatusBLEDeviceNameFBD_MM_Character12: start 112, 8 bit, little-endian, data-type-policy=OVERRIDE, base-type=uint8, compu {phys=raw}, range phys 0..252
          signal StatusBLEDeviceNameFBD_MM_Character13: start 120, 8 bit, little-endian, data-type-policy=OVERRIDE, base-type=uint8, compu {phys=raw}, range phys 0..252
          signal StatusBLEDeviceNameFBD_MM_Character14: start 128, 8 bit, little-endian, data-type-policy=OVERRIDE, base-type=uint8, compu {phys=raw}, range phys 0..252
          signal StatusBLEDeviceNameFBD_MM_Character15: start 136, 8 bit, little-endian, data-type-policy=OVERRIDE, base-type=uint8, compu {phys=raw}, range phys 0..252
          signal StatusBLEDeviceNameFBD_MM_Character16: start 144, 8 bit, little-endian, data-type-policy=OVERRIDE, base-type=uint8, compu {phys=raw}, range phys 0..252
          signal StatusBLEDeviceNameFBD_MM_Character17: start 152, 8 bit, little-endian, data-type-policy=OVERRIDE, base-type=uint8, compu {phys=raw}, range phys 0..252
          signal StatusBLEDeviceNameFBD_MM_Character18: start 160, 8 bit, little-endian, data-type-policy=OVERRIDE, base-type=uint8, compu {phys=raw}, range phys 0..252
          signal StatusBLEDeviceNameFBD_MM_Character19: start 168, 8 bit, little-endian, data-type-policy=OVERRIDE, base-type=uint8, compu {phys=raw}, range phys 0..252
          signal StatusBLEDeviceNameFBD_MM_Character20: start 176, 8 bit, little-endian, data-type-policy=OVERRIDE, base-type=uint8, compu {phys=raw}, range phys 0..252
          signal StatusBLEDeviceNameFBD_MM_Character21: start 184, 8 bit, little-endian, data-type-policy=OVERRIDE, base-type=uint8, compu {phys=raw}, range phys 0..252
          signal StatusBLEDeviceNameFBD_MM_Character22: start 192, 8 bit, little-endian, data-type-policy=OVERRIDE, base-type=uint8, compu {phys=raw}, range phys 0..252
          signal StatusBLEDeviceNameFBD_MM_Character23: start 200, 8 bit, little-endian, data-type-policy=OVERRIDE, base-type=uint8, compu {phys=raw}, range phys 0..252
          signal StatusBLEDeviceNameFBD_MM_Character24: start 208, 8 bit, little-endian, data-type-policy=OVERRIDE, base-type=uint8, compu {phys=raw}, range phys 0..252
          signal StatusBLEDeviceNameFBD_MM_Character25: start 216, 8 bit, little-endian, data-type-policy=OVERRIDE, base-type=uint8, compu {phys=raw}, range phys 0..252
          signal StatusBLEDeviceNameFBD_MM_Character26: start 224, 8 bit, little-endian, data-type-policy=OVERRIDE, base-type=uint8, compu {phys=raw}, range phys 0..252
          signal StatusBLEDeviceNameFBD_MM_Character27: start 232, 8 bit, little-endian, data-type-policy=OVERRIDE, base-type=uint8, compu {phys=raw}, range phys 0..252
          signal StatusBLEDeviceNameFBD_MM_Character28: start 240, 8 bit, little-endian, data-type-policy=OVERRIDE, base-type=uint8, compu {phys=raw}, range phys 0..252
          signal StatusBLEDeviceNameFBD_MM_Character29: start 248, 8 bit, little-endian, data-type-policy=OVERRIDE, base-type=uint8, compu {phys=raw}, range phys 0..252
      frame StatusBLEDeviceNameFBD_Trunk: id 0x28D, frame-length=32, can-addressing-mode=STANDARD, can-frame-rx-behavior=CAN-FD, can-frame-tx-behavior=CAN-FD
        pdu StatusBLEDeviceNameFBD_Trunk: length=32, unused-bit-pattern=0
          signal StatusBLEDeviceNameFBD_Trunk_Character00: start 0, 8 bit, little-endian, data-type-policy=OVERRIDE, base-type=uint8, compu {phys=raw}, range phys 0..252
          signal StatusBLEDeviceNameFBD_Trunk_Character01: start 8, 8 bit, little-endian, data-type-policy=OVERRIDE, base-type=uint8, compu {phys=raw}, range phys 0..252
          signal StatusBLEDeviceNameFBD_Trunk_Character02: start 16, 8 bit, little-endian, data-type-policy=OVERRIDE, base-type=uint8, compu {phys=raw}, range phys 0..252
          signal StatusBLEDeviceNameFBD_Trunk_Character03: start 24, 8 bit, little-endian, data-type-policy=OVERRIDE, base-type=uint8, compu {phys=raw}, range phys 0..252
          signal StatusBLEDeviceNameFBD_Trunk_Character04: start 32, 8 bit, little-endian, data-type-policy=OVERRIDE, base-type=uint8, compu {phys=raw}, range phys 0..252
          signal StatusBLEDeviceNameFBD_Trunk_Character05: start 40, 8 bit, little-endian, data-type-policy=OVERRIDE, base-type=uint8, compu {phys=raw}, range phys 0..252
          signal StatusBLEDeviceNameFBD_Trunk_Character06: start 48, 8 bit, little-endian, data-type-policy=OVERRIDE, base-type=uint8, compu {phys=raw}, range phys 0..252
          signal StatusBLEDeviceNameFBD_Trunk_Character07: start 56, 8 bit, little-endian, data-type-policy=OVERRIDE, base-type=uint8, compu {phys=raw}, range phys 0..252
          signal StatusBLEDeviceNameFBD_Trunk_Character08: start 64, 8 bit, little-endian, data-type-policy=OVERRIDE, base-type=uint8, compu {phys=raw}, range phys 0..252
          signal StatusBLEDeviceNameFBD_Trunk_Character09: start 72, 8 bit, little-endian, data-type-policy=OVERRIDE, base-type=uint8, compu {phys=raw}, range phys 0..252
          signal StatusBLEDeviceNameFBD_Trunk_Character10: start 80, 8 bit, little-endian, data-type-policy=OVERRIDE, base-type=uint8, compu {phys=raw}, range phys 0..252
          signal StatusBLEDeviceNameFBD_Trunk_Character11: start 88, 8 bit, little-endian, data-type-policy=OVERRIDE, base-type=uint8, compu {phys=raw}, range phys 0..252
          signal StatusBLEDeviceNameFBD_Trunk_Character12: start 96, 8 bit, little-endian, data-type-policy=OVERRIDE, base-type=uint8, compu {phys=raw}, range phys 0..252
          signal StatusBLEDeviceNameFBD_Trunk_Character13: start 104, 8 bit, little-endian, data-type-policy=OVERRIDE, base-type=uint8, compu {phys=raw}, range phys 0..252
          signal StatusBLEDeviceNameFBD_Trunk_Character14: start 112, 8 bit, little-endian, data-type-policy=OVERRIDE, base-type=uint8, compu {phys=raw}, range phys 0..252
          signal StatusBLEDeviceNameFBD_Trunk_Character15: start 120, 8 bit, little-endian, data-type-policy=OVERRIDE, base-type=uint8, compu {phys=raw}, range phys 0..252
          signal StatusBLEDeviceNameFBD_Trunk_Character16: start 128, 8 bit, little-endian, data-type-policy=OVERRIDE, base-type=uint8, compu {phys=raw}, range phys 0..252
          signal StatusBLEDeviceNameFBD_Trunk_Character17: start 136, 8 bit, little-endian, data-type-policy=OVERRIDE, base-type=uint8, compu {phys=raw}, range phys 0..252
          signal StatusBLEDeviceNameFBD_Trunk_Character18: start 144, 8 bit, little-endian, data-type-policy=OVERRIDE, base-type=uint8, compu {phys=raw}, range phys 0..252
          signal StatusBLEDeviceNameFBD_Trunk_Character19: start 152, 8 bit, little-endian, data-type-policy=OVERRIDE, base-type=uint8, compu {phys=raw}, range phys 0..252
          signal StatusBLEDeviceNameFBD_Trunk_Character20: start 160, 8 bit, little-endian, data-type-policy=OVERRIDE, base-type=uint8, compu {phys=raw}, range phys 0..252
          signal StatusBLEDeviceNameFBD_Trunk_Character21: start 168, 8 bit, little-endian, data-type-policy=OVERRIDE, base-type=uint8, compu {phys=raw}, range phys 0..252
          signal StatusBLEDeviceNameFBD_Trunk_Character22: start 176, 8 bit, little-endian, data-type-policy=OVERRIDE, base-type=uint8, compu {phys=raw}, range phys 0..252
          signal StatusBLEDeviceNameFBD_Trunk_Character23: start 184, 8 bit, little-endian, data-type-policy=OVERRIDE, base-type=uint8, compu {phys=raw}, range phys 0..252
          signal StatusBLEDeviceNameFBD_Trunk_Character24: start 192, 8 bit, little-endian, data-type-policy=OVERRIDE, base-type=uint8, compu {phys=raw}, range phys 0..252
          signal StatusBLEDeviceNameFBD_Trunk_Character25: start 200, 8 bit, little-endian, data-type-policy=OVERRIDE, base-type=uint8, compu {phys=raw}, range phys 0..252
          signal StatusBLEDeviceNameFBD_Trunk_Character26: start 208, 8 bit, little-endian, data-type-policy=OVERRIDE, base-type=uint8, compu {phys=raw}, range phys 0..252
          signal StatusBLEDeviceNameFBD_Trunk_Character27: start 216, 8 bit, little-endian, data-type-policy=OVERRIDE, base-type=uint8, compu {phys=raw}, range phys 0..252
          signal StatusBLEDeviceNameFBD_Trunk_Character28: start 224, 8 bit, little-endian, data-type-policy=OVERRIDE, base-type=uint8, compu {phys=raw}, range phys 0..252
          signal StatusBLEDeviceNameFBD_Trunk_Character29: start 232, 8 bit, little-endian, data-type-policy=OVERRIDE, base-type=uint8, compu {phys=raw}, range phys 0..252
      frame StatusBLEDeviceNameFBD_VL: id 0x28E, frame-length=32, can-addressing-mode=STANDARD, can-frame-rx-behavior=CAN-FD, can-frame-tx-behavior=CAN-FD
        pdu StatusBLEDeviceNameFBD_VL: length=32, unused-bit-pattern=0
          signal StatusBLEDeviceNameFBD_VL_Character00: start 0, 8 bit, little-endian, data-type-policy=OVERRIDE, base-type=uint8, compu {phys=raw}, range phys 0..252
          signal StatusBLEDeviceNameFBD_VL_Character01: start 8, 8 bit, little-endian, data-type-policy=OVERRIDE, base-type=uint8, compu {phys=raw}, range phys 0..252
          signal StatusBLEDeviceNameFBD_VL_Character02: start 16, 8 bit, little-endian, data-type-policy=OVERRIDE, base-type=uint8, compu {phys=raw}, range phys 0..252
          signal StatusBLEDeviceNameFBD_VL_Character03: start 24, 8 bit, little-endian, data-type-policy=OVERRIDE, base-type=uint8, compu {phys=raw}, range phys 0..252
          signal StatusBLEDeviceNameFBD_VL_Character04: start 32, 8 bit, little-endian, data-type-policy=OVERRIDE, base-type=uint8, compu {phys=raw}, range phys 0..252
          signal StatusBLEDeviceNameFBD_VL_Character05: start 40, 8 bit, little-endian, data-type-policy=OVERRIDE, base-type=uint8, compu {phys=raw}, range phys 0..252
          signal StatusBLEDeviceNameFBD_VL_Character06: start 48, 8 bit, little-endian, data-type-policy=OVERRIDE, base-type=uint8, compu {phys=raw}, range phys 0..252
          signal StatusBLEDeviceNameFBD_VL_Character07: start 56, 8 bit, little-endian, data-type-policy=OVERRIDE, base-type=uint8, compu {phys=raw}, range phys 0..252
          signal StatusBLEDeviceNameFBD_VL_Character08: start 64, 8 bit, little-endian, data-type-policy=OVERRIDE, base-type=uint8, compu {phys=raw}, range phys 0..252
          signal StatusBLEDeviceNameFBD_VL_Character09: start 72, 8 bit, little-endian, data-type-policy=OVERRIDE, base-type=uint8, compu {phys=raw}, range phys 0..252
          signal StatusBLEDeviceNameFBD_VL_Character10: start 80, 8 bit, little-endian, data-type-policy=OVERRIDE, base-type=uint8, compu {phys=raw}, range phys 0..252
          signal StatusBLEDeviceNameFBD_VL_Character11: start 88, 8 bit, little-endian, data-type-policy=OVERRIDE, base-type=uint8, compu {phys=raw}, range phys 0..252
          signal StatusBLEDeviceNameFBD_VL_Character12: start 96, 8 bit, little-endian, data-type-policy=OVERRIDE, base-type=uint8, compu {phys=raw}, range phys 0..252
          signal StatusBLEDeviceNameFBD_VL_Character13: start 104, 8 bit, little-endian, data-type-policy=OVERRIDE, base-type=uint8, compu {phys=raw}, range phys 0..252
          signal StatusBLEDeviceNameFBD_VL_Character14: start 112, 8 bit, little-endian, data-type-policy=OVERRIDE, base-type=uint8, compu {phys=raw}, range phys 0..252
          signal StatusBLEDeviceNameFBD_VL_Character15: start 120, 8 bit, little-endian, data-type-policy=OVERRIDE, base-type=uint8, compu {phys=raw}, range phys 0..252
          signal StatusBLEDeviceNameFBD_VL_Character16: start 128, 8 bit, little-endian, data-type-policy=OVERRIDE, base-type=uint8, compu {phys=raw}, range phys 0..252
          signal StatusBLEDeviceNameFBD_VL_Character17: start 136, 8 bit, little-endian, data-type-policy=OVERRIDE, base-type=uint8, compu {phys=raw}, range phys 0..252
          signal StatusBLEDeviceNameFBD_VL_Character18: start 144, 8 bit, little-endian, data-type-policy=OVERRIDE, base-type=uint8, compu {phys=raw}, range phys 0..252
          signal StatusBLEDeviceNameFBD_VL_Character19: start 152, 8 bit, little-endian, data-type-policy=OVERRIDE, base-type=uint8, compu {phys=raw}, range phys 0..252
          signal StatusBLEDeviceNameFBD_VL_Character20: start 160, 8 bit, little-endian, data-type-policy=OVERRIDE, base-type=uint8, compu {phys=raw}, range phys 0..252
          signal StatusBLEDeviceNameFBD_VL_Character21: start 168, 8 bit, little-endian, data-type-policy=OVERRIDE, base-type=uint8, compu {phys=raw}, range phys 0..252
          signal StatusBLEDeviceNameFBD_VL_Character22: start 176, 8 bit, little-endian, data-type-policy=OVERRIDE, base-type=uint8, compu {phys=raw}, range phys 0..252
          signal StatusBLEDeviceNameFBD_VL_Character23: start 184, 8 bit, little-endian, data-type-policy=OVERRIDE, base-type=uint8, compu {phys=raw}, range phys 0..252
          signal StatusBLEDeviceNameFBD_VL_Character24: start 192, 8 bit, little-endian, data-type-policy=OVERRIDE, base-type=uint8, compu {phys=raw}, range phys 0..252
          signal StatusBLEDeviceNameFBD_VL_Character25: start 200, 8 bit, little-endian, data-type-policy=OVERRIDE, base-type=uint8, compu {phys=raw}, range phys 0..252
          signal StatusBLEDeviceNameFBD_VL_Character26: start 208, 8 bit, little-endian, data-type-policy=OVERRIDE, base-type=uint8, compu {phys=raw}, range phys 0..252
          signal StatusBLEDeviceNameFBD_VL_Character27: start 216, 8 bit, little-endian, data-type-policy=OVERRIDE, base-type=uint8, compu {phys=raw}, range phys 0..252
          signal StatusBLEDeviceNameFBD_VL_Character28: start 224, 8 bit, little-endian, data-type-policy=OVERRIDE, base-type=uint8, compu {phys=raw}, range phys 0..252
          signal StatusBLEDeviceNameFBD_VL_Character29: start 232, 8 bit, little-endian, data-type-policy=OVERRIDE, base-type=uint8, compu {phys=raw}, range phys 0..252
      frame StatusBLEDeviceNameFBD_VM: id 0x28A, frame-length=32, can-addressing-mode=STANDARD, can-frame-rx-behavior=CAN-FD, can-frame-tx-behavior=CAN-FD
        pdu StatusBLEDeviceNameFBD_VM: length=32, unused-bit-pattern=0
          signal StatusBLEDeviceNameFBD_VM_Character00: start 0, 8 bit, little-endian, data-type-policy=OVERRIDE, base-type=uint8, compu {phys=raw}, range phys 0..252
          signal StatusBLEDeviceNameFBD_VM_Character01: start 8, 8 bit, little-endian, data-type-policy=OVERRIDE, base-type=uint8, compu {phys=raw}, range phys 0..252
          signal StatusBLEDeviceNameFBD_VM_Character02: start 16, 8 bit, little-endian, data-type-policy=OVERRIDE, base-type=uint8, compu {phys=raw}, range phys 0..252
          signal StatusBLEDeviceNameFBD_VM_Character03: start 24, 8 bit, little-endian, data-type-policy=OVERRIDE, base-type=uint8, compu {phys=raw}, range phys 0..252
          signal StatusBLEDeviceNameFBD_VM_Character04: start 32, 8 bit, little-endian, data-type-policy=OVERRIDE, base-type=uint8, compu {phys=raw}, range phys 0..252
          signal StatusBLEDeviceNameFBD_VM_Character05: start 40, 8 bit, little-endian, data-type-policy=OVERRIDE, base-type=uint8, compu {phys=raw}, range phys 0..252
          signal StatusBLEDeviceNameFBD_VM_Character06: start 48, 8 bit, little-endian, data-type-policy=OVERRIDE, base-type=uint8, compu {phys=raw}, range phys 0..252
          signal StatusBLEDeviceNameFBD_VM_Character07: start 56, 8 bit, little-endian, data-type-policy=OVERRIDE, base-type=uint8, compu {phys=raw}, range phys 0..252
          signal StatusBLEDeviceNameFBD_VM_Character08: start 64, 8 bit, little-endian, data-type-policy=OVERRIDE, base-type=uint8, compu {phys=raw}, range phys 0..252
          signal StatusBLEDeviceNameFBD_VM_Character09: start 72, 8 bit, little-endian, data-type-policy=OVERRIDE, base-type=uint8, compu {phys=raw}, range phys 0..252
          signal StatusBLEDeviceNameFBD_VM_Character10: start 80, 8 bit, little-endian, data-type-policy=OVERRIDE, base-type=uint8, compu {phys=raw}, range phys 0..252
          signal StatusBLEDeviceNameFBD_VM_Character11: start 88, 8 bit, little-endian, data-type-policy=OVERRIDE, base-type=uint8, compu {phys=raw}, range phys 0..252
          signal StatusBLEDeviceNameFBD_VM_Character12: start 96, 8 bit, little-endian, data-type-policy=OVERRIDE, base-type=uint8, compu {phys=raw}, range phys 0..252
          signal StatusBLEDeviceNameFBD_VM_Character13: start 104, 8 bit, little-endian, data-type-policy=OVERRIDE, base-type=uint8, compu {phys=raw}, range phys 0..252
          signal StatusBLEDeviceNameFBD_VM_Character14: start 112, 8 bit, little-endian, data-type-policy=OVERRIDE, base-type=uint8, compu {phys=raw}, range phys 0..252
          signal StatusBLEDeviceNameFBD_VM_Character15: start 120, 8 bit, little-endian, data-type-policy=OVERRIDE, base-type=uint8, compu {phys=raw}, range phys 0..252
          signal StatusBLEDeviceNameFBD_VM_Character16: start 128, 8 bit, little-endian, data-type-policy=OVERRIDE, base-type=uint8, compu {phys=raw}, range phys 0..252
          signal StatusBLEDeviceNameFBD_VM_Character17: start 136, 8 bit, little-endian, data-type-policy=OVERRIDE, base-type=uint8, compu {phys=raw}, range phys 0..252
          signal StatusBLEDeviceNameFBD_VM_Character18: start 144, 8 bit, little-endian, data-type-policy=OVERRIDE, base-type=uint8, compu {phys=raw}, range phys 0..252
          signal StatusBLEDeviceNameFBD_VM_Character19: start 152, 8 bit, little-endian, data-type-policy=OVERRIDE, base-type=uint8, compu {phys=raw}, range phys 0..252
          signal StatusBLEDeviceNameFBD_VM_Character20: start 160, 8 bit, little-endian, data-type-policy=OVERRIDE, base-type=uint8, compu {phys=raw}, range phys 0..252
          signal StatusBLEDeviceNameFBD_VM_Character21: start 168, 8 bit, little-endian, data-type-policy=OVERRIDE, base-type=uint8, compu {phys=raw}, range phys 0..252
          signal StatusBLEDeviceNameFBD_VM_Character22: start 176, 8 bit, little-endian, data-type-policy=OVERRIDE, base-type=uint8, compu {phys=raw}, range phys 0..252
          signal StatusBLEDeviceNameFBD_VM_Character23: start 184, 8 bit, little-endian, data-type-policy=OVERRIDE, base-type=uint8, compu {phys=raw}, range phys 0..252
          signal StatusBLEDeviceNameFBD_VM_Character24: start 192, 8 bit, little-endian, data-type-policy=OVERRIDE, base-type=uint8, compu {phys=raw}, range phys 0..252
          signal StatusBLEDeviceNameFBD_VM_Character25: start 200, 8 bit, little-endian, data-type-policy=OVERRIDE, base-type=uint8, compu {phys=raw}, range phys 0..252
          signal StatusBLEDeviceNameFBD_VM_Character26: start 208, 8 bit, little-endian, data-type-policy=OVERRIDE, base-type=uint8, compu {phys=raw}, range phys 0..252
          signal StatusBLEDeviceNameFBD_VM_Character27: start 216, 8 bit, little-endian, data-type-policy=OVERRIDE, base-type=uint8, compu {phys=raw}, range phys 0..252
          signal StatusBLEDeviceNameFBD_VM_Character28: start 224, 8 bit, little-endian, data-type-policy=OVERRIDE, base-type=uint8, compu {phys=raw}, range phys 0..252
          signal StatusBLEDeviceNameFBD_VM_Character29: start 232, 8 bit, little-endian, data-type-policy=OVERRIDE, base-type=uint8, compu {phys=raw}, range phys 0..252
